VERSION "dbc-export 1 2026.26.6.5"

NS_ :

BS_:

BU_: ADSP APB APP APS APSB BB BMS CC CMP CMPD CP DAS DI DIF DIR DPB EPAS3P EPAS3S EPASTP EPASTS EPBL EPBR ESP EVSE FC GTW HCML HCMR HVP IBST ICR IDB LS OCS1P PARK PCS PCS2 PM PMF PMR PNCD PTC RADC RCM RCM2 RCM3 RCU SCCM SCM SCS SDCR TAS TCU TCU2 TPMS TRCM UI UIS UMC USM V2G VC VCBATT VCBATT0 VCBATT1 VCBATT2 VCCC VCFRONT VCFRONT1 VCFRONT2 VCLEFT VCRIGHT VCSEAT2L VCSEAT2R VCSEC VEH

BO_ 852 TAS_alertMatrix: 8 TAS
 SG_ TAS_matrixIndex M : 0|4@1+ (1,0) [0|15] "" Vector__XXX
 SG_ TAS_a001_WatchdogReset m0 : 4|1@1+ (1,0) [0|1] "" Vector__XXX
 SG_ TAS_a002_PowerLossReset m0 : 5|1@1+ (1,0) [0|1] "" Vector__XXX
 SG_ TAS_a003_SWAssertion m0 : 6|1@1+ (1,0) [0|1] "" Vector__XXX
 SG_ TAS_a012_CPUReset m0 : 15|1@1+ (1,0) [0|1] "" Vector__XXX
 SG_ TAS_a015_NVMMError m0 : 18|1@1+ (1,0) [0|1] "" Vector__XXX
 SG_ TAS_a016_NVMMRecordError m0 : 19|1@1+ (1,0) [0|1] "" Vector__XXX
 SG_ TAS_a021_TaskSchedulerError m0 : 24|1@1+ (1,0) [0|1] "" Vector__XXX
 SG_ TAS_a022_TaskInitError m0 : 25|1@1+ (1,0) [0|1] "" Vector__XXX
 SG_ TAS_a023_rtosResetRequested m0 : 26|1@1+ (1,0) [0|1] "" Vector__XXX
 SG_ TAS_a024_prefetchAbort m0 : 27|1@1+ (1,0) [0|1] "" Vector__XXX
 SG_ TAS_a025_CrashEvent m0 : 28|1@1+ (1,0) [0|1] "" Vector__XXX
 SG_ TAS_a030_PWMerrorFL m0 : 33|1@1+ (1,0) [0|1] "" Vector__XXX
 SG_ TAS_a031_PWMerrorFR m0 : 34|1@1+ (1,0) [0|1] "" Vector__XXX
 SG_ TAS_a032_PWMerrorRL m0 : 35|1@1+ (1,0) [0|1] "" Vector__XXX
 SG_ TAS_a033_PWMerrorRR m0 : 36|1@1+ (1,0) [0|1] "" Vector__XXX
 SG_ TAS_a034_PWMshortFL m0 : 37|1@1+ (1,0) [0|1] "" Vector__XXX
 SG_ TAS_a035_PWMshortFR m0 : 38|1@1+ (1,0) [0|1] "" Vector__XXX
 SG_ TAS_a036_PWMshortRL m0 : 39|1@1+ (1,0) [0|1] "" Vector__XXX
 SG_ TAS_a037_PWMshortRR m0 : 40|1@1+ (1,0) [0|1] "" Vector__XXX
 SG_ TAS_a038_PWMopenFL m0 : 41|1@1+ (1,0) [0|1] "" Vector__XXX
 SG_ TAS_a039_PWMopenFR m0 : 42|1@1+ (1,0) [0|1] "" Vector__XXX
 SG_ TAS_a040_PWMopenRL m0 : 43|1@1+ (1,0) [0|1] "" Vector__XXX
 SG_ TAS_a041_PWMopenRR m0 : 44|1@1+ (1,0) [0|1] "" Vector__XXX
 SG_ TAS_a043_Task1msError m0 : 46|1@1+ (1,0) [0|1] "" Vector__XXX
 SG_ TAS_a044_Task10msError m0 : 47|1@1+ (1,0) [0|1] "" Vector__XXX
 SG_ TAS_a045_Task100msError m0 : 48|1@1+ (1,0) [0|1] "" Vector__XXX
 SG_ TAS_a046_Task1000msError m0 : 49|1@1+ (1,0) [0|1] "" Vector__XXX
 SG_ TAS_a061_XCPConnected m1 : 4|1@1+ (1,0) [0|1] "" Vector__XXX
 SG_ TAS_a062_XCPWasConnected m1 : 5|1@1+ (1,0) [0|1] "" Vector__XXX
 SG_ TAS_a063_abortFault m1 : 6|1@1+ (1,0) [0|1] "" Vector__XXX
 SG_ TAS_a064_abortFaultExt m1 : 7|1@1+ (1,0) [0|1] "" Vector__XXX
 SG_ TAS_a065_ahbWriteFault m1 : 8|1@1+ (1,0) [0|1] "" Vector__XXX
 SG_ TAS_a066_undefinedInstructionAbo m1 : 9|1@1+ (1,0) [0|1] "" Vector__XXX
 SG_ TAS_a067_reservedHandlerAbort m1 : 10|1@1+ (1,0) [0|1] "" Vector__XXX
 SG_ TAS_a070_underVoltage12V m1 : 13|1@1+ (1,0) [0|1] "" Vector__XXX
 SG_ TAS_a071_overVoltage12V m1 : 14|1@1+ (1,0) [0|1] "" Vector__XXX
 SG_ TAS_a072_shortCircuit5VOnBoard m1 : 15|1@1+ (1,0) [0|1] "" Vector__XXX
 SG_ TAS_a073_underVoltage5VOnBoard m1 : 16|1@1+ (1,0) [0|1] "" Vector__XXX
 SG_ TAS_a074_shortCircuit5VOffBoard m1 : 17|1@1+ (1,0) [0|1] "" Vector__XXX
 SG_ TAS_a075_underVoltage5VOffBoard m1 : 18|1@1+ (1,0) [0|1] "" Vector__XXX
 SG_ TAS_a076_overVoltage5VOffBoard m1 : 19|1@1+ (1,0) [0|1] "" Vector__XXX
 SG_ TAS_a077_pressureSigVTooLow m1 : 20|1@1+ (1,0) [0|1] "" Vector__XXX
 SG_ TAS_a078_pressureSigVTooHigh m1 : 21|1@1+ (1,0) [0|1] "" Vector__XXX
 SG_ TAS_a080_shortCircuit5VHeight m1 : 23|1@1+ (1,0) [0|1] "" Vector__XXX
 SG_ TAS_a081_underVoltage5VHeight m1 : 24|1@1+ (1,0) [0|1] "" Vector__XXX
 SG_ TAS_a082_overVoltage5VHeight m1 : 25|1@1+ (1,0) [0|1] "" Vector__XXX
 SG_ TAS_a083_shortCircuit5VAnalog m1 : 26|1@1+ (1,0) [0|1] "" Vector__XXX
 SG_ TAS_a084_underVoltage5VAnalog m1 : 27|1@1+ (1,0) [0|1] "" Vector__XXX
 SG_ TAS_a085_overVoltage5VAnalog m1 : 28|1@1+ (1,0) [0|1] "" Vector__XXX
 SG_ TAS_a086_underVoltage12VSwtchd m1 : 29|1@1+ (1,0) [0|1] "" Vector__XXX
 SG_ TAS_a087_overVoltage12VSwtchd m1 : 30|1@1+ (1,0) [0|1] "" Vector__XXX
 SG_ TAS_a093_OTPError m1 : 36|1@1+ (1,0) [0|1] "" Vector__XXX
 SG_ TAS_a098_VCFRONT_MIA m1 : 41|1@1+ (1,0) [0|1] "" Vector__XXX
 SG_ TAS_a099_UI_MIA m1 : 42|1@1+ (1,0) [0|1] "" Vector__XXX
 SG_ TAS_a100_RCM_MIA m1 : 43|1@1+ (1,0) [0|1] "" Vector__XXX
 SG_ TAS_a101_ESP_MIA m1 : 44|1@1+ (1,0) [0|1] "" Vector__XXX
 SG_ TAS_a102_DI_MIA m1 : 45|1@1+ (1,0) [0|1] "" Vector__XXX
 SG_ TAS_a103_GTW_MIA m1 : 46|1@1+ (1,0) [0|1] "" Vector__XXX
 SG_ TAS_a105_ECUDebugMode m1 : 48|1@1+ (1,0) [0|1] "" Vector__XXX
 SG_ TAS_a106_HighCPULoad m1 : 49|1@1+ (1,0) [0|1] "" Vector__XXX
 SG_ TAS_a107_HighStackUsage m1 : 50|1@1+ (1,0) [0|1] "" Vector__XXX
 SG_ TAS_a150_accelAvgImplausible_FL_ m2 : 33|1@1+ (1,0) [0|1] "" Vector__XXX
 SG_ TAS_a151_accelAvgImplausible_FL_ m2 : 34|1@1+ (1,0) [0|1] "" Vector__XXX
 SG_ TAS_a152_accelAvgImplausible_FL_ m2 : 35|1@1+ (1,0) [0|1] "" Vector__XXX
 SG_ TAS_a153_accelAvgImplausible_FR_ m2 : 36|1@1+ (1,0) [0|1] "" Vector__XXX
 SG_ TAS_a154_accelAvgImplausible_FR_ m2 : 37|1@1+ (1,0) [0|1] "" Vector__XXX
 SG_ TAS_a155_accelAvgImplausible_FR_ m2 : 38|1@1+ (1,0) [0|1] "" Vector__XXX
 SG_ TAS_a156_accelAvgImplausible_RL_ m2 : 39|1@1+ (1,0) [0|1] "" Vector__XXX
 SG_ TAS_a157_accelAvgImplausible_RL_ m2 : 40|1@1+ (1,0) [0|1] "" Vector__XXX
 SG_ TAS_a158_accelAvgImplausible_RL_ m2 : 41|1@1+ (1,0) [0|1] "" Vector__XXX
 SG_ TAS_a159_accelAvgImplausible_RR_ m2 : 42|1@1+ (1,0) [0|1] "" Vector__XXX
 SG_ TAS_a160_accelAvgImplausible_RR_ m2 : 43|1@1+ (1,0) [0|1] "" Vector__XXX
 SG_ TAS_a161_accelAvgImplausible_RR_ m2 : 44|1@1+ (1,0) [0|1] "" Vector__XXX
 SG_ TAS_a164_damperSolenoidMismatch m2 : 47|1@1+ (1,0) [0|1] "" Vector__XXX
 SG_ TAS_a165_damperValveCompFL m2 : 48|1@1+ (1,0) [0|1] "" Vector__XXX
 SG_ TAS_a166_damperValveRbndFL m2 : 49|1@1+ (1,0) [0|1] "" Vector__XXX
 SG_ TAS_a167_damperValveCompFR m2 : 50|1@1+ (1,0) [0|1] "" Vector__XXX
 SG_ TAS_a168_damperValveRbndFR m2 : 51|1@1+ (1,0) [0|1] "" Vector__XXX
 SG_ TAS_a169_damperValveCompRL m2 : 52|1@1+ (1,0) [0|1] "" Vector__XXX
 SG_ TAS_a170_damperValveRbndRL m2 : 53|1@1+ (1,0) [0|1] "" Vector__XXX
 SG_ TAS_a171_damperValveCompRR m2 : 54|1@1+ (1,0) [0|1] "" Vector__XXX
 SG_ TAS_a172_damperValveRbndRR m2 : 55|1@1+ (1,0) [0|1] "" Vector__XXX
 SG_ TAS_a173_staticLeakDetectFL m2 : 56|1@1+ (1,0) [0|1] "" Vector__XXX
 SG_ TAS_a174_staticLeakDetectFR m2 : 57|1@1+ (1,0) [0|1] "" Vector__XXX
 SG_ TAS_a175_staticLeakDetectRL m2 : 58|1@1+ (1,0) [0|1] "" Vector__XXX
 SG_ TAS_a176_staticLeakDetectRR m2 : 59|1@1+ (1,0) [0|1] "" Vector__XXX
 SG_ TAS_a190_a2bFrontAxleFault m3 : 13|1@1+ (1,0) [0|1] "" Vector__XXX
 SG_ TAS_a191_a2bRearAxleFault m3 : 14|1@1+ (1,0) [0|1] "" Vector__XXX
 SG_ TAS_a192_rideHeightObserverDiver m3 : 15|1@1+ (1,0) [0|1] "" Vector__XXX
 SG_ TAS_a193_EPAS3P_MIA m3 : 16|1@1+ (1,0) [0|1] "" Vector__XXX
 SG_ TAS_a194_a2bFrontAxleDataError m3 : 17|1@1+ (1,0) [0|1] "" Vector__XXX
 SG_ TAS_a195_a2bRearAxleDataError m3 : 18|1@1+ (1,0) [0|1] "" Vector__XXX
 SG_ TAS_a196_adaptiveDampingUsingDSP m3 : 19|1@1+ (1,0) [0|1] "" Vector__XXX
 SG_ TAS_a197_invalidAdaptiveModeRequ m3 : 20|1@1+ (1,0) [0|1] "" Vector__XXX
 SG_ TAS_a198_a2bFrontAxleExtendedDis m3 : 21|1@1+ (1,0) [0|1] "" Vector__XXX
 SG_ TAS_a199_a2bRearAxleExtendedDisc m3 : 22|1@1+ (1,0) [0|1] "" Vector__XXX
 SG_ TAS_a200_jackModeActive m3 : 23|1@1+ (1,0) [0|1] "" Vector__XXX
 SG_ TAS_a201_low12VBattery m3 : 24|1@1+ (1,0) [0|1] "" Vector__XXX
 SG_ TAS_a210_outOfRangeCalibration m3 : 33|1@1+ (1,0) [0|1] "" Vector__XXX
 SG_ TAS_a211_noRideHeightCalib m3 : 34|1@1+ (1,0) [0|1] "" Vector__XXX
 SG_ TAS_a213_yellowWarningLamp m3 : 36|1@1+ (1,0) [0|1] "" Vector__XXX
 SG_ TAS_a214_redWarningLamp m3 : 37|1@1+ (1,0) [0|1] "" Vector__XXX
 SG_ TAS_a215_limpHomeMode10 m3 : 38|1@1+ (1,0) [0|1] "" Vector__XXX
 SG_ TAS_a216_limpHomeMode20 m3 : 39|1@1+ (1,0) [0|1] "" Vector__XXX
 SG_ TAS_a217_limpHomeMode30 m3 : 40|1@1+ (1,0) [0|1] "" Vector__XXX
 SG_ TAS_a218_limpHomeMode40 m3 : 41|1@1+ (1,0) [0|1] "" Vector__XXX
 SG_ TAS_a220_exhaustGalleryFault m3 : 43|1@1+ (1,0) [0|1] "" Vector__XXX
 SG_ TAS_a221_valveLeakDetected m3 : 44|1@1+ (1,0) [0|1] "" Vector__XXX
 SG_ TAS_a222_compressorPrefillFault m3 : 45|1@1+ (1,0) [0|1] "" Vector__XXX
 SG_ TAS_a223_blockedAirline m3 : 46|1@1+ (1,0) [0|1] "" Vector__XXX
 SG_ TAS_a224_openAirline m3 : 47|1@1+ (1,0) [0|1] "" Vector__XXX
 SG_ TAS_a225_galleryPressureTooHigh m3 : 48|1@1+ (1,0) [0|1] "" Vector__XXX
 SG_ TAS_a226_PWMfastDetectFL m3 : 49|1@1+ (1,0) [0|1] "" Vector__XXX
 SG_ TAS_a227_PWMfastDetectFR m3 : 50|1@1+ (1,0) [0|1] "" Vector__XXX
 SG_ TAS_a228_PWMfastDetectRL m3 : 51|1@1+ (1,0) [0|1] "" Vector__XXX
 SG_ TAS_a229_PWMfastDetectRR m3 : 52|1@1+ (1,0) [0|1] "" Vector__XXX
 SG_ TAS_a230_notifyGeofence m3 : 53|1@1+ (1,0) [0|1] "" Vector__XXX
 SG_ TAS_a231_notifyRoughRoadRaise m3 : 54|1@1+ (1,0) [0|1] "" Vector__XXX
 SG_ TAS_a232_suspensionTypeMismatch m3 : 55|1@1+ (1,0) [0|1] "" Vector__XXX
 SG_ TAS_a233_compressorStuckOn m3 : 56|1@1+ (1,0) [0|1] "" Vector__XXX
 SG_ TAS_a234_damperHydraulicMismatch m3 : 57|1@1+ (1,0) [0|1] "" Vector__XXX
 SG_ TAS_a240_airSpringLeak m3 : 63|1@1+ (1,0) [0|1] "" Vector__XXX
 SG_ TAS_a284_serviceRunModeActive m4 : 47|1@1+ (1,0) [0|1] "" Vector__XXX
 SG_ TAS_a285_twistSustainedUserVis m4 : 48|1@1+ (1,0) [0|1] "" Vector__XXX
 SG_ TAS_a286_driveCycleStats1 m4 : 49|1@1+ (1,0) [0|1] "" Vector__XXX
 SG_ TAS_a287_driveCycleStats2 m4 : 50|1@1+ (1,0) [0|1] "" Vector__XXX
 SG_ TAS_a288_driveCycleStats3 m4 : 51|1@1+ (1,0) [0|1] "" Vector__XXX
 SG_ TAS_a289_driveCycleStats4 m4 : 52|1@1+ (1,0) [0|1] "" Vector__XXX
 SG_ TAS_a290_twistSustainedAtSpeed m4 : 53|1@1+ (1,0) [0|1] "" Vector__XXX
 SG_ TAS_a291_frontAxleTooHigh m4 : 54|1@1+ (1,0) [0|1] "" Vector__XXX
 SG_ TAS_a292_rearAxleTooHigh m4 : 55|1@1+ (1,0) [0|1] "" Vector__XXX
 SG_ TAS_a293_frontAxleTooLow m4 : 56|1@1+ (1,0) [0|1] "" Vector__XXX
 SG_ TAS_a294_rearAxleTooLow m4 : 57|1@1+ (1,0) [0|1] "" Vector__XXX
 SG_ TAS_a295_targetHeightNotMet m4 : 58|1@1+ (1,0) [0|1] "" Vector__XXX
 SG_ TAS_a296_chassisTypeMismatch m4 : 59|1@1+ (1,0) [0|1] "" Vector__XXX
 SG_ TAS_a297_vinMismatch m4 : 60|1@1+ (1,0) [0|1] "" Vector__XXX
 SG_ TAS_a298_vinNotLearned m4 : 61|1@1+ (1,0) [0|1] "" Vector__XXX
 SG_ TAS_a299_offsetEstimateTooLarge m4 : 62|1@1+ (1,0) [0|1] "" Vector__XXX
 SG_ TAS_a300_offsetEstimateData1 m4 : 63|1@1+ (1,0) [0|1] "" Vector__XXX
 SG_ TAS_a301_offsetEstimateData2 m5 : 4|1@1+ (1,0) [0|1] "" Vector__XXX
 SG_ TAS_a303_massEstimateFrozen m5 : 6|1@1+ (1,0) [0|1] "" Vector__XXX
 SG_ TAS_a304_massEstimateFrozenData m5 : 7|1@1+ (1,0) [0|1] "" Vector__XXX
 SG_ TAS_a305_newEndstopPosition m5 : 8|1@1+ (1,0) [0|1] "" Vector__XXX
 SG_ TAS_a306_hardwareProtectFrozen m5 : 9|1@1+ (1,0) [0|1] "" Vector__XXX
 SG_ TAS_a307_endstopBoundaryComp m5 : 10|1@1+ (1,0) [0|1] "" Vector__XXX
 SG_ TAS_a308_endstopBoundaryRbnd m5 : 11|1@1+ (1,0) [0|1] "" Vector__XXX
 SG_ TAS_a309_controlFrozen m5 : 12|1@1+ (1,0) [0|1] "" Vector__XXX
 SG_ TAS_a310_controlFrozenData m5 : 13|1@1+ (1,0) [0|1] "" Vector__XXX
 SG_ TAS_a311_accelsMIA m5 : 14|1@1+ (1,0) [0|1] "" Vector__XXX
 SG_ TAS_a312_rotationalRatesMIA m5 : 15|1@1+ (1,0) [0|1] "" Vector__XXX
 SG_ TAS_a313_dampingCntrlDisabled m5 : 16|1@1+ (1,0) [0|1] "" Vector__XXX
 SG_ TAS_a314_dampingReduced m5 : 17|1@1+ (1,0) [0|1] "" Vector__XXX
 SG_ TAS_a315_pcbaHighTemp m5 : 18|1@1+ (1,0) [0|1] "" Vector__XXX
 SG_ TAS_a316_offsetsAccels m5 : 19|1@1+ (1,0) [0|1] "" Vector__XXX
 SG_ TAS_a317_offsetsRotationalRates m5 : 20|1@1+ (1,0) [0|1] "" Vector__XXX
 SG_ TAS_a318_dampingCntrlInputMIA m5 : 21|1@1+ (1,0) [0|1] "" Vector__XXX
 SG_ TAS_a319_drivetrainTypeMismatch m5 : 22|1@1+ (1,0) [0|1] "" Vector__XXX
 SG_ TAS_a320_offsetsRotationalRates m5 : 23|1@1+ (1,0) [0|1] "" Vector__XXX
 SG_ TAS_a321_speedBumpAttributes1 m5 : 24|1@1+ (1,0) [0|1] "" Vector__XXX
 SG_ TAS_a322_speedBumpAttributes2 m5 : 25|1@1+ (1,0) [0|1] "" Vector__XXX
 SG_ TAS_a332_levelingThresholds1 m5 : 35|1@1+ (1,0) [0|1] "" Vector__XXX
 SG_ TAS_a333_levelingThresholds2 m5 : 36|1@1+ (1,0) [0|1] "" Vector__XXX
 SG_ TAS_a343_damperValveControlCompF m5 : 46|1@1+ (1,0) [0|1] "" Vector__XXX
 SG_ TAS_a344_damperValveControlRbndF m5 : 47|1@1+ (1,0) [0|1] "" Vector__XXX
 SG_ TAS_a345_damperValveControlCompF m5 : 48|1@1+ (1,0) [0|1] "" Vector__XXX
 SG_ TAS_a346_damperValveControlRbndF m5 : 49|1@1+ (1,0) [0|1] "" Vector__XXX
 SG_ TAS_a347_damperValveControlCompR m5 : 50|1@1+ (1,0) [0|1] "" Vector__XXX
 SG_ TAS_a348_damperValveControlRbndR m5 : 51|1@1+ (1,0) [0|1] "" Vector__XXX
 SG_ TAS_a349_damperValveControlCompR m5 : 52|1@1+ (1,0) [0|1] "" Vector__XXX
 SG_ TAS_a350_damperValveControlRbndR m5 : 53|1@1+ (1,0) [0|1] "" Vector__XXX

BO_ 523 TAS_axleData: 8 TAS
 SG_ TAS_axleIndex M : 0|1@1+ (1,0) [0|1] "" Vector__XXX
 SG_ TAS_rawHeightFL m0 : 4|10@1+ (1,-512) [-512|511] "mm" Vector__XXX
 SG_ TAS_staticHeightEstimateFL m0 : 14|10@1+ (1,-512) [-512|511] "mm" Vector__XXX
 SG_ TAS_componentPressureFL m0 : 24|8@1+ (0.1,0) [0|25.5] "bara" Vector__XXX
 SG_ TAS_rawHeightFR m0 : 32|10@1+ (1,-512) [-512|511] "mm" Vector__XXX
 SG_ TAS_staticHeightEstimateFR m0 : 42|10@1+ (1,-512) [-512|511] "mm" Vector__XXX
 SG_ TAS_componentPressureFR m0 : 52|8@1+ (0.1,0) [0|25.5] "bara" Vector__XXX
 SG_ TAS_rawHeightRL m1 : 4|10@1+ (1,-512) [-512|511] "mm" Vector__XXX
 SG_ TAS_staticHeightEstimateRL m1 : 14|10@1+ (1,-512) [-512|511] "mm" Vector__XXX
 SG_ TAS_componentPressureRL m1 : 24|8@1+ (0.1,0) [0|25.5] "bara" Vector__XXX
 SG_ TAS_rawHeightRR m1 : 32|10@1+ (1,-512) [-512|511] "mm" Vector__XXX
 SG_ TAS_staticHeightEstimateRR m1 : 42|10@1+ (1,-512) [-512|511] "mm" Vector__XXX
 SG_ TAS_componentPressureRR m1 : 52|8@1+ (0.1,0) [0|25.5] "bara" Vector__XXX

BO_ 1398 TAS_dampingStates: 8 TAS
 SG_ TAS_endstopState : 0|1@1+ (1,0) [0|1] "" Vector__XXX
 SG_ TAS_continuousControlState : 1|1@1+ (1,0) [0|1] "" Vector__XXX
 SG_ TAS_activeTireTune : 2|1@1+ (1,0) [0|1] "" Vector__XXX
 SG_ TAS_roughnessRaiseReason : 3|2@1+ (1,0) [0|3] "" Vector__XXX
 SG_ TAS_frontMetricDrivesRear : 5|2@1+ (1,0) [0|3] "" Vector__XXX
 SG_ TAS_roadCondition : 8|8@1+ (0.005,0) [0|1.275] "-" Vector__XXX
 SG_ TAS_bellyProtect : 16|2@1+ (1,0) [0|3] "" Vector__XXX
 SG_ TAS_frontMetricDrivesFront : 18|2@1+ (1,0) [0|3] "" Vector__XXX
 SG_ TAS_speedBumpAxleFront : 20|3@1+ (1,0) [0|7] "" Vector__XXX
 SG_ TAS_speedBumpAxleRear : 23|3@1+ (1,0) [0|7] "" Vector__XXX
 SG_ TAS_holeProtectFL : 26|2@1+ (1,0) [0|3] "" Vector__XXX
 SG_ TAS_holeProtectFR : 28|2@1+ (1,0) [0|3] "" Vector__XXX
 SG_ TAS_holeProtectRL : 30|2@1+ (1,0) [0|3] "" Vector__XXX
 SG_ TAS_holeProtectRR : 32|2@1+ (1,0) [0|3] "" Vector__XXX
 SG_ TAS_stepProtectFL : 34|2@1+ (1,0) [0|3] "" Vector__XXX
 SG_ TAS_stepProtectFR : 36|2@1+ (1,0) [0|3] "" Vector__XXX
 SG_ TAS_stepProtectRL : 38|2@1+ (1,0) [0|3] "" Vector__XXX
 SG_ TAS_stepProtectRR : 40|2@1+ (1,0) [0|3] "" Vector__XXX
 SG_ TAS_FDUTorqueCorruptionScale : 42|4@1+ (0.075,0) [0|1.125] "-" Vector__XXX
 SG_ TAS_sprungMassEstimate : 46|5@1+ (64,1800) [1800|3784] "kg" Vector__XXX
 SG_ TAS_anyDamperActive : 51|1@1+ (1,0) [0|1] "" Vector__XXX
 SG_ TAS_dampingStatesCounter : 52|4@1+ (1,0) [0|15] "" Vector__XXX
 SG_ TAS_dampingStatesChecksum : 56|8@1+ (1,0) [0|255] "" Vector__XXX

BO_ 1357 TAS_info: 8 TAS
 SG_ TAS_infoIndex M : 0|8@1+ (1,0) [0|255] "" Vector__XXX
 SG_ TAS_infoBuildType m10 : 8|8@1+ (1,0) [0|255] "" Vector__XXX
 SG_ TAS_infoBuildConfigId m10 : 16|16@1+ (1,0) [0|65535] "" Vector__XXX
 SG_ TAS_infoHardwareId m10 : 32|1@1+ (1,0) [0|1] "" Vector__XXX
 SG_ TAS_infoComponentId m10 : 48|16@1+ (1,0) [0|65535] "" Vector__XXX
 SG_ TAS_infoPcbaId m11 : 16|8@1+ (1,0) [0|255] "" Vector__XXX
 SG_ TAS_infoAssemblyId m11 : 24|8@1+ (1,0) [0|255] "" Vector__XXX
 SG_ TAS_infoUsageId m11 : 32|16@1+ (1,0) [0|65535] "" Vector__XXX
 SG_ TAS_infoSubUsageId m11 : 48|16@1+ (1,0) [0|65535] "" Vector__XXX
 SG_ TAS_infoAppCrc m13 : 32|32@1+ (1,0) [0|4294967295] "" Vector__XXX
 SG_ TAS_infoAppGitHash m17 : 8|56@1+ (1,0) [0|7.20575940379e+16] "" Vector__XXX
 SG_ TAS_infoBootGitHash m18 : 8|56@1+ (1,0) [0|7.20575940379e+16] "" Vector__XXX
 SG_ TAS_infoPlatformType m19 : 8|8@1+ (1,0) [0|255] "" Vector__XXX
 SG_ TAS_infoMajorVersion m19 : 16|8@1+ (1,0) [0|255] "" Vector__XXX
 SG_ TAS_infoBranchOrigin m19 : 24|8@1+ (1,0) [0|255] "" Vector__XXX
 SG_ TAS_infoMaturity m19 : 32|8@1+ (1,0) [0|255] "" Vector__XXX
 SG_ TAS_infoHardwareRevision m19 : 40|8@1+ (1,0) [0|255] "" Vector__XXX

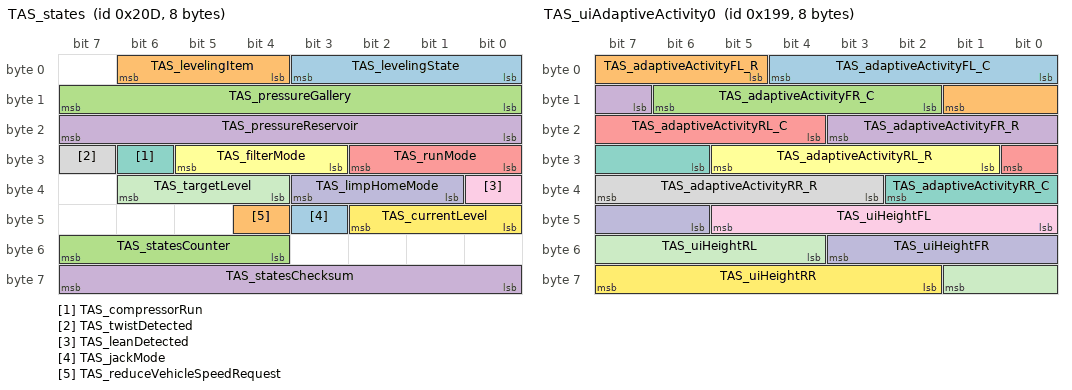
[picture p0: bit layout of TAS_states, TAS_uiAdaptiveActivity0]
BO_ 525 TAS_states: 8 TAS
 SG_ TAS_levelingState : 0|4@1+ (1,0) [0|15] "" Vector__XXX
 SG_ TAS_levelingItem : 4|3@1+ (1,0) [0|7] "" Vector__XXX
 SG_ TAS_pressureGallery : 8|8@1+ (0.1,0) [0|25.5] "bara" Vector__XXX
 SG_ TAS_pressureReservoir : 16|8@1+ (0.1,0) [0|25.5] "bara" Vector__XXX
 SG_ TAS_runMode : 24|3@1+ (1,0) [0|7] "" Vector__XXX
 SG_ TAS_filterMode : 27|3@1+ (1,0) [0|7] "" Vector__XXX
 SG_ TAS_compressorRun : 30|1@1+ (1,0) [0|1] "" Vector__XXX
 SG_ TAS_twistDetected : 31|1@1+ (1,0) [0|1] "" Vector__XXX
 SG_ TAS_leanDetected : 32|1@1+ (1,0) [0|1] "" Vector__XXX
 SG_ TAS_limpHomeMode : 33|3@1+ (1,0) [0|7] "" Vector__XXX
 SG_ TAS_targetLevel : 36|3@1+ (1,0) [0|7] "" Vector__XXX
 SG_ TAS_currentLevel : 40|3@1+ (1,0) [0|7] "" Vector__XXX
 SG_ TAS_jackMode : 43|1@1+ (1,0) [0|1] "" Vector__XXX
 SG_ TAS_reduceVehicleSpeedRequest : 44|1@1+ (1,0) [0|1] "" Vector__XXX
 SG_ TAS_statesCounter : 52|4@1+ (1,0) [0|15] "" Vector__XXX
 SG_ TAS_statesChecksum : 56|8@1+ (1,0) [0|255] "" Vector__XXX

BO_ 409 TAS_uiAdaptiveActivity0: 8 TAS
 SG_ TAS_adaptiveActivityFL_C : 0|5@1+ (0.04,0) [0|1] "-" Vector__XXX
 SG_ TAS_adaptiveActivityFL_R : 5|5@1+ (0.04,0) [0|1] "-" Vector__XXX
 SG_ TAS_adaptiveActivityFR_C : 10|5@1+ (0.04,0) [0|1] "-" Vector__XXX
 SG_ TAS_adaptiveActivityFR_R : 15|5@1+ (0.04,0) [0|1] "-" Vector__XXX
 SG_ TAS_adaptiveActivityRL_C : 20|5@1+ (0.04,0) [0|1] "-" Vector__XXX
 SG_ TAS_adaptiveActivityRL_R : 25|5@1+ (0.04,0) [0|1] "-" Vector__XXX
 SG_ TAS_adaptiveActivityRR_C : 30|5@1+ (0.04,0) [0|1] "-" Vector__XXX
 SG_ TAS_adaptiveActivityRR_R : 35|5@1+ (0.04,0) [0|1] "-" Vector__XXX
 SG_ TAS_uiHeightFL : 40|6@1+ (4,-128) [-128|124] "mm" Vector__XXX
 SG_ TAS_uiHeightFR : 46|6@1+ (4,-128) [-128|124] "mm" Vector__XXX
 SG_ TAS_uiHeightRL : 52|6@1+ (4,-128) [-128|124] "mm" Vector__XXX
 SG_ TAS_uiHeightRR : 58|6@1+ (4,-128) [-128|124] "mm" Vector__XXX

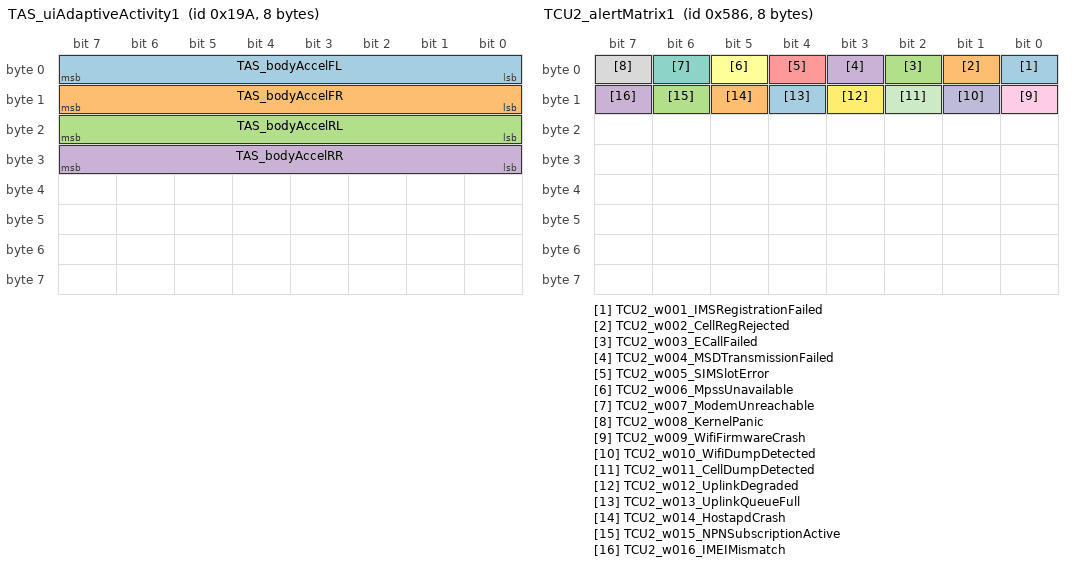
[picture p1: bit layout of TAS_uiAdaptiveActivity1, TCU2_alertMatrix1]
BO_ 410 TAS_uiAdaptiveActivity1: 8 TAS
 SG_ TAS_bodyAccelFL : 0|8@1+ (0.05,-5) [-5|5] "g" Vector__XXX
 SG_ TAS_bodyAccelFR : 8|8@1+ (0.05,-5) [-5|5] "g" Vector__XXX
 SG_ TAS_bodyAccelRL : 16|8@1+ (0.05,-5) [-5|5] "g" Vector__XXX
 SG_ TAS_bodyAccelRR : 24|8@1+ (0.05,-5) [-5|5] "g" Vector__XXX

BO_ 538 TAS_uiControl: 8 TAS
 SG_ TAS_yellowWarningLamp : 0|1@1+ (1,0) [0|1] "" Vector__XXX
 SG_ TAS_redWarningLamp : 1|1@1+ (1,0) [0|1] "" Vector__XXX
 SG_ TAS_veryLowAllowed : 2|1@1+ (1,0) [0|1] "" Vector__XXX
 SG_ TAS_lowAllowed : 3|1@1+ (1,0) [0|1] "" Vector__XXX
 SG_ TAS_standardAllowed : 4|1@1+ (1,0) [0|1] "" Vector__XXX
 SG_ TAS_highAllowed : 5|1@1+ (1,0) [0|1] "" Vector__XXX
 SG_ TAS_veryHighAllowed : 6|1@1+ (1,0) [0|1] "" Vector__XXX
 SG_ TAS_extractAllowed : 7|1@1+ (1,0) [0|1] "" Vector__XXX
 SG_ TAS_showSpinner : 9|1@1+ (1,0) [0|1] "" Vector__XXX
 SG_ TAS_adaptiveRideModeOverride : 10|2@1+ (1,0) [0|3] "" Vector__XXX
 SG_ TAS_levelSelectEnabled : 12|1@1+ (1,0) [0|1] "" Vector__XXX
 SG_ TAS_jackModeToggleEnabled : 13|1@1+ (1,0) [0|1] "" Vector__XXX
 SG_ TAS_adaptiveRideSelectEnabled : 14|1@1+ (1,0) [0|1] "" Vector__XXX
 SG_ TAS_launchModeState : 16|3@1+ (1,0) [0|7] "" Vector__XXX
 SG_ TAS_restrictUpLevelingFalcons : 19|1@1+ (1,0) [0|1] "" Vector__XXX
 SG_ TAS_restrictUpLevelingTrunk : 20|1@1+ (1,0) [0|1] "" Vector__XXX
 SG_ TAS_restrictDownLevelingDoors : 21|1@1+ (1,0) [0|1] "" Vector__XXX
 SG_ TAS_restrictLevelingChargeCable : 22|1@1+ (1,0) [0|1] "" Vector__XXX
 SG_ TAS_restrictLevelingSystemCheck : 23|1@1+ (1,0) [0|1] "" Vector__XXX
 SG_ TAS_restrictLevelingTransport : 24|1@1+ (1,0) [0|1] "" Vector__XXX
 SG_ TAS_restrictLevelingShowroom : 25|1@1+ (1,0) [0|1] "" Vector__XXX
 SG_ TAS_uiControlCounter : 28|4@1+ (1,0) [0|15] "" Vector__XXX
 SG_ TAS_uiControlChecksum : 32|8@1+ (1,0) [0|255] "" Vector__XXX

BO_ 1415 TCU2_SleepConfig: 8 TCU2
 SG_ TCU2_tc10Version : 0|2@1+ (1,0) [0|3] "" Vector__XXX

BO_ 1413 TCU2_alertLog: 8 TCU2
 SG_ TCU2_alertID M : 0|5@1+ (1,0) [0|31] "" Vector__XXX
 SG_ TCU2_alertState : 15|1@1+ (1,0) [0|1] "" Vector__XXX
 SG_ TCU2_w001_FailCode m1 : 16|32@1+ (1,0) [0|4294967295] "" Vector__XXX
 SG_ TCU2_w002_RejCause m2 : 16|32@1+ (1,0) [0|4294967295] "" Vector__XXX
 SG_ TCU2_w003_CallFailCode m3 : 16|32@1+ (1,0) [0|4294967295] "" Vector__XXX
 SG_ TCU2_w004_MSDFailCode m4 : 16|32@1+ (1,0) [0|4294967295] "" Vector__XXX
 SG_ TCU2_w006_Count m6 : 16|32@1+ (1,0) [0|4294967295] "" Vector__XXX
 SG_ TCU2_w007_Count m7 : 16|32@1+ (1,0) [0|4294967295] "" Vector__XXX
 SG_ TCU2_w009_CrashCode m9 : 16|32@1+ (1,0) [0|4294967295] "" Vector__XXX
 SG_ TCU2_w012_DataRAT m12 : 16|4@1+ (1,0) [0|15] "" Vector__XXX
 SG_ TCU2_w012_RSRP m12 : 20|8@1- (1,0) [-128|127] "" Vector__XXX
 SG_ TCU2_w012_RSRQ m12 : 28|7@1- (1,0) [-64|63] "" Vector__XXX
 SG_ TCU2_w012_MNC m12 : 45|10@1+ (1,0) [0|1023] "" Vector__XXX
 SG_ TCU2_w012_AvgQueueUsage m12 : 55|7@1+ (1,0) [0|127] "" Vector__XXX
 SG_ TCU2_w012_NSAAvailable m12 : 62|2@1+ (1,0) [0|3] "" Vector__XXX
 SG_ TCU2_w013_DataRAT m13 : 16|4@1+ (1,0) [0|15] "" Vector__XXX
 SG_ TCU2_w013_RSRP m13 : 20|8@1- (1,0) [-128|127] "" Vector__XXX
 SG_ TCU2_w013_RSRQ m13 : 28|7@1- (1,0) [-64|63] "" Vector__XXX
 SG_ TCU2_w013_MNC m13 : 45|10@1+ (1,0) [0|1023] "" Vector__XXX
 SG_ TCU2_w013_AvgQueueUsage m13 : 55|7@1+ (1,0) [0|127] "" Vector__XXX
 SG_ TCU2_w013_NSAAvailable m13 : 62|2@1+ (1,0) [0|3] "" Vector__XXX
 SG_ TCU2_w014_Reason m14 : 16|32@1- (1,0) [-2147483648|2147483647] "" Vector__XXX

BO_ 1414 TCU2_alertMatrix1: 8 TCU2
 SG_ TCU2_w001_IMSRegistrationFailed : 0|1@1+ (1,0) [0|1] "" Vector__XXX
 SG_ TCU2_w002_CellRegRejected : 1|1@1+ (1,0) [0|1] "" Vector__XXX
 SG_ TCU2_w003_ECallFailed : 2|1@1+ (1,0) [0|1] "" Vector__XXX
 SG_ TCU2_w004_MSDTransmissionFailed : 3|1@1+ (1,0) [0|1] "" Vector__XXX
 SG_ TCU2_w005_SIMSlotError : 4|1@1+ (1,0) [0|1] "" Vector__XXX
 SG_ TCU2_w006_MpssUnavailable : 5|1@1+ (1,0) [0|1] "" Vector__XXX
 SG_ TCU2_w007_ModemUnreachable : 6|1@1+ (1,0) [0|1] "" Vector__XXX
 SG_ TCU2_w008_KernelPanic : 7|1@1+ (1,0) [0|1] "" Vector__XXX
 SG_ TCU2_w009_WifiFirmwareCrash : 8|1@1+ (1,0) [0|1] "" Vector__XXX
 SG_ TCU2_w010_WifiDumpDetected : 9|1@1+ (1,0) [0|1] "" Vector__XXX
 SG_ TCU2_w011_CellDumpDetected : 10|1@1+ (1,0) [0|1] "" Vector__XXX
 SG_ TCU2_w012_UplinkDegraded : 11|1@1+ (1,0) [0|1] "" Vector__XXX
 SG_ TCU2_w013_UplinkQueueFull : 12|1@1+ (1,0) [0|1] "" Vector__XXX
 SG_ TCU2_w014_HostapdCrash : 13|1@1+ (1,0) [0|1] "" Vector__XXX
 SG_ TCU2_w015_NPNSubscriptionActive : 14|1@1+ (1,0) [0|1] "" Vector__XXX
 SG_ TCU2_w016_IMEIMismatch : 15|1@1+ (1,0) [0|1] "" Vector__XXX

BO_ 1412 TCU2_log: 8 TCU2
 SG_ TCU2_logMux M : 0|32@1+ (1,0) [0|4294967295] "" Vector__XXX
 SG_ TCU2_cpuTemp m0 : 32|32@1+ (1,0) [0|4294967295] "C" Vector__XXX
 SG_ TCU2_cpuUsage m1 : 32|32@1+ (1,0) [0|4294967295] "%" Vector__XXX
 SG_ TCU2_mdmCoreTemperature m2 : 32|32@1+ (1,0) [0|4294967295] "C" Vector__XXX
 SG_ TCU2_availableMemory m3 : 32|32@1+ (1,0) [0|4294967295] "KB" Vector__XXX
 SG_ TCU2_pwm m4 : 32|32@1+ (1,0) [0|4294967295] "" Vector__XXX
 SG_ TCU2_pwmcap m5 : 32|32@1+ (1,0) [0|4294967295] "" Vector__XXX
 SG_ TCU2_totalResumes m6 : 32|32@1+ (1,0) [0|4294967295] "" Vector__XXX
 SG_ TCU2_mdmUplinkQueueSize m7 : 32|32@1+ (1,0) [0|4294967295] "bytes" Vector__XXX
 SG_ TCU2_mdmRSRP m8 : 32|32@1- (1,0) [-2147483648|2147483647] "dBm" Vector__XXX
 SG_ TCU2_mdmSINR m9 : 32|32@1- (1,0) [-2147483648|2147483647] "dBm" Vector__XXX
 SG_ TCU2_mdmUplinkAllowedRate m10 : 32|32@1+ (1,0) [0|4294967295] "Kbps" Vector__XXX
 SG_ TCU2_mdmUplinkAvgRate m11 : 32|32@1+ (1,0) [0|4294967295] "Kbps" Vector__XXX
 SG_ TCU2_mdmServiceState m12 : 32|32@1+ (1,0) [0|4294967295] "" Vector__XXX
 SG_ TCU2_mdmIMSStatus m13 : 32|32@1+ (1,0) [0|4294967295] "" Vector__XXX
 SG_ TCU2_mdmSIMStatus m14 : 32|32@1+ (1,0) [0|4294967295] "" Vector__XXX
 SG_ TCU2_mdmBusyActive m15 : 32|32@1+ (1,0) [0|4294967295] "" Vector__XXX
 SG_ TCU2_modemUptime m16 : 32|32@1+ (1,0) [0|4294967295] "" Vector__XXX
 SG_ TCU2_mdmDataRat m17 : 32|3@1+ (1,0) [0|7] "" Vector__XXX
 SG_ TCU2_mdmDataCallStatus m18 : 32|3@1+ (1,0) [0|7] "" Vector__XXX
 SG_ TCU2_mdmNSAAvailable m19 : 32|2@1+ (1,0) [0|3] "" Vector__XXX
 SG_ TCU2_mdmPCIID m20 : 32|32@1+ (1,0) [0|4294967295] "" Vector__XXX
 SG_ TCU2_mdmMnc m21 : 32|32@1+ (1,0) [0|4294967295] "" Vector__XXX
 SG_ TCU2_mdmMcc m22 : 32|32@1+ (1,0) [0|4294967295] "" Vector__XXX
 SG_ TCU2_mdmTxKiloBytes m23 : 32|32@1+ (1,0) [0|4294967295] "KB" Vector__XXX
 SG_ TCU2_mdmDataCallTermReason m24 : 32|32@1+ (1,0) [0|4294967295] "" Vector__XXX
 SG_ TCU2_mdmDataCallTermCode m25 : 32|32@1+ (1,0) [0|4294967295] "" Vector__XXX
 SG_ TCU2_cellularSMState m26 : 32|32@1+ (1,0) [0|4294967295] "" Vector__XXX
 SG_ TCU2_tcuSMState m27 : 32|32@1+ (1,0) [0|4294967295] "" Vector__XXX
 SG_ TCU2_checkInternetFailCount m28 : 32|32@1+ (1,0) [0|4294967295] "" Vector__XXX
 SG_ TCU2_mdmBand m29 : 32|32@1+ (1,0) [0|4294967295] "" Vector__XXX
 SG_ TCU2_wakeSource m30 : 32|2@1+ (1,0) [0|3] "" Vector__XXX

BO_ 1159 TCU_SleepConfig: 8 TCU
 SG_ TCU_tc10Version : 0|2@1+ (1,0) [0|3] "" Vector__XXX

BO_ 1157 TCU_alertLog: 8 TCU
 SG_ TCU_alertID M : 0|5@1+ (1,0) [0|31] "" Vector__XXX
 SG_ TCU_alertState : 15|1@1+ (1,0) [0|1] "" Vector__XXX
 SG_ TCU_w001_FailCode m1 : 16|32@1+ (1,0) [0|4294967295] "" Vector__XXX
 SG_ TCU_w002_RejCause m2 : 16|32@1+ (1,0) [0|4294967295] "" Vector__XXX
 SG_ TCU_w003_CallFailCode m3 : 16|32@1+ (1,0) [0|4294967295] "" Vector__XXX
 SG_ TCU_w004_MSDFailCode m4 : 16|32@1+ (1,0) [0|4294967295] "" Vector__XXX
 SG_ TCU_w006_Count m6 : 16|32@1+ (1,0) [0|4294967295] "" Vector__XXX
 SG_ TCU_w007_Count m7 : 16|32@1+ (1,0) [0|4294967295] "" Vector__XXX
 SG_ TCU_w009_CrashCode m9 : 16|32@1+ (1,0) [0|4294967295] "" Vector__XXX
 SG_ TCU_w012_DataRAT m12 : 16|4@1+ (1,0) [0|15] "" Vector__XXX
 SG_ TCU_w012_RSRP m12 : 20|8@1- (1,0) [-128|127] "" Vector__XXX
 SG_ TCU_w012_RSRQ m12 : 28|7@1- (1,0) [-64|63] "" Vector__XXX
 SG_ TCU_w012_MNC m12 : 45|10@1+ (1,0) [0|1023] "" Vector__XXX
 SG_ TCU_w012_AvgQueueUsage m12 : 55|7@1+ (1,0) [0|127] "" Vector__XXX
 SG_ TCU_w012_NSAAvailable m12 : 62|2@1+ (1,0) [0|3] "" Vector__XXX
 SG_ TCU_w013_DataRAT m13 : 16|4@1+ (1,0) [0|15] "" Vector__XXX
 SG_ TCU_w013_RSRP m13 : 20|8@1- (1,0) [-128|127] "" Vector__XXX
 SG_ TCU_w013_RSRQ m13 : 28|7@1- (1,0) [-64|63] "" Vector__XXX
 SG_ TCU_w013_MNC m13 : 45|10@1+ (1,0) [0|1023] "" Vector__XXX
 SG_ TCU_w013_AvgQueueUsage m13 : 55|7@1+ (1,0) [0|127] "" Vector__XXX
 SG_ TCU_w013_NSAAvailable m13 : 62|2@1+ (1,0) [0|3] "" Vector__XXX
 SG_ TCU_w014_Reason m14 : 16|32@1- (1,0) [-2147483648|2147483647] "" Vector__XXX

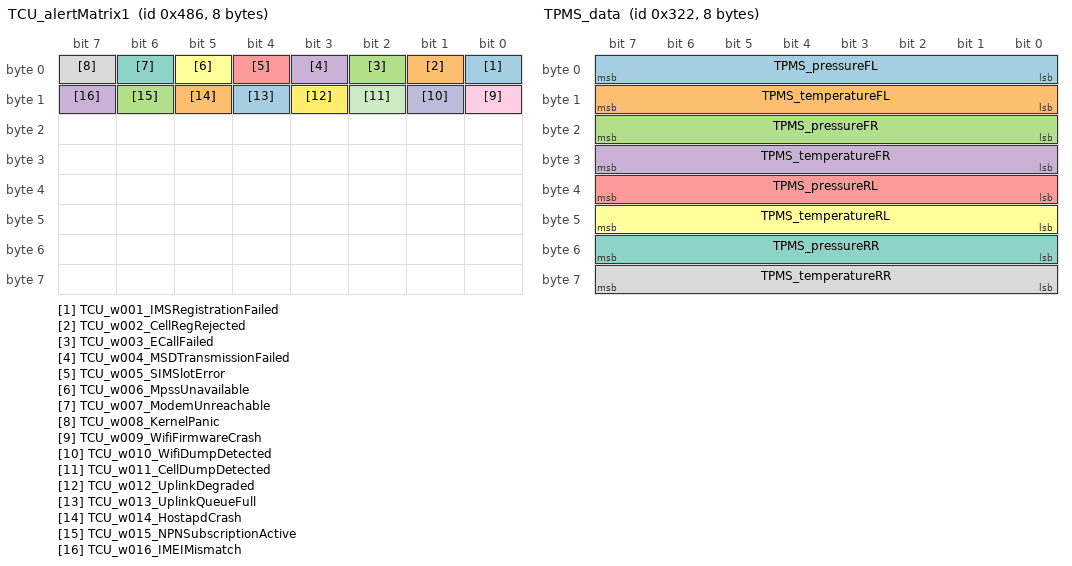
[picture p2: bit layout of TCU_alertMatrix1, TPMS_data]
BO_ 1158 TCU_alertMatrix1: 8 TCU
 SG_ TCU_w001_IMSRegistrationFailed : 0|1@1+ (1,0) [0|1] "" Vector__XXX
 SG_ TCU_w002_CellRegRejected : 1|1@1+ (1,0) [0|1] "" Vector__XXX
 SG_ TCU_w003_ECallFailed : 2|1@1+ (1,0) [0|1] "" Vector__XXX
 SG_ TCU_w004_MSDTransmissionFailed : 3|1@1+ (1,0) [0|1] "" Vector__XXX
 SG_ TCU_w005_SIMSlotError : 4|1@1+ (1,0) [0|1] "" Vector__XXX
 SG_ TCU_w006_MpssUnavailable : 5|1@1+ (1,0) [0|1] "" Vector__XXX
 SG_ TCU_w007_ModemUnreachable : 6|1@1+ (1,0) [0|1] "" Vector__XXX
 SG_ TCU_w008_KernelPanic : 7|1@1+ (1,0) [0|1] "" Vector__XXX
 SG_ TCU_w009_WifiFirmwareCrash : 8|1@1+ (1,0) [0|1] "" Vector__XXX
 SG_ TCU_w010_WifiDumpDetected : 9|1@1+ (1,0) [0|1] "" Vector__XXX
 SG_ TCU_w011_CellDumpDetected : 10|1@1+ (1,0) [0|1] "" Vector__XXX
 SG_ TCU_w012_UplinkDegraded : 11|1@1+ (1,0) [0|1] "" Vector__XXX
 SG_ TCU_w013_UplinkQueueFull : 12|1@1+ (1,0) [0|1] "" Vector__XXX
 SG_ TCU_w014_HostapdCrash : 13|1@1+ (1,0) [0|1] "" Vector__XXX
 SG_ TCU_w015_NPNSubscriptionActive : 14|1@1+ (1,0) [0|1] "" Vector__XXX
 SG_ TCU_w016_IMEIMismatch : 15|1@1+ (1,0) [0|1] "" Vector__XXX

BO_ 1155 TCU_log: 8 TCU
 SG_ TCU_logMux M : 0|32@1+ (1,0) [0|4294967295] "" Vector__XXX
 SG_ TCU_cpuTemp m0 : 32|32@1+ (1,0) [0|4294967295] "C" Vector__XXX
 SG_ TCU_cpuUsage m1 : 32|32@1+ (1,0) [0|4294967295] "%" Vector__XXX
 SG_ TCU_mdmCoreTemperature m2 : 32|32@1+ (1,0) [0|4294967295] "C" Vector__XXX
 SG_ TCU_availableMemory m3 : 32|32@1+ (1,0) [0|4294967295] "KB" Vector__XXX
 SG_ TCU_pwm m4 : 32|32@1+ (1,0) [0|4294967295] "" Vector__XXX
 SG_ TCU_pwmcap m5 : 32|32@1+ (1,0) [0|4294967295] "" Vector__XXX
 SG_ TCU_totalResumes m6 : 32|32@1+ (1,0) [0|4294967295] "" Vector__XXX
 SG_ TCU_mdmUplinkQueueSize m7 : 32|32@1+ (1,0) [0|4294967295] "bytes" Vector__XXX
 SG_ TCU_mdmRSRP m8 : 32|32@1- (1,0) [-2147483648|2147483647] "dBm" Vector__XXX
 SG_ TCU_mdmSINR m9 : 32|32@1- (1,0) [-2147483648|2147483647] "dBm" Vector__XXX
 SG_ TCU_mdmUplinkAllowedRate m10 : 32|32@1+ (1,0) [0|4294967295] "Kbps" Vector__XXX
 SG_ TCU_mdmUplinkAvgRate m11 : 32|32@1+ (1,0) [0|4294967295] "Kbps" Vector__XXX
 SG_ TCU_mdmServiceState m12 : 32|32@1+ (1,0) [0|4294967295] "" Vector__XXX
 SG_ TCU_mdmIMSStatus m13 : 32|32@1+ (1,0) [0|4294967295] "" Vector__XXX
 SG_ TCU_mdmSIMStatus m14 : 32|32@1+ (1,0) [0|4294967295] "" Vector__XXX
 SG_ TCU_mdmBusyActive m15 : 32|32@1+ (1,0) [0|4294967295] "" Vector__XXX
 SG_ TCU_modemUptime m16 : 32|32@1+ (1,0) [0|4294967295] "" Vector__XXX
 SG_ TCU_mdmDataRat m17 : 32|3@1+ (1,0) [0|7] "" Vector__XXX
 SG_ TCU_mdmDataCallStatus m18 : 32|3@1+ (1,0) [0|7] "" Vector__XXX
 SG_ TCU_mdmNSAAvailable m19 : 32|2@1+ (1,0) [0|3] "" Vector__XXX
 SG_ TCU_mdmPCIID m20 : 32|32@1+ (1,0) [0|4294967295] "" Vector__XXX
 SG_ TCU_mdmMnc m21 : 32|32@1+ (1,0) [0|4294967295] "" Vector__XXX
 SG_ TCU_mdmMcc m22 : 32|32@1+ (1,0) [0|4294967295] "" Vector__XXX
 SG_ TCU_mdmTxKiloBytes m23 : 32|32@1+ (1,0) [0|4294967295] "KB" Vector__XXX
 SG_ TCU_mdmDataCallTermReason m24 : 32|32@1+ (1,0) [0|4294967295] "" Vector__XXX
 SG_ TCU_mdmDataCallTermCode m25 : 32|32@1+ (1,0) [0|4294967295] "" Vector__XXX
 SG_ TCU_cellularSMState m26 : 32|32@1+ (1,0) [0|4294967295] "" Vector__XXX
 SG_ TCU_tcuSMState m27 : 32|32@1+ (1,0) [0|4294967295] "" Vector__XXX
 SG_ TCU_checkInternetFailCount m28 : 32|32@1+ (1,0) [0|4294967295] "" Vector__XXX
 SG_ TCU_mdmBand m29 : 32|32@1+ (1,0) [0|4294967295] "" Vector__XXX
 SG_ TCU_wakeSource m30 : 32|2@1+ (1,0) [0|3] "" Vector__XXX

BO_ 879 TPMS_StatusC: 8 TPMS
 SG_ TPMS_c_globalHardWarning : 0|1@1+ (1,0) [0|1] "" Vector__XXX
 SG_ TPMS_c_globalSoftWarning : 1|1@1+ (1,0) [0|1] "" Vector__XXX
 SG_ TPMS_systemMalfunction : 2|1@1+ (1,0) [0|1] "" Vector__XXX
 SG_ TPMS_WA_version : 3|1@1+ (1,0) [0|1] "" Vector__XXX
 SG_ TPMS_globalDeltaPressure : 4|1@1+ (1,0) [0|1] "" Vector__XXX
 SG_ TPMS_newSensorLearnt : 5|3@1+ (1,0) [0|7] "" Vector__XXX
 SG_ TPMS_softWarningRR : 8|1@1+ (1,0) [0|1] "" Vector__XXX
 SG_ TPMS_hardWarningRR : 9|1@1+ (1,0) [0|1] "" Vector__XXX
 SG_ TPMS_softWarningRL : 10|1@1+ (1,0) [0|1] "" Vector__XXX
 SG_ TPMS_hardWarningRL : 11|1@1+ (1,0) [0|1] "" Vector__XXX
 SG_ TPMS_softWarningFR : 12|1@1+ (1,0) [0|1] "" Vector__XXX
 SG_ TPMS_hardWarningFR : 13|1@1+ (1,0) [0|1] "" Vector__XXX
 SG_ TPMS_softWarningFL : 14|1@1+ (1,0) [0|1] "" Vector__XXX
 SG_ TPMS_hardWarningFL : 15|1@1+ (1,0) [0|1] "" Vector__XXX
 SG_ TPMS_learningStatus : 16|2@1+ (1,0) [0|3] "" Vector__XXX
 SG_ TPMS_localisationStatus : 18|2@1+ (1,0) [0|3] "" Vector__XXX
 SG_ TPMS_deltaPressWarningFL : 20|1@1+ (1,0) [0|1] "" Vector__XXX
 SG_ TPMS_deltaPressWarningFR : 21|1@1+ (1,0) [0|1] "" Vector__XXX
 SG_ TPMS_deltaPressWarningRL : 22|1@1+ (1,0) [0|1] "" Vector__XXX
 SG_ TPMS_deltaPressWarningRR : 23|1@1+ (1,0) [0|1] "" Vector__XXX
 SG_ TPMS_sensorNoResponseFL : 24|1@1+ (1,0) [0|1] "" Vector__XXX
 SG_ TPMS_sensorNoResponseFR : 25|1@1+ (1,0) [0|1] "" Vector__XXX
 SG_ TPMS_sensorNoResponseRL : 26|1@1+ (1,0) [0|1] "" Vector__XXX
 SG_ TPMS_sensorNoResponseRR : 27|1@1+ (1,0) [0|1] "" Vector__XXX
 SG_ TPMS_sensorThermShutdownFL : 28|1@1+ (1,0) [0|1] "" Vector__XXX
 SG_ TPMS_sensorThermShutdownFR : 29|1@1+ (1,0) [0|1] "" Vector__XXX
 SG_ TPMS_sensorThermShutdownRL : 30|1@1+ (1,0) [0|1] "" Vector__XXX
 SG_ TPMS_sensorThermShutdownRR : 31|1@1+ (1,0) [0|1] "" Vector__XXX
 SG_ TPMS_sensorBatteryLowFL : 32|1@1+ (1,0) [0|1] "" Vector__XXX
 SG_ TPMS_sensorBatteryLowFR : 33|1@1+ (1,0) [0|1] "" Vector__XXX
 SG_ TPMS_sensorBatteryLowRL : 34|1@1+ (1,0) [0|1] "" Vector__XXX
 SG_ TPMS_sensorBatteryLowRR : 35|1@1+ (1,0) [0|1] "" Vector__XXX
 SG_ TPMS_sensorDefectiveFL : 36|1@1+ (1,0) [0|1] "" Vector__XXX
 SG_ TPMS_sensorDefectiveFR : 37|1@1+ (1,0) [0|1] "" Vector__XXX
 SG_ TPMS_sensorDefectiveRL : 38|1@1+ (1,0) [0|1] "" Vector__XXX
 SG_ TPMS_sensorDefectiveRR : 39|1@1+ (1,0) [0|1] "" Vector__XXX
 SG_ TPMS_ecuUnderVoltage : 40|1@1+ (1,0) [0|1] "" Vector__XXX
 SG_ TPMS_ecuOverVoltage : 41|1@1+ (1,0) [0|1] "" Vector__XXX
 SG_ TPMS_ecuRamRomNvMFail : 42|1@1+ (1,0) [0|1] "" Vector__XXX
 SG_ TPMS_rfReceiverFail : 43|1@1+ (1,0) [0|1] "" Vector__XXX
 SG_ TPMS_wheelPulseMissing : 44|1@1+ (1,0) [0|1] "" Vector__XXX
 SG_ TPMS_vehicleSpeedFail : 45|1@1+ (1,0) [0|1] "" Vector__XXX
 SG_ TPMS_externalTemperatureFail : 46|1@1+ (1,0) [0|1] "" Vector__XXX
 SG_ TPMS_eolNotCompleted : 47|1@1+ (1,0) [0|1] "" Vector__XXX
 SG_ TPMS_rcpFront : 48|8@1+ (0.025,0) [0|6.375] "bar" Vector__XXX
 SG_ TPMS_rcpRear : 56|8@1+ (0.025,0) [0|6.375] "bar" Vector__XXX

BO_ 802 TPMS_data: 8 TPMS
 SG_ TPMS_pressureFL : 0|8@1+ (0.025,0) [0|6.375] "bar" Vector__XXX
 SG_ TPMS_temperatureFL : 8|8@1+ (1,-40) [-40|215] "degC" Vector__XXX
 SG_ TPMS_pressureFR : 16|8@1+ (0.025,0) [0|6.375] "bar" Vector__XXX
 SG_ TPMS_temperatureFR : 24|8@1+ (1,-40) [-40|215] "degC" Vector__XXX
 SG_ TPMS_pressureRL : 32|8@1+ (0.025,0) [0|6.375] "bar" Vector__XXX
 SG_ TPMS_temperatureRL : 40|8@1+ (1,-40) [-40|215] "degC" Vector__XXX
 SG_ TPMS_pressureRR : 48|8@1+ (0.025,0) [0|6.375] "bar" Vector__XXX
 SG_ TPMS_temperatureRR : 56|8@1+ (1,-40) [-40|215] "degC" Vector__XXX

BO_ 1519 TPMS_info: 8 TPMS
 SG_ TPMS_infoIndex M : 0|8@1+ (1,0) [0|255] "" Vector__XXX
 SG_ TPMS_infoComponentID m10 : 48|16@1+ (1,0) [0|65535] "" Vector__XXX
 SG_ TPMS_infoPcbaID m11 : 16|8@1+ (1,0) [0|255] "" Vector__XXX
 SG_ TPMS_infoAssemblyID m11 : 24|8@1+ (1,0) [0|255] "" Vector__XXX
 SG_ TPMS_infoUsageID m11 : 32|16@1+ (1,0) [0|65535] "" Vector__XXX
 SG_ TPMS_infoApplicationCRC m13 : 32|32@1+ (1,0) [0|4294967295] "" Vector__XXX
 SG_ TPMS_infoBootUdsProtoVersion m20 : 8|8@1+ (1,0) [0|255] "" Vector__XXX
 SG_ TPMS_infoBootloaderCRC m20 : 32|32@1+ (1,0) [0|4294967295] "" Vector__XXX

BO_ 1298 TRCM_alertLog: 8 TRCM
 SG_ TRCM_alertID M : 0|10@1+ (1,0) [0|1023] "" Vector__XXX
 SG_ TRCM_alertState : 15|1@1+ (1,0) [0|1] "" Vector__XXX
 SG_ TRCM_a015_NVMMMemOverflow m15 : 16|1@1+ (1,0) [0|1] "" Vector__XXX
 SG_ TRCM_a015_NVMMFilesystemError m15 : 17|1@1+ (1,0) [0|1] "" Vector__XXX
 SG_ TRCM_a015_NVMMRecordIDError m15 : 18|1@1+ (1,0) [0|1] "" Vector__XXX
 SG_ TRCM_a017_tempData m17 : 16|16@1- (0.06897,25) [-2235.00896|2284.93999] "" Vector__XXX
 SG_ TRCM_a018_tempData m18 : 16|16@1- (0.06897,25) [-2235.00896|2284.93999] "" Vector__XXX
 SG_ TRCM_a035_eventArmStatus m35 : 25|1@1+ (1,0) [0|1] "" Vector__XXX
 SG_ TRCM_a035_eventFrontLeftSeatbelt m35 : 30|1@1+ (1,0) [0|1] "" Vector__XXX
 SG_ TRCM_a035_eventFrontRightSeatbel m35 : 31|1@1+ (1,0) [0|1] "" Vector__XXX
 SG_ TRCM_a035_eventVehicleSpeed m35 : 32|12@1+ (0.08,-40) [-40|287.6] "" Vector__XXX
 SG_ TRCM_a035_eventDriverBrakeApply m35 : 48|2@1+ (1,0) [0|3] "" Vector__XXX
 SG_ TRCM_a035_eventAccelPedalPos m35 : 56|8@1+ (0.4,0) [0|102] "" Vector__XXX
 SG_ TRCM_a036_collisionType m36 : 16|4@1+ (1,0) [0|15] "" Vector__XXX
 SG_ TRCM_a036_collisionSeverity m36 : 20|2@1+ (1,0) [0|3] "" Vector__XXX
 SG_ TRCM_a036_eventArmStatus m36 : 25|1@1+ (1,0) [0|1] "" Vector__XXX
 SG_ TRCM_a036_eventFrontLeftSeatbelt m36 : 30|1@1+ (1,0) [0|1] "" Vector__XXX
 SG_ TRCM_a036_eventFrontRightSeatbel m36 : 31|1@1+ (1,0) [0|1] "" Vector__XXX
 SG_ TRCM_a036_eventVehicleSpeed m36 : 32|12@1+ (0.08,-40) [-40|287.6] "" Vector__XXX
 SG_ TRCM_a036_eventDriverBrakeApply m36 : 48|2@1+ (1,0) [0|3] "" Vector__XXX
 SG_ TRCM_a036_eventAccelPedalPos m36 : 56|8@1+ (0.4,0) [0|102] "" Vector__XXX
 SG_ TRCM_a037_nearDeployFront m37 : 16|1@1+ (1,0) [0|1] "" Vector__XXX
 SG_ TRCM_a037_nearDeployRear m37 : 17|1@1+ (1,0) [0|1] "" Vector__XXX
 SG_ TRCM_a037_nearDeployLeft m37 : 18|1@1+ (1,0) [0|1] "" Vector__XXX
 SG_ TRCM_a037_nearDeployRight m37 : 19|1@1+ (1,0) [0|1] "" Vector__XXX
 SG_ TRCM_a037_nearDeployRoll m37 : 20|1@1+ (1,0) [0|1] "" Vector__XXX
 SG_ TRCM_a037_eventArmStatus m37 : 25|1@1+ (1,0) [0|1] "" Vector__XXX
 SG_ TRCM_a037_eventFrontLeftSeatbelt m37 : 30|1@1+ (1,0) [0|1] "" Vector__XXX
 SG_ TRCM_a037_eventFrontRightSeatbel m37 : 31|1@1+ (1,0) [0|1] "" Vector__XXX
 SG_ TRCM_a037_eventVehicleSpeed m37 : 32|12@1+ (0.08,-40) [-40|287.6] "" Vector__XXX
 SG_ TRCM_a037_eventDriverBrakeApply m37 : 48|2@1+ (1,0) [0|3] "" Vector__XXX
 SG_ TRCM_a037_eventAccelPedalPos m37 : 56|8@1+ (0.4,0) [0|102] "" Vector__XXX
 SG_ TRCM_a038_stuckLowOrOpenCircuit m38 : 16|1@1+ (1,0) [0|1] "" Vector__XXX
 SG_ TRCM_a038_stuckHigh m38 : 17|1@1+ (1,0) [0|1] "" Vector__XXX
 SG_ TRCM_a038_overCurrent m38 : 18|1@1+ (1,0) [0|1] "" Vector__XXX
 SG_ TRCM_a038_driverOverTemperature m38 : 19|1@1+ (1,0) [0|1] "" Vector__XXX
 SG_ TRCM_a039_stuckLowOrOpenCircuit m39 : 16|1@1+ (1,0) [0|1] "" Vector__XXX
 SG_ TRCM_a039_stuckHigh m39 : 17|1@1+ (1,0) [0|1] "" Vector__XXX
 SG_ TRCM_a039_overCurrent m39 : 18|1@1+ (1,0) [0|1] "" Vector__XXX
 SG_ TRCM_a039_driverOverTemperature m39 : 19|1@1+ (1,0) [0|1] "" Vector__XXX
 SG_ TRCM_a057_VEH_cpControl m57 : 16|1@1+ (1,0) [0|1] "" Vector__XXX
 SG_ TRCM_a059_voltageDrop m59 : 16|12@1+ (0.005443676,0) [0|22.29185322] "" Vector__XXX
 SG_ TRCM_a059_resistanceEstimate m59 : 28|12@1+ (0.00244,0) [0|9.9918] "" Vector__XXX
 SG_ TRCM_a059_current m59 : 40|12@1+ (0.05,0) [0|204.75] "" Vector__XXX
 SG_ TRCM_a063_switchChannel m63 : 16|8@1+ (1,0) [0|255] "" Vector__XXX
 SG_ TRCM_a063_switchType m63 : 24|8@1+ (1,0) [0|255] "" Vector__XXX
 SG_ TRCM_a063_ADCVoltage m63 : 32|8@1+ (0.025,0) [0|6.375] "" Vector__XXX
 SG_ TRCM_a063_disconnected m63 : 40|1@1+ (1,0) [0|1] "" Vector__XXX
 SG_ TRCM_a063_indeterminate m63 : 41|1@1+ (1,0) [0|1] "" Vector__XXX
 SG_ TRCM_a063_stuckActive m63 : 42|1@1+ (1,0) [0|1] "" Vector__XXX
 SG_ TRCM_a063_faulted m63 : 43|1@1+ (1,0) [0|1] "" Vector__XXX
 SG_ TRCM_a065_vsafingFetVoltage m65 : 16|9@1+ (0.05,0) [0|25.55] "" Vector__XXX
 SG_ TRCM_a066_busVoltage m66 : 16|9@1+ (0.05,0) [0|25.55] "" Vector__XXX
 SG_ TRCM_a078_channelIndex m78 : 16|8@1+ (1,0) [0|255] "" Vector__XXX
 SG_ TRCM_a078_value m78 : 24|16@1- (1,0) [-32768|32767] "" Vector__XXX
 SG_ TRCM_a081_eventArmStatus m81 : 25|1@1+ (1,0) [0|1] "" Vector__XXX
 SG_ TRCM_a081_eventFrontLeftSeatbelt m81 : 30|1@1+ (1,0) [0|1] "" Vector__XXX
 SG_ TRCM_a081_eventFrontRightSeatbel m81 : 31|1@1+ (1,0) [0|1] "" Vector__XXX
 SG_ TRCM_a081_eventVehicleSpeed m81 : 32|12@1+ (0.08,-40) [-40|287.6] "" Vector__XXX
 SG_ TRCM_a081_eventDriverBrakeApply m81 : 48|2@1+ (1,0) [0|3] "" Vector__XXX
 SG_ TRCM_a081_eventAccelPedalPos m81 : 56|8@1+ (0.4,0) [0|102] "" Vector__XXX
 SG_ TRCM_a082_RIPC_epbPrivateState m82 : 16|1@1+ (1,0) [0|1] "" Vector__XXX
 SG_ TRCM_a082_RIPC_remoteHSD m82 : 17|1@1+ (1,0) [0|1] "" Vector__XXX
 SG_ TRCM_a082_RIPC_railStatus m82 : 18|1@1+ (1,0) [0|1] "" Vector__XXX
 SG_ TRCM_a082_RIPC_remoteMux m82 : 19|1@1+ (1,0) [0|1] "" Vector__XXX
 SG_ TRCM_a083_LIPC_epbPrivateState m83 : 16|1@1+ (1,0) [0|1] "" Vector__XXX
 SG_ TRCM_a083_LIPC_remoteHSD m83 : 17|1@1+ (1,0) [0|1] "" Vector__XXX
 SG_ TRCM_a083_LIPC_railStatus m83 : 18|1@1+ (1,0) [0|1] "" Vector__XXX
 SG_ TRCM_a083_LIPC_HSDFaults m83 : 19|1@1+ (1,0) [0|1] "" Vector__XXX
 SG_ TRCM_a084_CH_StatusC m84 : 16|1@1+ (1,0) [0|1] "" Vector__XXX
 SG_ TRCM_a085_PARTY_buttonStatus m85 : 16|1@1+ (1,0) [0|1] "" Vector__XXX
 SG_ TRCM_a086_VEH_LVBMS_statusHigh m86 : 16|1@1+ (1,0) [0|1] "" Vector__XXX
 SG_ TRCM_a086_VEH_LVBMS_statusLow m86 : 17|1@1+ (1,0) [0|1] "" Vector__XXX
 SG_ TRCM_a086_VEH_status m86 : 18|1@1+ (1,0) [0|1] "" Vector__XXX
 SG_ TRCM_a086_VEH_12VBatteryStatus m86 : 19|1@1+ (1,0) [0|1] "" Vector__XXX
 SG_ TRCM_a086_VEH_LVPowerState m86 : 20|1@1+ (1,0) [0|1] "" Vector__XXX
 SG_ TRCM_a086_VEH_lightStatus m86 : 21|1@1+ (1,0) [0|1] "" Vector__XXX
 SG_ TRCM_a086_VEH_systemStatus m86 : 22|1@1+ (1,0) [0|1] "" Vector__XXX
 SG_ TRCM_a086_VEH_thermalStatus m86 : 23|1@1+ (1,0) [0|1] "" Vector__XXX
 SG_ TRCM_a086_VEH_vehNm m86 : 24|1@1+ (1,0) [0|1] "" Vector__XXX
 SG_ TRCM_a087_VEH_temperature m87 : 16|1@1+ (1,0) [0|1] "" Vector__XXX
 SG_ TRCM_a087_VEH_thermalControl m87 : 17|1@1+ (1,0) [0|1] "" Vector__XXX
 SG_ TRCM_a087_VEH_torque m87 : 18|1@1+ (1,0) [0|1] "" Vector__XXX
 SG_ TRCM_a087_VEH_status m87 : 19|1@1+ (1,0) [0|1] "" Vector__XXX
 SG_ TRCM_a087_PARTY_torque m87 : 20|1@1+ (1,0) [0|1] "" Vector__XXX
 SG_ TRCM_a087_PARTY_status m87 : 21|1@1+ (1,0) [0|1] "" Vector__XXX
 SG_ TRCM_a087_PARTY_temperature m87 : 22|1@1+ (1,0) [0|1] "" Vector__XXX
 SG_ TRCM_a087_PARTY_thermalControl m87 : 23|1@1+ (1,0) [0|1] "" Vector__XXX
 SG_ TRCM_a087_VEH_motorStatus m87 : 24|1@1+ (1,0) [0|1] "" Vector__XXX
 SG_ TRCM_a088_VEH_temperature m88 : 16|1@1+ (1,0) [0|1] "" Vector__XXX
 SG_ TRCM_a088_VEH_thermalControl m88 : 17|1@1+ (1,0) [0|1] "" Vector__XXX
 SG_ TRCM_a088_VEH_torque m88 : 18|1@1+ (1,0) [0|1] "" Vector__XXX
 SG_ TRCM_a088_VEH_status m88 : 19|1@1+ (1,0) [0|1] "" Vector__XXX
 SG_ TRCM_a088_PARTY_torque m88 : 20|1@1+ (1,0) [0|1] "" Vector__XXX
 SG_ TRCM_a088_PARTY_status m88 : 21|1@1+ (1,0) [0|1] "" Vector__XXX
 SG_ TRCM_a088_PARTY_temperature m88 : 22|1@1+ (1,0) [0|1] "" Vector__XXX
 SG_ TRCM_a088_PARTY_thermalControl m88 : 23|1@1+ (1,0) [0|1] "" Vector__XXX
 SG_ TRCM_a088_VEH_motorStatus m88 : 24|1@1+ (1,0) [0|1] "" Vector__XXX
 SG_ TRCM_a089_PARTY_party1 m89 : 16|1@1+ (1,0) [0|1] "" Vector__XXX
 SG_ TRCM_a089_PARTY_status m89 : 17|1@1+ (1,0) [0|1] "" Vector__XXX
 SG_ TRCM_a089_VEH_status m89 : 18|1@1+ (1,0) [0|1] "" Vector__XXX
 SG_ TRCM_a089_BDY_party1 m89 : 19|1@1+ (1,0) [0|1] "" Vector__XXX
 SG_ TRCM_a089_BDY_status m89 : 20|1@1+ (1,0) [0|1] "" Vector__XXX
 SG_ TRCM_a089_CH_status m89 : 21|1@1+ (1,0) [0|1] "" Vector__XXX
 SG_ TRCM_a089_CH_party1 m89 : 22|1@1+ (1,0) [0|1] "" Vector__XXX
 SG_ TRCM_a089_CH_party3 m89 : 23|1@1+ (1,0) [0|1] "" Vector__XXX
 SG_ TRCM_a089_VEH_party1 m89 : 24|1@1+ (1,0) [0|1] "" Vector__XXX
 SG_ TRCM_a089_VEH_party3 m89 : 25|1@1+ (1,0) [0|1] "" Vector__XXX
 SG_ TRCM_a091_VEH_faultsAndExtras m91 : 16|1@1+ (1,0) [0|1] "" Vector__XXX
 SG_ TRCM_a091_VEH_info m91 : 17|1@1+ (1,0) [0|1] "" Vector__XXX
 SG_ TRCM_a091_VEH_state m91 : 18|1@1+ (1,0) [0|1] "" Vector__XXX
 SG_ TRCM_a092_VEH_restraintStatus m92 : 16|1@1+ (1,0) [0|1] "" Vector__XXX
 SG_ TRCM_a092_VEH_switchStatus m92 : 17|1@1+ (1,0) [0|1] "" Vector__XXX
 SG_ TRCM_a092_VEH_seatStatus2 m92 : 18|1@1+ (1,0) [0|1] "" Vector__XXX
 SG_ TRCM_a092_VEH_vehNm m92 : 19|1@1+ (1,0) [0|1] "" Vector__XXX
 SG_ TRCM_a093_VEH_restraintStatus m93 : 16|1@1+ (1,0) [0|1] "" Vector__XXX
 SG_ TRCM_a093_VEH_switchStatus m93 : 17|1@1+ (1,0) [0|1] "" Vector__XXX
 SG_ TRCM_a093_VEH_seatStatus2 m93 : 18|1@1+ (1,0) [0|1] "" Vector__XXX
 SG_ TRCM_a093_VEH_vehNm m93 : 19|1@1+ (1,0) [0|1] "" Vector__XXX
 SG_ TRCM_a094_VEH_sysStatus m94 : 16|1@1+ (1,0) [0|1] "" Vector__XXX
 SG_ TRCM_a094_PARTY_sysStatus m94 : 17|1@1+ (1,0) [0|1] "" Vector__XXX
 SG_ TRCM_a094_CH_sysStatus m94 : 18|1@1+ (1,0) [0|1] "" Vector__XXX
 SG_ TRCM_a095_PT_ptNm m95 : 16|1@1+ (1,0) [0|1] "" Vector__XXX
 SG_ TRCM_a095_PT_status m95 : 17|1@1+ (1,0) [0|1] "" Vector__XXX
 SG_ TRCM_a096_VEH_status m96 : 16|1@1+ (1,0) [0|1] "" Vector__XXX
 SG_ TRCM_a096_CH_status m96 : 17|1@1+ (1,0) [0|1] "" Vector__XXX
 SG_ TRCM_a097_VEH_HVStatus m97 : 16|1@1+ (1,0) [0|1] "" Vector__XXX
 SG_ TRCM_a097_VEH_state m97 : 17|1@1+ (1,0) [0|1] "" Vector__XXX
 SG_ TRCM_a098_CH_torque m98 : 16|1@1+ (1,0) [0|1] "" Vector__XXX
 SG_ TRCM_a098_VEH_hvStatus m98 : 17|1@1+ (1,0) [0|1] "" Vector__XXX
 SG_ TRCM_a098_VEH_status m98 : 18|1@1+ (1,0) [0|1] "" Vector__XXX
 SG_ TRCM_a098_VEH_thermalControl m98 : 19|1@1+ (1,0) [0|1] "" Vector__XXX
 SG_ TRCM_a098_VEH_temperature m98 : 20|1@1+ (1,0) [0|1] "" Vector__XXX
 SG_ TRCM_a098_VEH_torque m98 : 21|1@1+ (1,0) [0|1] "" Vector__XXX
 SG_ TRCM_a098_PARTY_status m98 : 22|1@1+ (1,0) [0|1] "" Vector__XXX
 SG_ TRCM_a098_PARTY_temperature m98 : 23|1@1+ (1,0) [0|1] "" Vector__XXX
 SG_ TRCM_a098_PARTY_thermalControl m98 : 24|1@1+ (1,0) [0|1] "" Vector__XXX
 SG_ TRCM_a098_PARTY_torque m98 : 25|1@1+ (1,0) [0|1] "" Vector__XXX
 SG_ TRCM_a098_PT_thermalControl m98 : 26|1@1+ (1,0) [0|1] "" Vector__XXX
 SG_ TRCM_a098_PT_temperature m98 : 27|1@1+ (1,0) [0|1] "" Vector__XXX
 SG_ TRCM_a098_PARTY_motorStatus m98 : 28|1@1+ (1,0) [0|1] "" Vector__XXX
 SG_ TRCM_a098_VEH_motorStatus m98 : 29|1@1+ (1,0) [0|1] "" Vector__XXX
 SG_ TRCM_a099_VEH_oocStatus m99 : 16|1@1+ (1,0) [0|1] "" Vector__XXX
 SG_ TRCM_a100_VEH m100 : 16|1@1+ (1,0) [0|1] "" Vector__XXX
 SG_ TRCM_a100_PARTY m100 : 17|1@1+ (1,0) [0|1] "" Vector__XXX
 SG_ TRCM_a100_PT m100 : 18|1@1+ (1,0) [0|1] "" Vector__XXX
 SG_ TRCM_a100_CH m100 : 19|1@1+ (1,0) [0|1] "" Vector__XXX
 SG_ TRCM_a100_OBD m100 : 20|1@1+ (1,0) [0|1] "" Vector__XXX
 SG_ TRCM_a101_VEH_state m101 : 16|1@1+ (1,0) [0|1] "" Vector__XXX
 SG_ TRCM_a101_PARTY_locState m101 : 17|1@1+ (1,0) [0|1] "" Vector__XXX
 SG_ TRCM_a101_LIPC_externalWatchdogH m101 : 18|1@1+ (1,0) [0|1] "" Vector__XXX
 SG_ TRCM_a101_VEH_locState m101 : 19|1@1+ (1,0) [0|1] "" Vector__XXX
 SG_ TRCM_a101_BDY_locState m101 : 20|1@1+ (1,0) [0|1] "" Vector__XXX
 SG_ TRCM_a102_VEH_faultsAndExtras m102 : 16|1@1+ (1,0) [0|1] "" Vector__XXX
 SG_ TRCM_a102_VEH_feedbackStatus m102 : 17|1@1+ (1,0) [0|1] "" Vector__XXX
 SG_ TRCM_a102_VEH_sensorStatus m102 : 18|1@1+ (1,0) [0|1] "" Vector__XXX
 SG_ TRCM_a102_VEH_rods m102 : 19|1@1+ (1,0) [0|1] "" Vector__XXX
 SG_ TRCM_a103_VEH_hvsNm m103 : 16|1@1+ (1,0) [0|1] "" Vector__XXX
 SG_ TRCM_a103_VEH_vehNm m103 : 17|1@1+ (1,0) [0|1] "" Vector__XXX
 SG_ TRCM_a103_VEH_status m103 : 18|1@1+ (1,0) [0|1] "" Vector__XXX
 SG_ TRCM_a103_PT_ptNm m103 : 19|1@1+ (1,0) [0|1] "" Vector__XXX
 SG_ TRCM_a103_PT_status m103 : 20|1@1+ (1,0) [0|1] "" Vector__XXX
 SG_ TRCM_a103_VEH_evseStatus m103 : 21|1@1+ (1,0) [0|1] "" Vector__XXX
 SG_ TRCM_a105_VEH_states m105 : 16|1@1+ (1,0) [0|1] "" Vector__XXX
 SG_ TRCM_a105_VEH_chNm m105 : 17|1@1+ (1,0) [0|1] "" Vector__XXX
 SG_ TRCM_a105_VEH_dampingStates m105 : 18|1@1+ (1,0) [0|1] "" Vector__XXX
 SG_ TRCM_a106_VEH_dcdcStatus m106 : 16|1@1+ (1,0) [0|1] "" Vector__XXX
 SG_ TRCM_a106_VEH_thermalControl m106 : 17|1@1+ (1,0) [0|1] "" Vector__XXX
 SG_ TRCM_a106_VEH_dcdcRailStatus m106 : 18|1@1+ (1,0) [0|1] "" Vector__XXX
 SG_ TRCM_a106_CH_dcdcRailStatus m106 : 19|1@1+ (1,0) [0|1] "" Vector__XXX
 SG_ TRCM_a106_CH_alertMatrix m106 : 20|1@1+ (1,0) [0|1] "" Vector__XXX
 SG_ TRCM_a107_VEH_hvsNm m107 : 16|1@1+ (1,0) [0|1] "" Vector__XXX
 SG_ TRCM_a107_VEH_vehNm m107 : 17|1@1+ (1,0) [0|1] "" Vector__XXX
 SG_ TRCM_a107_VEH_status m107 : 18|1@1+ (1,0) [0|1] "" Vector__XXX
 SG_ TRCM_a107_VEH_thermalStatus m107 : 19|1@1+ (1,0) [0|1] "" Vector__XXX
 SG_ TRCM_a107_VEH_bmbMinMax m107 : 20|1@1+ (1,0) [0|1] "" Vector__XXX
 SG_ TRCM_a107_VEH_powerAvailable m107 : 21|1@1+ (1,0) [0|1] "" Vector__XXX
 SG_ TRCM_a107_PT_ptNm m107 : 22|1@1+ (1,0) [0|1] "" Vector__XXX
 SG_ TRCM_a107_PT_status m107 : 23|1@1+ (1,0) [0|1] "" Vector__XXX
 SG_ TRCM_a107_PT_thermalStatus m107 : 24|1@1+ (1,0) [0|1] "" Vector__XXX
 SG_ TRCM_a107_PT_socStatus m107 : 25|1@1+ (1,0) [0|1] "" Vector__XXX
 SG_ TRCM_a107_VEH_socStatus m107 : 26|1@1+ (1,0) [0|1] "" Vector__XXX
 SG_ TRCM_a107_VEH_packConfig m107 : 27|1@1+ (1,0) [0|1] "" Vector__XXX
 SG_ TRCM_a107_VEH_energyStatus m107 : 28|1@1+ (1,0) [0|1] "" Vector__XXX
 SG_ TRCM_a107_VEH_chargeInfo m107 : 29|1@1+ (1,0) [0|1] "" Vector__XXX
 SG_ TRCM_a108_VEH_hvStatus m108 : 16|1@1+ (1,0) [0|1] "" Vector__XXX
 SG_ TRCM_a108_VEH_temperature m108 : 17|1@1+ (1,0) [0|1] "" Vector__XXX
 SG_ TRCM_a108_VEH_thermalControl m108 : 18|1@1+ (1,0) [0|1] "" Vector__XXX
 SG_ TRCM_a108_VEH_torque m108 : 19|1@1+ (1,0) [0|1] "" Vector__XXX
 SG_ TRCM_a108_VEH_status m108 : 20|1@1+ (1,0) [0|1] "" Vector__XXX
 SG_ TRCM_a108_PARTY_torque m108 : 21|1@1+ (1,0) [0|1] "" Vector__XXX
 SG_ TRCM_a108_PARTY_status m108 : 22|1@1+ (1,0) [0|1] "" Vector__XXX
 SG_ TRCM_a108_PARTY_temperature m108 : 23|1@1+ (1,0) [0|1] "" Vector__XXX
 SG_ TRCM_a108_PARTY_thermalControl m108 : 24|1@1+ (1,0) [0|1] "" Vector__XXX
 SG_ TRCM_a108_PT_temperature m108 : 25|1@1+ (1,0) [0|1] "" Vector__XXX
 SG_ TRCM_a108_PT_thermalControl m108 : 26|1@1+ (1,0) [0|1] "" Vector__XXX
 SG_ TRCM_a108_PARTY_motorStatus m108 : 27|1@1+ (1,0) [0|1] "" Vector__XXX
 SG_ TRCM_a108_VEH_motorStatus m108 : 28|1@1+ (1,0) [0|1] "" Vector__XXX
 SG_ TRCM_a108_CH_torque m108 : 29|1@1+ (1,0) [0|1] "" Vector__XXX
 SG_ TRCM_a110_VEH_carState m110 : 16|1@1+ (1,0) [0|1] "" Vector__XXX
 SG_ TRCM_a110_VEH_carConfig m110 : 17|1@1+ (1,0) [0|1] "" Vector__XXX
 SG_ TRCM_a110_VEH_time m110 : 18|1@1+ (1,0) [0|1] "" Vector__XXX
 SG_ TRCM_a110_VEH_updateStatus m110 : 19|1@1+ (1,0) [0|1] "" Vector__XXX
 SG_ TRCM_a110_VEH_vehNm m110 : 20|1@1+ (1,0) [0|1] "" Vector__XXX
 SG_ TRCM_a110_VEH_mismatchFault m110 : 21|1@1+ (1,0) [0|1] "" Vector__XXX
 SG_ TRCM_a110_VEH_vin m110 : 22|1@1+ (1,0) [0|1] "" Vector__XXX
 SG_ TRCM_a110_VEH_bmpDebug m110 : 23|1@1+ (1,0) [0|1] "" Vector__XXX
 SG_ TRCM_a110_VEH_gearControl m110 : 24|1@1+ (1,0) [0|1] "" Vector__XXX
 SG_ TRCM_a110_VEH_canLogAvailability m110 : 25|1@1+ (1,0) [0|1] "" Vector__XXX
 SG_ TRCM_a110_CH_airbagCutoffStatus m110 : 26|1@1+ (1,0) [0|1] "" Vector__XXX
 SG_ TRCM_a110_CH_carConfig m110 : 27|1@1+ (1,0) [0|1] "" Vector__XXX
 SG_ TRCM_a110_CH_carState m110 : 28|1@1+ (1,0) [0|1] "" Vector__XXX
 SG_ TRCM_a110_CH_vin m110 : 29|1@1+ (1,0) [0|1] "" Vector__XXX
 SG_ TRCM_a110_CH_chNm m110 : 30|1@1+ (1,0) [0|1] "" Vector__XXX
 SG_ TRCM_a110_CH_epochTimeGtw m110 : 31|1@1+ (1,0) [0|1] "" Vector__XXX
 SG_ TRCM_a110_PARTY_carConfig m110 : 32|1@1+ (1,0) [0|1] "" Vector__XXX
 SG_ TRCM_a111_VEH_internalStatus m111 : 16|1@1+ (1,0) [0|1] "" Vector__XXX
 SG_ TRCM_a111_VEH_status m111 : 17|1@1+ (1,0) [0|1] "" Vector__XXX
 SG_ TRCM_a111_VEH_vehNm m111 : 18|1@1+ (1,0) [0|1] "" Vector__XXX
 SG_ TRCM_a111_RIPC_LVPowerState m111 : 19|1@1+ (1,0) [0|1] "" Vector__XXX
 SG_ TRCM_a111_RIPC_epbPrivateState m111 : 20|1@1+ (1,0) [0|1] "" Vector__XXX
 SG_ TRCM_a111_RIPC_railStatus m111 : 21|1@1+ (1,0) [0|1] "" Vector__XXX
 SG_ TRCM_a111_RIPC_remoteADC m111 : 22|1@1+ (1,0) [0|1] "" Vector__XXX
 SG_ TRCM_a111_RIPC_switchStatus m111 : 23|1@1+ (1,0) [0|1] "" Vector__XXX
 SG_ TRCM_a111_VEH_LVPowerState m111 : 24|1@1+ (1,0) [0|1] "" Vector__XXX
 SG_ TRCM_a111_VEH_seatStatus m111 : 25|1@1+ (1,0) [0|1] "" Vector__XXX
 SG_ TRCM_a111_PARTY_status m111 : 26|1@1+ (1,0) [0|1] "" Vector__XXX
 SG_ TRCM_a111_CH_status m111 : 27|1@1+ (1,0) [0|1] "" Vector__XXX
 SG_ TRCM_a112_VEH_internalStatus m112 : 16|1@1+ (1,0) [0|1] "" Vector__XXX
 SG_ TRCM_a112_VEH_status m112 : 17|1@1+ (1,0) [0|1] "" Vector__XXX
 SG_ TRCM_a112_VEH_vehNm m112 : 18|1@1+ (1,0) [0|1] "" Vector__XXX
 SG_ TRCM_a112_LIPC_LVPowerState m112 : 19|1@1+ (1,0) [0|1] "" Vector__XXX
 SG_ TRCM_a112_LIPC_epbPrivateState m112 : 20|1@1+ (1,0) [0|1] "" Vector__XXX
 SG_ TRCM_a112_LIPC_railStatus m112 : 21|1@1+ (1,0) [0|1] "" Vector__XXX
 SG_ TRCM_a112_LIPC_remoteADC m112 : 22|1@1+ (1,0) [0|1] "" Vector__XXX
 SG_ TRCM_a112_LIPC_switchStatus m112 : 23|1@1+ (1,0) [0|1] "" Vector__XXX
 SG_ TRCM_a112_VEH_LVPowerState m112 : 24|1@1+ (1,0) [0|1] "" Vector__XXX
 SG_ TRCM_a112_PARTY_status m112 : 25|1@1+ (1,0) [0|1] "" Vector__XXX
 SG_ TRCM_a112_CH_status m112 : 26|1@1+ (1,0) [0|1] "" Vector__XXX
 SG_ TRCM_a114_PARTY_status m114 : 16|1@1+ (1,0) [0|1] "" Vector__XXX
 SG_ TRCM_a114_PARTY_wheelSpeeds m114 : 17|1@1+ (1,0) [0|1] "" Vector__XXX
 SG_ TRCM_a114_VEH_wheelSpeeds m114 : 18|1@1+ (1,0) [0|1] "" Vector__XXX
 SG_ TRCM_a114_CH_wheelSpeeds m114 : 19|1@1+ (1,0) [0|1] "" Vector__XXX
 SG_ TRCM_a114_PARTY_party3 m114 : 20|1@1+ (1,0) [0|1] "" Vector__XXX
 SG_ TRCM_a114_VEH_party3 m114 : 21|1@1+ (1,0) [0|1] "" Vector__XXX
 SG_ TRCM_a114_VEH_status m114 : 22|1@1+ (1,0) [0|1] "" Vector__XXX
 SG_ TRCM_a114_PARTY_wheelRotation m114 : 23|1@1+ (1,0) [0|1] "" Vector__XXX
 SG_ TRCM_a114_CH_wheelRotation m114 : 24|1@1+ (1,0) [0|1] "" Vector__XXX
 SG_ TRCM_a114_VEH_wheelRotation m114 : 25|1@1+ (1,0) [0|1] "" Vector__XXX
 SG_ TRCM_a114_PARTY_brakeTorque m114 : 26|1@1+ (1,0) [0|1] "" Vector__XXX
 SG_ TRCM_a114_PARTY_offsets m114 : 27|1@1+ (1,0) [0|1] "" Vector__XXX
 SG_ TRCM_a114_BDY_offsets m114 : 28|1@1+ (1,0) [0|1] "" Vector__XXX
 SG_ TRCM_a114_BDY_party3 m114 : 29|1@1+ (1,0) [0|1] "" Vector__XXX
 SG_ TRCM_a114_BDY_status m114 : 30|1@1+ (1,0) [0|1] "" Vector__XXX
 SG_ TRCM_a114_BDY_wheelRotation m114 : 31|1@1+ (1,0) [0|1] "" Vector__XXX
 SG_ TRCM_a114_BDY_wheelSpeeds m114 : 32|1@1+ (1,0) [0|1] "" Vector__XXX
 SG_ TRCM_a114_CH_party1 m114 : 33|1@1+ (1,0) [0|1] "" Vector__XXX
 SG_ TRCM_a114_CH_party3 m114 : 34|1@1+ (1,0) [0|1] "" Vector__XXX
 SG_ TRCM_a114_CH_status m114 : 35|1@1+ (1,0) [0|1] "" Vector__XXX
 SG_ TRCM_a115_VEH_vehNm m115 : 16|1@1+ (1,0) [0|1] "" Vector__XXX
 SG_ TRCM_a115_VEH_authentication m115 : 17|1@1+ (1,0) [0|1] "" Vector__XXX
 SG_ TRCM_a115_VEH_BLEResetRequest m115 : 18|1@1+ (1,0) [0|1] "" Vector__XXX
 SG_ TRCM_a115_VEH_requests m115 : 19|1@1+ (1,0) [0|1] "" Vector__XXX
 SG_ TRCM_a115_VEH_requests2 m115 : 20|1@1+ (1,0) [0|1] "" Vector__XXX
 SG_ TRCM_a115_REM_authentication m115 : 21|1@1+ (1,0) [0|1] "" Vector__XXX
 SG_ TRCM_a115_UI_corianderVehicleCon m115 : 22|1@1+ (1,0) [0|1] "" Vector__XXX
 SG_ TRCM_a115_CH_TPMSDisplay m115 : 23|1@1+ (1,0) [0|1] "" Vector__XXX
 SG_ TRCM_a116_PARTY_epbmStatus m116 : 16|1@1+ (1,0) [0|1] "" Vector__XXX
 SG_ TRCM_a116_VEH_vehNm m116 : 17|1@1+ (1,0) [0|1] "" Vector__XXX
 SG_ TRCM_a116_VEH_hvacRequest m116 : 18|1@1+ (1,0) [0|1] "" Vector__XXX
 SG_ TRCM_a116_VEH_hvacStatus m116 : 19|1@1+ (1,0) [0|1] "" Vector__XXX
 SG_ TRCM_a116_VEH_LVPowerState m116 : 20|1@1+ (1,0) [0|1] "" Vector__XXX
 SG_ TRCM_a116_VEH_lightStatus m116 : 21|1@1+ (1,0) [0|1] "" Vector__XXX
 SG_ TRCM_a116_VEH_seatStatus m116 : 22|1@1+ (1,0) [0|1] "" Vector__XXX
 SG_ TRCM_a116_VEH_thsStatus m116 : 23|1@1+ (1,0) [0|1] "" Vector__XXX
 SG_ TRCM_a116_VEH_doorStatus m116 : 24|1@1+ (1,0) [0|1] "" Vector__XXX
 SG_ TRCM_a116_VEH_seatHeatStatus m116 : 25|1@1+ (1,0) [0|1] "" Vector__XXX
 SG_ TRCM_a116_VEH_restraintStatus m116 : 26|1@1+ (1,0) [0|1] "" Vector__XXX
 SG_ TRCM_a116_VEH_switchStatus m116 : 27|1@1+ (1,0) [0|1] "" Vector__XXX
 SG_ TRCM_a116_VEH_logging1Hz m116 : 28|1@1+ (1,0) [0|1] "" Vector__XXX
 SG_ TRCM_a116_VEH_seatStatus2 m116 : 29|1@1+ (1,0) [0|1] "" Vector__XXX
 SG_ TRCM_a116_VEH_status m116 : 30|1@1+ (1,0) [0|1] "" Vector__XXX
 SG_ TRCM_a116_VEH_thermalCommand m116 : 31|1@1+ (1,0) [0|1] "" Vector__XXX
 SG_ TRCM_a116_VEH_windowStatus m116 : 32|1@1+ (1,0) [0|1] "" Vector__XXX
 SG_ TRCM_a116_PARTY_restraintStatus m116 : 33|1@1+ (1,0) [0|1] "" Vector__XXX
 SG_ TRCM_a116_PARTY_doorStatus m116 : 34|1@1+ (1,0) [0|1] "" Vector__XXX
 SG_ TRCM_a116_BDY_epbmStatus m116 : 35|1@1+ (1,0) [0|1] "" Vector__XXX
 SG_ TRCM_a116_BDY_restraintStatus m116 : 36|1@1+ (1,0) [0|1] "" Vector__XXX
 SG_ TRCM_a116_BDY_switchStatus m116 : 37|1@1+ (1,0) [0|1] "" Vector__XXX
 SG_ TRCM_a117_BDY_epbmStatus m117 : 16|1@1+ (1,0) [0|1] "" Vector__XXX
 SG_ TRCM_a117_BDY_restraintStatus m117 : 17|1@1+ (1,0) [0|1] "" Vector__XXX
 SG_ TRCM_a117_VEH_prndStatus m117 : 18|1@1+ (1,0) [0|1] "" Vector__XXX
 SG_ TRCM_a117_PARTY_epbmStatus m117 : 19|1@1+ (1,0) [0|1] "" Vector__XXX
 SG_ TRCM_a117_VEH_vehNm m117 : 20|1@1+ (1,0) [0|1] "" Vector__XXX
 SG_ TRCM_a117_VEH_hvacBlowerFdb m117 : 21|1@1+ (1,0) [0|1] "" Vector__XXX
 SG_ TRCM_a117_VEH_LVPowerState m117 : 22|1@1+ (1,0) [0|1] "" Vector__XXX
 SG_ TRCM_a117_VEH_restraintStatus m117 : 23|1@1+ (1,0) [0|1] "" Vector__XXX
 SG_ TRCM_a117_VEH_lightStatus m117 : 24|1@1+ (1,0) [0|1] "" Vector__XXX
 SG_ TRCM_a117_VEH_seatStatus m117 : 25|1@1+ (1,0) [0|1] "" Vector__XXX
 SG_ TRCM_a117_BDY_falconSwitchStatus m117 : 26|1@1+ (1,0) [0|1] "" Vector__XXX
 SG_ TRCM_a117_VEH_doorStatus m117 : 27|1@1+ (1,0) [0|1] "" Vector__XXX
 SG_ TRCM_a117_VEH_doorStatus2 m117 : 28|1@1+ (1,0) [0|1] "" Vector__XXX
 SG_ TRCM_a117_VEH_windowStatus m117 : 29|1@1+ (1,0) [0|1] "" Vector__XXX
 SG_ TRCM_a117_VEH_switchStatus m117 : 30|1@1+ (1,0) [0|1] "" Vector__XXX
 SG_ TRCM_a117_VEH_intrusionSensorSta m117 : 31|1@1+ (1,0) [0|1] "" Vector__XXX
 SG_ TRCM_a117_VEH_liftgateStatus m117 : 32|1@1+ (1,0) [0|1] "" Vector__XXX
 SG_ TRCM_a117_VEH_seatStatus2 m117 : 33|1@1+ (1,0) [0|1] "" Vector__XXX
 SG_ TRCM_a117_PARTY_restraintStatus m117 : 34|1@1+ (1,0) [0|1] "" Vector__XXX
 SG_ TRCM_a117_VEH_thermalStatus m117 : 35|1@1+ (1,0) [0|1] "" Vector__XXX
 SG_ TRCM_a117_PARTY_doorStatus m117 : 36|1@1+ (1,0) [0|1] "" Vector__XXX
 SG_ TRCM_a117_VEH_status m117 : 37|1@1+ (1,0) [0|1] "" Vector__XXX
 SG_ TRCM_a117_PARTY_prndStatus m117 : 38|1@1+ (1,0) [0|1] "" Vector__XXX
 SG_ TRCM_a117_PARTY_lightingSecondar m117 : 39|1@1+ (1,0) [0|1] "" Vector__XXX
 SG_ TRCM_a118_VEH_vehNm m118 : 16|1@1+ (1,0) [0|1] "" Vector__XXX
 SG_ TRCM_a118_VEH_lighting m118 : 17|1@1+ (1,0) [0|1] "" Vector__XXX
 SG_ TRCM_a118_VEH_sensors m118 : 18|1@1+ (1,0) [0|1] "" Vector__XXX
 SG_ TRCM_a118_VEH_status m118 : 19|1@1+ (1,0) [0|1] "" Vector__XXX
 SG_ TRCM_a118_VEH_okToUseHighPwr m118 : 20|1@1+ (1,0) [0|1] "" Vector__XXX
 SG_ TRCM_a118_VEH_LVPowerState m118 : 21|1@1+ (1,0) [0|1] "" Vector__XXX
 SG_ TRCM_a118_VEH_coolant m118 : 22|1@1+ (1,0) [0|1] "" Vector__XXX
 SG_ TRCM_a118_VEH_vehicleStatus m118 : 23|1@1+ (1,0) [0|1] "" Vector__XXX
 SG_ TRCM_a118_VEH_12VBatteryStatus m118 : 24|1@1+ (1,0) [0|1] "" Vector__XXX
 SG_ TRCM_a118_VEH_systemStatus m118 : 25|1@1+ (1,0) [0|1] "" Vector__XXX
 SG_ TRCM_a118_PARTY_LVPowerState m118 : 26|1@1+ (1,0) [0|1] "" Vector__XXX
 SG_ TRCM_a118_PARTY_outputPowerStatu m118 : 27|1@1+ (1,0) [0|1] "" Vector__XXX
 SG_ TRCM_a118_PARTY_vehicleTime m118 : 28|1@1+ (1,0) [0|1] "" Vector__XXX
 SG_ TRCM_a118_VEH_thermalCommand m118 : 29|1@1+ (1,0) [0|1] "" Vector__XXX
 SG_ TRCM_a118_CH_LVPowerState m118 : 30|1@1+ (1,0) [0|1] "" Vector__XXX
 SG_ TRCM_a118_PARTY_sensors m118 : 31|1@1+ (1,0) [0|1] "" Vector__XXX
 SG_ TRCM_a118_CH_sensors m118 : 32|1@1+ (1,0) [0|1] "" Vector__XXX
 SG_ TRCM_a118_VEH_interNodeResistanc m118 : 33|1@1+ (1,0) [0|1] "" Vector__XXX
 SG_ TRCM_a118_CH_lighting m118 : 34|1@1+ (1,0) [0|1] "" Vector__XXX
 SG_ TRCM_a118_VEH_lightStatus m118 : 35|1@1+ (1,0) [0|1] "" Vector__XXX
 SG_ TRCM_a118_PARTY_vehNm m118 : 36|1@1+ (1,0) [0|1] "" Vector__XXX
 SG_ TRCM_a118_CH_12VBatteryStatus m118 : 37|1@1+ (1,0) [0|1] "" Vector__XXX
 SG_ TRCM_a118_CH_LVBMS_statusHigh m118 : 38|1@1+ (1,0) [0|1] "" Vector__XXX
 SG_ TRCM_a118_CH_alertMatrix m118 : 39|1@1+ (1,0) [0|1] "" Vector__XXX
 SG_ TRCM_a118_BDY_outputPowerStatus m118 : 40|1@1+ (1,0) [0|1] "" Vector__XXX
 SG_ TRCM_a118_BDY_vehicleTime m118 : 41|1@1+ (1,0) [0|1] "" Vector__XXX
 SG_ TRCM_a118_PARTY_AP_vehicleState1 m118 : 42|1@1+ (1,0) [0|1] "" Vector__XXX
 SG_ TRCM_a118_BDY_AP_vehicleState1Hz m118 : 43|1@1+ (1,0) [0|1] "" Vector__XXX
 SG_ TRCM_a118_PARTY_VCFRONT_cameraCl m118 : 44|1@1+ (1,0) [0|1] "" Vector__XXX
 SG_ TRCM_a119_VEH_steerAngle m119 : 16|1@1+ (1,0) [0|1] "" Vector__XXX
 SG_ TRCM_a119_VEH_leftStalk m119 : 17|1@1+ (1,0) [0|1] "" Vector__XXX
 SG_ TRCM_a119_VEH_rightStalk m119 : 18|1@1+ (1,0) [0|1] "" Vector__XXX
 SG_ TRCM_a119_PARTY_rightStalk m119 : 19|1@1+ (1,0) [0|1] "" Vector__XXX
 SG_ TRCM_a119_CH_steerAngle m119 : 20|1@1+ (1,0) [0|1] "" Vector__XXX
 SG_ TRCM_a119_PARTY_steerAngle m119 : 21|1@1+ (1,0) [0|1] "" Vector__XXX
 SG_ TRCM_a120_PARTY_chassisCntl m120 : 16|1@1+ (1,0) [0|1] "" Vector__XXX
 SG_ TRCM_a120_VEH_systemStatus m120 : 17|1@1+ (1,0) [0|1] "" Vector__XXX
 SG_ TRCM_a120_CH_chassisCntl m120 : 18|1@1+ (1,0) [0|1] "" Vector__XXX
 SG_ TRCM_a120_PARTY_systemStatus m120 : 19|1@1+ (1,0) [0|1] "" Vector__XXX
 SG_ TRCM_a120_PARTY_torque m120 : 20|1@1+ (1,0) [0|1] "" Vector__XXX
 SG_ TRCM_a120_VEH_torque m120 : 21|1@1+ (1,0) [0|1] "" Vector__XXX
 SG_ TRCM_a120_PARTY_locStatus m120 : 22|1@1+ (1,0) [0|1] "" Vector__XXX
 SG_ TRCM_a120_PARTY_speed m120 : 23|1@1+ (1,0) [0|1] "" Vector__XXX
 SG_ TRCM_a120_VEH_speed m120 : 24|1@1+ (1,0) [0|1] "" Vector__XXX
 SG_ TRCM_a120_PARTY_status m120 : 25|1@1+ (1,0) [0|1] "" Vector__XXX
 SG_ TRCM_a120_PT_speed m120 : 26|1@1+ (1,0) [0|1] "" Vector__XXX
 SG_ TRCM_a120_PT_systemStatus m120 : 27|1@1+ (1,0) [0|1] "" Vector__XXX
 SG_ TRCM_a120_PARTY_vehicleEstimates m120 : 28|1@1+ (1,0) [0|1] "" Vector__XXX
 SG_ TRCM_a120_VEH_aggregatedAxleSpee m120 : 29|1@1+ (1,0) [0|1] "" Vector__XXX
 SG_ TRCM_a120_PARTY_aggregatedAxleSp m120 : 30|1@1+ (1,0) [0|1] "" Vector__XXX
 SG_ TRCM_a120_VEH_systemPower m120 : 31|1@1+ (1,0) [0|1] "" Vector__XXX
 SG_ TRCM_a120_PARTY_autonomyHealth m120 : 32|1@1+ (1,0) [0|1] "" Vector__XXX
 SG_ TRCM_a120_VEH_autonomyHealth m120 : 33|1@1+ (1,0) [0|1] "" Vector__XXX
 SG_ TRCM_a120_PT_systemPower m120 : 34|1@1+ (1,0) [0|1] "" Vector__XXX
 SG_ TRCM_a120_PARTY_stalklessInterfa m120 : 35|1@1+ (1,0) [0|1] "" Vector__XXX
 SG_ TRCM_a120_CH_speed m120 : 36|1@1+ (1,0) [0|1] "" Vector__XXX
 SG_ TRCM_a120_VEH_estimatedBrakeTemp m120 : 37|1@1+ (1,0) [0|1] "" Vector__XXX
 SG_ TRCM_a120_PARTY_prndControl m120 : 38|1@1+ (1,0) [0|1] "" Vector__XXX
 SG_ TRCM_a120_PARTY_locStatus2 m120 : 39|1@1+ (1,0) [0|1] "" Vector__XXX
 SG_ TRCM_a120_VEH_chassisCntl m120 : 40|1@1+ (1,0) [0|1] "" Vector__XXX
 SG_ TRCM_a120_CH_locStatus2 m120 : 41|1@1+ (1,0) [0|1] "" Vector__XXX
 SG_ TRCM_a120_VEH_locStatus m120 : 42|1@1+ (1,0) [0|1] "" Vector__XXX
 SG_ TRCM_a120_VEH_locStatus2 m120 : 43|1@1+ (1,0) [0|1] "" Vector__XXX
 SG_ TRCM_a120_VEH_prndControl m120 : 44|1@1+ (1,0) [0|1] "" Vector__XXX
 SG_ TRCM_a120_VEH_vehicleEstimates m120 : 45|1@1+ (1,0) [0|1] "" Vector__XXX
 SG_ TRCM_a120_PARTY_motorStatus m120 : 46|1@1+ (1,0) [0|1] "" Vector__XXX
 SG_ TRCM_a120_VEH_motorStatus m120 : 47|1@1+ (1,0) [0|1] "" Vector__XXX
 SG_ TRCM_a120_BDY_speed m120 : 48|1@1+ (1,0) [0|1] "" Vector__XXX
 SG_ TRCM_a332_groundLossError m332 : 16|1@1+ (1,0) [0|1] "" Vector__XXX
 SG_ TRCM_a332_overcurrentError m332 : 17|1@1+ (1,0) [0|1] "" Vector__XXX
 SG_ TRCM_a332_overvoltageError m332 : 18|1@1+ (1,0) [0|1] "" Vector__XXX
 SG_ TRCM_a332_currentMonitorTimer m332 : 24|8@1+ (16,0) [0|4080] "" Vector__XXX
 SG_ TRCM_a333_groundLossError m333 : 16|1@1+ (1,0) [0|1] "" Vector__XXX
 SG_ TRCM_a333_overcurrentError m333 : 17|1@1+ (1,0) [0|1] "" Vector__XXX
 SG_ TRCM_a333_overvoltageError m333 : 18|1@1+ (1,0) [0|1] "" Vector__XXX
 SG_ TRCM_a333_currentMonitorTimer m333 : 24|8@1+ (16,0) [0|4080] "" Vector__XXX
 SG_ TRCM_a334_groundLossError m334 : 16|1@1+ (1,0) [0|1] "" Vector__XXX
 SG_ TRCM_a334_overcurrentError m334 : 17|1@1+ (1,0) [0|1] "" Vector__XXX
 SG_ TRCM_a334_overvoltageError m334 : 18|1@1+ (1,0) [0|1] "" Vector__XXX
 SG_ TRCM_a334_currentMonitorTimer m334 : 24|8@1+ (16,0) [0|4080] "" Vector__XXX
 SG_ TRCM_a335_groundLossError m335 : 16|1@1+ (1,0) [0|1] "" Vector__XXX
 SG_ TRCM_a335_overcurrentError m335 : 17|1@1+ (1,0) [0|1] "" Vector__XXX
 SG_ TRCM_a335_overvoltageError m335 : 18|1@1+ (1,0) [0|1] "" Vector__XXX
 SG_ TRCM_a335_currentMonitorTimer m335 : 24|8@1+ (16,0) [0|4080] "" Vector__XXX
 SG_ TRCM_a336_groundLossError m336 : 16|1@1+ (1,0) [0|1] "" Vector__XXX
 SG_ TRCM_a336_overcurrentError m336 : 17|1@1+ (1,0) [0|1] "" Vector__XXX
 SG_ TRCM_a336_overvoltageError m336 : 18|1@1+ (1,0) [0|1] "" Vector__XXX
 SG_ TRCM_a336_currentMonitorTimer m336 : 24|8@1+ (16,0) [0|4080] "" Vector__XXX
 SG_ TRCM_a337_groundLossError m337 : 16|1@1+ (1,0) [0|1] "" Vector__XXX
 SG_ TRCM_a337_overcurrentError m337 : 17|1@1+ (1,0) [0|1] "" Vector__XXX
 SG_ TRCM_a337_overvoltageError m337 : 18|1@1+ (1,0) [0|1] "" Vector__XXX
 SG_ TRCM_a337_currentMonitorTimer m337 : 24|8@1+ (16,0) [0|4080] "" Vector__XXX
 SG_ TRCM_a338_groundLossError m338 : 16|1@1+ (1,0) [0|1] "" Vector__XXX
 SG_ TRCM_a338_overcurrentError m338 : 17|1@1+ (1,0) [0|1] "" Vector__XXX
 SG_ TRCM_a338_overvoltageError m338 : 18|1@1+ (1,0) [0|1] "" Vector__XXX
 SG_ TRCM_a338_currentMonitorTimer m338 : 24|8@1+ (16,0) [0|4080] "" Vector__XXX
 SG_ TRCM_a340_groundLossError m340 : 16|1@1+ (1,0) [0|1] "" Vector__XXX
 SG_ TRCM_a340_overcurrentError m340 : 17|1@1+ (1,0) [0|1] "" Vector__XXX
 SG_ TRCM_a340_overvoltageError m340 : 18|1@1+ (1,0) [0|1] "" Vector__XXX
 SG_ TRCM_a340_currentMonitorTimer m340 : 24|8@1+ (16,0) [0|4080] "" Vector__XXX
 SG_ TRCM_a341_groundLossError m341 : 16|1@1+ (1,0) [0|1] "" Vector__XXX
 SG_ TRCM_a341_overcurrentError m341 : 17|1@1+ (1,0) [0|1] "" Vector__XXX
 SG_ TRCM_a341_overvoltageError m341 : 18|1@1+ (1,0) [0|1] "" Vector__XXX
 SG_ TRCM_a341_currentMonitorTimer m341 : 24|8@1+ (16,0) [0|4080] "" Vector__XXX
 SG_ TRCM_a342_groundLossError m342 : 16|1@1+ (1,0) [0|1] "" Vector__XXX
 SG_ TRCM_a342_overcurrentError m342 : 17|1@1+ (1,0) [0|1] "" Vector__XXX
 SG_ TRCM_a342_overvoltageError m342 : 18|1@1+ (1,0) [0|1] "" Vector__XXX
 SG_ TRCM_a342_currentMonitorTimer m342 : 24|8@1+ (16,0) [0|4080] "" Vector__XXX
 SG_ TRCM_a343_groundLossError m343 : 16|1@1+ (1,0) [0|1] "" Vector__XXX
 SG_ TRCM_a343_overcurrentError m343 : 17|1@1+ (1,0) [0|1] "" Vector__XXX
 SG_ TRCM_a343_overvoltageError m343 : 18|1@1+ (1,0) [0|1] "" Vector__XXX
 SG_ TRCM_a343_currentMonitorTimer m343 : 24|8@1+ (16,0) [0|4080] "" Vector__XXX
 SG_ TRCM_a344_groundLossError m344 : 16|1@1+ (1,0) [0|1] "" Vector__XXX
 SG_ TRCM_a344_overcurrentError m344 : 17|1@1+ (1,0) [0|1] "" Vector__XXX
 SG_ TRCM_a344_overvoltageError m344 : 18|1@1+ (1,0) [0|1] "" Vector__XXX
 SG_ TRCM_a344_currentMonitorTimer m344 : 24|8@1+ (16,0) [0|4080] "" Vector__XXX
 SG_ TRCM_a345_groundLossError m345 : 16|1@1+ (1,0) [0|1] "" Vector__XXX
 SG_ TRCM_a345_overcurrentError m345 : 17|1@1+ (1,0) [0|1] "" Vector__XXX
 SG_ TRCM_a345_overvoltageError m345 : 18|1@1+ (1,0) [0|1] "" Vector__XXX
 SG_ TRCM_a345_currentMonitorTimer m345 : 24|8@1+ (16,0) [0|4080] "" Vector__XXX
 SG_ TRCM_a346_groundLossError m346 : 16|1@1+ (1,0) [0|1] "" Vector__XXX
 SG_ TRCM_a346_overcurrentError m346 : 17|1@1+ (1,0) [0|1] "" Vector__XXX
 SG_ TRCM_a346_overvoltageError m346 : 18|1@1+ (1,0) [0|1] "" Vector__XXX
 SG_ TRCM_a346_currentMonitorTimer m346 : 24|8@1+ (16,0) [0|4080] "" Vector__XXX
 SG_ TRCM_a347_groundLossError m347 : 16|1@1+ (1,0) [0|1] "" Vector__XXX
 SG_ TRCM_a347_overcurrentError m347 : 17|1@1+ (1,0) [0|1] "" Vector__XXX
 SG_ TRCM_a347_overvoltageError m347 : 18|1@1+ (1,0) [0|1] "" Vector__XXX
 SG_ TRCM_a347_currentMonitorTimer m347 : 24|8@1+ (16,0) [0|4080] "" Vector__XXX
 SG_ TRCM_a348_groundLossError m348 : 16|1@1+ (1,0) [0|1] "" Vector__XXX
 SG_ TRCM_a348_overcurrentError m348 : 17|1@1+ (1,0) [0|1] "" Vector__XXX
 SG_ TRCM_a348_overvoltageError m348 : 18|1@1+ (1,0) [0|1] "" Vector__XXX
 SG_ TRCM_a348_currentMonitorTimer m348 : 24|8@1+ (16,0) [0|4080] "" Vector__XXX
 SG_ TRCM_a349_groundLossError m349 : 16|1@1+ (1,0) [0|1] "" Vector__XXX
 SG_ TRCM_a349_overcurrentError m349 : 17|1@1+ (1,0) [0|1] "" Vector__XXX
 SG_ TRCM_a349_overvoltageError m349 : 18|1@1+ (1,0) [0|1] "" Vector__XXX
 SG_ TRCM_a349_currentMonitorTimer m349 : 24|8@1+ (16,0) [0|4080] "" Vector__XXX
 SG_ TRCM_a350_groundLossError m350 : 16|1@1+ (1,0) [0|1] "" Vector__XXX
 SG_ TRCM_a350_overcurrentError m350 : 17|1@1+ (1,0) [0|1] "" Vector__XXX
 SG_ TRCM_a350_overvoltageError m350 : 18|1@1+ (1,0) [0|1] "" Vector__XXX
 SG_ TRCM_a350_currentMonitorTimer m350 : 24|8@1+ (16,0) [0|4080] "" Vector__XXX
 SG_ TRCM_a351_groundLossError m351 : 16|1@1+ (1,0) [0|1] "" Vector__XXX
 SG_ TRCM_a351_overcurrentError m351 : 17|1@1+ (1,0) [0|1] "" Vector__XXX
 SG_ TRCM_a351_overvoltageError m351 : 18|1@1+ (1,0) [0|1] "" Vector__XXX
 SG_ TRCM_a351_currentMonitorTimer m351 : 24|8@1+ (16,0) [0|4080] "" Vector__XXX
 SG_ TRCM_a352_groundLossError m352 : 16|1@1+ (1,0) [0|1] "" Vector__XXX
 SG_ TRCM_a352_overcurrentError m352 : 17|1@1+ (1,0) [0|1] "" Vector__XXX
 SG_ TRCM_a352_overvoltageError m352 : 18|1@1+ (1,0) [0|1] "" Vector__XXX
 SG_ TRCM_a352_currentMonitorTimer m352 : 24|8@1+ (16,0) [0|4080] "" Vector__XXX
 SG_ TRCM_a353_groundLossError m353 : 16|1@1+ (1,0) [0|1] "" Vector__XXX
 SG_ TRCM_a353_overcurrentError m353 : 17|1@1+ (1,0) [0|1] "" Vector__XXX
 SG_ TRCM_a353_overvoltageError m353 : 18|1@1+ (1,0) [0|1] "" Vector__XXX
 SG_ TRCM_a353_currentMonitorTimer m353 : 24|8@1+ (16,0) [0|4080] "" Vector__XXX
 SG_ TRCM_a354_groundLossError m354 : 16|1@1+ (1,0) [0|1] "" Vector__XXX
 SG_ TRCM_a354_overcurrentError m354 : 17|1@1+ (1,0) [0|1] "" Vector__XXX
 SG_ TRCM_a354_overvoltageError m354 : 18|1@1+ (1,0) [0|1] "" Vector__XXX
 SG_ TRCM_a354_currentMonitorTimer m354 : 24|8@1+ (16,0) [0|4080] "" Vector__XXX
 SG_ TRCM_a355_groundLossError m355 : 16|1@1+ (1,0) [0|1] "" Vector__XXX
 SG_ TRCM_a355_overcurrentError m355 : 17|1@1+ (1,0) [0|1] "" Vector__XXX
 SG_ TRCM_a355_overvoltageError m355 : 18|1@1+ (1,0) [0|1] "" Vector__XXX
 SG_ TRCM_a355_currentMonitorTimer m355 : 24|8@1+ (16,0) [0|4080] "" Vector__XXX
 SG_ TRCM_a400_deploymentLoopNumber m400 : 16|5@1+ (1,0) [0|31] "" Vector__XXX
 SG_ TRCM_a400_resistance m400 : 24|8@1+ (0.05,0) [0|12.75] "" Vector__XXX
 SG_ TRCM_a400_shortToGround m400 : 32|1@1+ (1,0) [0|1] "" Vector__XXX
 SG_ TRCM_a400_shortToBattery m400 : 33|1@1+ (1,0) [0|1] "" Vector__XXX
 SG_ TRCM_a400_shortToSelf m400 : 34|1@1+ (1,0) [0|1] "" Vector__XXX
 SG_ TRCM_a400_openCircuit m400 : 35|1@1+ (1,0) [0|1] "" Vector__XXX
 SG_ TRCM_a400_crossCoupled m400 : 36|1@1+ (1,0) [0|1] "" Vector__XXX
 SG_ TRCM_a400_resistanceOutOfSpec m400 : 37|1@1+ (1,0) [0|1] "" Vector__XXX
 SG_ TRCM_a401_deploymentLoopNumber m401 : 16|5@1+ (1,0) [0|31] "" Vector__XXX
 SG_ TRCM_a401_resistance m401 : 24|8@1+ (0.05,0) [0|12.75] "" Vector__XXX
 SG_ TRCM_a401_shortToGround m401 : 32|1@1+ (1,0) [0|1] "" Vector__XXX
 SG_ TRCM_a401_shortToBattery m401 : 33|1@1+ (1,0) [0|1] "" Vector__XXX
 SG_ TRCM_a401_shortToSelf m401 : 34|1@1+ (1,0) [0|1] "" Vector__XXX
 SG_ TRCM_a401_openCircuit m401 : 35|1@1+ (1,0) [0|1] "" Vector__XXX
 SG_ TRCM_a401_crossCoupled m401 : 36|1@1+ (1,0) [0|1] "" Vector__XXX
 SG_ TRCM_a401_resistanceOutOfSpec m401 : 37|1@1+ (1,0) [0|1] "" Vector__XXX
 SG_ TRCM_a402_deploymentLoopNumber m402 : 16|5@1+ (1,0) [0|31] "" Vector__XXX
 SG_ TRCM_a402_resistance m402 : 24|8@1+ (0.05,0) [0|12.75] "" Vector__XXX
 SG_ TRCM_a402_shortToGround m402 : 32|1@1+ (1,0) [0|1] "" Vector__XXX
 SG_ TRCM_a402_shortToBattery m402 : 33|1@1+ (1,0) [0|1] "" Vector__XXX
 SG_ TRCM_a402_shortToSelf m402 : 34|1@1+ (1,0) [0|1] "" Vector__XXX
 SG_ TRCM_a402_openCircuit m402 : 35|1@1+ (1,0) [0|1] "" Vector__XXX
 SG_ TRCM_a402_crossCoupled m402 : 36|1@1+ (1,0) [0|1] "" Vector__XXX
 SG_ TRCM_a402_resistanceOutOfSpec m402 : 37|1@1+ (1,0) [0|1] "" Vector__XXX
 SG_ TRCM_a403_deploymentLoopNumber m403 : 16|5@1+ (1,0) [0|31] "" Vector__XXX
 SG_ TRCM_a403_resistance m403 : 24|8@1+ (0.05,0) [0|12.75] "" Vector__XXX
 SG_ TRCM_a403_shortToGround m403 : 32|1@1+ (1,0) [0|1] "" Vector__XXX
 SG_ TRCM_a403_shortToBattery m403 : 33|1@1+ (1,0) [0|1] "" Vector__XXX
 SG_ TRCM_a403_shortToSelf m403 : 34|1@1+ (1,0) [0|1] "" Vector__XXX
 SG_ TRCM_a403_openCircuit m403 : 35|1@1+ (1,0) [0|1] "" Vector__XXX
 SG_ TRCM_a403_crossCoupled m403 : 36|1@1+ (1,0) [0|1] "" Vector__XXX
 SG_ TRCM_a403_resistanceOutOfSpec m403 : 37|1@1+ (1,0) [0|1] "" Vector__XXX
 SG_ TRCM_a404_deploymentLoopNumber m404 : 16|5@1+ (1,0) [0|31] "" Vector__XXX
 SG_ TRCM_a404_resistance m404 : 24|8@1+ (0.05,0) [0|12.75] "" Vector__XXX
 SG_ TRCM_a404_shortToGround m404 : 32|1@1+ (1,0) [0|1] "" Vector__XXX
 SG_ TRCM_a404_shortToBattery m404 : 33|1@1+ (1,0) [0|1] "" Vector__XXX
 SG_ TRCM_a404_shortToSelf m404 : 34|1@1+ (1,0) [0|1] "" Vector__XXX
 SG_ TRCM_a404_openCircuit m404 : 35|1@1+ (1,0) [0|1] "" Vector__XXX
 SG_ TRCM_a404_crossCoupled m404 : 36|1@1+ (1,0) [0|1] "" Vector__XXX
 SG_ TRCM_a404_resistanceOutOfSpec m404 : 37|1@1+ (1,0) [0|1] "" Vector__XXX
 SG_ TRCM_a405_deploymentLoopNumber m405 : 16|5@1+ (1,0) [0|31] "" Vector__XXX
 SG_ TRCM_a405_resistance m405 : 24|8@1+ (0.05,0) [0|12.75] "" Vector__XXX
 SG_ TRCM_a405_shortToGround m405 : 32|1@1+ (1,0) [0|1] "" Vector__XXX
 SG_ TRCM_a405_shortToBattery m405 : 33|1@1+ (1,0) [0|1] "" Vector__XXX
 SG_ TRCM_a405_shortToSelf m405 : 34|1@1+ (1,0) [0|1] "" Vector__XXX
 SG_ TRCM_a405_openCircuit m405 : 35|1@1+ (1,0) [0|1] "" Vector__XXX
 SG_ TRCM_a405_crossCoupled m405 : 36|1@1+ (1,0) [0|1] "" Vector__XXX
 SG_ TRCM_a405_resistanceOutOfSpec m405 : 37|1@1+ (1,0) [0|1] "" Vector__XXX
 SG_ TRCM_a406_deploymentLoopNumber m406 : 16|5@1+ (1,0) [0|31] "" Vector__XXX
 SG_ TRCM_a406_resistance m406 : 24|8@1+ (0.05,0) [0|12.75] "" Vector__XXX
 SG_ TRCM_a406_shortToGround m406 : 32|1@1+ (1,0) [0|1] "" Vector__XXX
 SG_ TRCM_a406_shortToBattery m406 : 33|1@1+ (1,0) [0|1] "" Vector__XXX
 SG_ TRCM_a406_shortToSelf m406 : 34|1@1+ (1,0) [0|1] "" Vector__XXX
 SG_ TRCM_a406_openCircuit m406 : 35|1@1+ (1,0) [0|1] "" Vector__XXX
 SG_ TRCM_a406_crossCoupled m406 : 36|1@1+ (1,0) [0|1] "" Vector__XXX
 SG_ TRCM_a406_resistanceOutOfSpec m406 : 37|1@1+ (1,0) [0|1] "" Vector__XXX
 SG_ TRCM_a408_deploymentLoopNumber m408 : 16|5@1+ (1,0) [0|31] "" Vector__XXX
 SG_ TRCM_a408_resistance m408 : 24|8@1+ (0.05,0) [0|12.75] "" Vector__XXX
 SG_ TRCM_a408_shortToGround m408 : 32|1@1+ (1,0) [0|1] "" Vector__XXX
 SG_ TRCM_a408_shortToBattery m408 : 33|1@1+ (1,0) [0|1] "" Vector__XXX
 SG_ TRCM_a408_shortToSelf m408 : 34|1@1+ (1,0) [0|1] "" Vector__XXX
 SG_ TRCM_a408_openCircuit m408 : 35|1@1+ (1,0) [0|1] "" Vector__XXX
 SG_ TRCM_a408_crossCoupled m408 : 36|1@1+ (1,0) [0|1] "" Vector__XXX
 SG_ TRCM_a408_resistanceOutOfSpec m408 : 37|1@1+ (1,0) [0|1] "" Vector__XXX
 SG_ TRCM_a409_deploymentLoopNumber m409 : 16|5@1+ (1,0) [0|31] "" Vector__XXX
 SG_ TRCM_a409_resistance m409 : 24|8@1+ (0.05,0) [0|12.75] "" Vector__XXX
 SG_ TRCM_a409_shortToGround m409 : 32|1@1+ (1,0) [0|1] "" Vector__XXX
 SG_ TRCM_a409_shortToBattery m409 : 33|1@1+ (1,0) [0|1] "" Vector__XXX
 SG_ TRCM_a409_shortToSelf m409 : 34|1@1+ (1,0) [0|1] "" Vector__XXX
 SG_ TRCM_a409_openCircuit m409 : 35|1@1+ (1,0) [0|1] "" Vector__XXX
 SG_ TRCM_a409_crossCoupled m409 : 36|1@1+ (1,0) [0|1] "" Vector__XXX
 SG_ TRCM_a409_resistanceOutOfSpec m409 : 37|1@1+ (1,0) [0|1] "" Vector__XXX
 SG_ TRCM_a410_deploymentLoopNumber m410 : 16|5@1+ (1,0) [0|31] "" Vector__XXX
 SG_ TRCM_a410_resistance m410 : 24|8@1+ (0.05,0) [0|12.75] "" Vector__XXX
 SG_ TRCM_a410_shortToGround m410 : 32|1@1+ (1,0) [0|1] "" Vector__XXX
 SG_ TRCM_a410_shortToBattery m410 : 33|1@1+ (1,0) [0|1] "" Vector__XXX
 SG_ TRCM_a410_shortToSelf m410 : 34|1@1+ (1,0) [0|1] "" Vector__XXX
 SG_ TRCM_a410_openCircuit m410 : 35|1@1+ (1,0) [0|1] "" Vector__XXX
 SG_ TRCM_a410_crossCoupled m410 : 36|1@1+ (1,0) [0|1] "" Vector__XXX
 SG_ TRCM_a410_resistanceOutOfSpec m410 : 37|1@1+ (1,0) [0|1] "" Vector__XXX
 SG_ TRCM_a411_deploymentLoopNumber m411 : 16|5@1+ (1,0) [0|31] "" Vector__XXX
 SG_ TRCM_a411_resistance m411 : 24|8@1+ (0.05,0) [0|12.75] "" Vector__XXX
 SG_ TRCM_a411_shortToGround m411 : 32|1@1+ (1,0) [0|1] "" Vector__XXX
 SG_ TRCM_a411_shortToBattery m411 : 33|1@1+ (1,0) [0|1] "" Vector__XXX
 SG_ TRCM_a411_shortToSelf m411 : 34|1@1+ (1,0) [0|1] "" Vector__XXX
 SG_ TRCM_a411_openCircuit m411 : 35|1@1+ (1,0) [0|1] "" Vector__XXX
 SG_ TRCM_a411_crossCoupled m411 : 36|1@1+ (1,0) [0|1] "" Vector__XXX
 SG_ TRCM_a411_resistanceOutOfSpec m411 : 37|1@1+ (1,0) [0|1] "" Vector__XXX
 SG_ TRCM_a412_deploymentLoopNumber m412 : 16|5@1+ (1,0) [0|31] "" Vector__XXX
 SG_ TRCM_a412_resistance m412 : 24|8@1+ (0.05,0) [0|12.75] "" Vector__XXX
 SG_ TRCM_a412_shortToGround m412 : 32|1@1+ (1,0) [0|1] "" Vector__XXX
 SG_ TRCM_a412_shortToBattery m412 : 33|1@1+ (1,0) [0|1] "" Vector__XXX
 SG_ TRCM_a412_shortToSelf m412 : 34|1@1+ (1,0) [0|1] "" Vector__XXX
 SG_ TRCM_a412_openCircuit m412 : 35|1@1+ (1,0) [0|1] "" Vector__XXX
 SG_ TRCM_a412_crossCoupled m412 : 36|1@1+ (1,0) [0|1] "" Vector__XXX
 SG_ TRCM_a412_resistanceOutOfSpec m412 : 37|1@1+ (1,0) [0|1] "" Vector__XXX
 SG_ TRCM_a413_deploymentLoopNumber m413 : 16|5@1+ (1,0) [0|31] "" Vector__XXX
 SG_ TRCM_a413_resistance m413 : 24|8@1+ (0.05,0) [0|12.75] "" Vector__XXX
 SG_ TRCM_a413_shortToGround m413 : 32|1@1+ (1,0) [0|1] "" Vector__XXX
 SG_ TRCM_a413_shortToBattery m413 : 33|1@1+ (1,0) [0|1] "" Vector__XXX
 SG_ TRCM_a413_shortToSelf m413 : 34|1@1+ (1,0) [0|1] "" Vector__XXX
 SG_ TRCM_a413_openCircuit m413 : 35|1@1+ (1,0) [0|1] "" Vector__XXX
 SG_ TRCM_a413_crossCoupled m413 : 36|1@1+ (1,0) [0|1] "" Vector__XXX
 SG_ TRCM_a413_resistanceOutOfSpec m413 : 37|1@1+ (1,0) [0|1] "" Vector__XXX
 SG_ TRCM_a414_deploymentLoopNumber m414 : 16|5@1+ (1,0) [0|31] "" Vector__XXX
 SG_ TRCM_a414_resistance m414 : 24|8@1+ (0.05,0) [0|12.75] "" Vector__XXX
 SG_ TRCM_a414_shortToGround m414 : 32|1@1+ (1,0) [0|1] "" Vector__XXX
 SG_ TRCM_a414_shortToBattery m414 : 33|1@1+ (1,0) [0|1] "" Vector__XXX
 SG_ TRCM_a414_shortToSelf m414 : 34|1@1+ (1,0) [0|1] "" Vector__XXX
 SG_ TRCM_a414_openCircuit m414 : 35|1@1+ (1,0) [0|1] "" Vector__XXX
 SG_ TRCM_a414_crossCoupled m414 : 36|1@1+ (1,0) [0|1] "" Vector__XXX
 SG_ TRCM_a414_resistanceOutOfSpec m414 : 37|1@1+ (1,0) [0|1] "" Vector__XXX
 SG_ TRCM_a415_deploymentLoopNumber m415 : 16|5@1+ (1,0) [0|31] "" Vector__XXX
 SG_ TRCM_a415_resistance m415 : 24|8@1+ (0.05,0) [0|12.75] "" Vector__XXX
 SG_ TRCM_a415_shortToGround m415 : 32|1@1+ (1,0) [0|1] "" Vector__XXX
 SG_ TRCM_a415_shortToBattery m415 : 33|1@1+ (1,0) [0|1] "" Vector__XXX
 SG_ TRCM_a415_shortToSelf m415 : 34|1@1+ (1,0) [0|1] "" Vector__XXX
 SG_ TRCM_a415_openCircuit m415 : 35|1@1+ (1,0) [0|1] "" Vector__XXX
 SG_ TRCM_a415_crossCoupled m415 : 36|1@1+ (1,0) [0|1] "" Vector__XXX
 SG_ TRCM_a415_resistanceOutOfSpec m415 : 37|1@1+ (1,0) [0|1] "" Vector__XXX
 SG_ TRCM_a416_deploymentLoopNumber m416 : 16|5@1+ (1,0) [0|31] "" Vector__XXX
 SG_ TRCM_a416_resistance m416 : 24|8@1+ (0.05,0) [0|12.75] "" Vector__XXX
 SG_ TRCM_a416_shortToGround m416 : 32|1@1+ (1,0) [0|1] "" Vector__XXX
 SG_ TRCM_a416_shortToBattery m416 : 33|1@1+ (1,0) [0|1] "" Vector__XXX
 SG_ TRCM_a416_shortToSelf m416 : 34|1@1+ (1,0) [0|1] "" Vector__XXX
 SG_ TRCM_a416_openCircuit m416 : 35|1@1+ (1,0) [0|1] "" Vector__XXX
 SG_ TRCM_a416_crossCoupled m416 : 36|1@1+ (1,0) [0|1] "" Vector__XXX
 SG_ TRCM_a416_resistanceOutOfSpec m416 : 37|1@1+ (1,0) [0|1] "" Vector__XXX
 SG_ TRCM_a417_deploymentLoopNumber m417 : 16|5@1+ (1,0) [0|31] "" Vector__XXX
 SG_ TRCM_a417_resistance m417 : 24|8@1+ (0.05,0) [0|12.75] "" Vector__XXX
 SG_ TRCM_a417_shortToGround m417 : 32|1@1+ (1,0) [0|1] "" Vector__XXX
 SG_ TRCM_a417_shortToBattery m417 : 33|1@1+ (1,0) [0|1] "" Vector__XXX
 SG_ TRCM_a417_shortToSelf m417 : 34|1@1+ (1,0) [0|1] "" Vector__XXX
 SG_ TRCM_a417_openCircuit m417 : 35|1@1+ (1,0) [0|1] "" Vector__XXX
 SG_ TRCM_a417_crossCoupled m417 : 36|1@1+ (1,0) [0|1] "" Vector__XXX
 SG_ TRCM_a417_resistanceOutOfSpec m417 : 37|1@1+ (1,0) [0|1] "" Vector__XXX
 SG_ TRCM_a418_deploymentLoopNumber m418 : 16|5@1+ (1,0) [0|31] "" Vector__XXX
 SG_ TRCM_a418_resistance m418 : 24|8@1+ (0.05,0) [0|12.75] "" Vector__XXX
 SG_ TRCM_a418_shortToGround m418 : 32|1@1+ (1,0) [0|1] "" Vector__XXX
 SG_ TRCM_a418_shortToBattery m418 : 33|1@1+ (1,0) [0|1] "" Vector__XXX
 SG_ TRCM_a418_shortToSelf m418 : 34|1@1+ (1,0) [0|1] "" Vector__XXX
 SG_ TRCM_a418_openCircuit m418 : 35|1@1+ (1,0) [0|1] "" Vector__XXX
 SG_ TRCM_a418_crossCoupled m418 : 36|1@1+ (1,0) [0|1] "" Vector__XXX
 SG_ TRCM_a418_resistanceOutOfSpec m418 : 37|1@1+ (1,0) [0|1] "" Vector__XXX
 SG_ TRCM_a419_deploymentLoopNumber m419 : 16|5@1+ (1,0) [0|31] "" Vector__XXX
 SG_ TRCM_a419_resistance m419 : 24|8@1+ (0.05,0) [0|12.75] "" Vector__XXX
 SG_ TRCM_a419_shortToGround m419 : 32|1@1+ (1,0) [0|1] "" Vector__XXX
 SG_ TRCM_a419_shortToBattery m419 : 33|1@1+ (1,0) [0|1] "" Vector__XXX
 SG_ TRCM_a419_shortToSelf m419 : 34|1@1+ (1,0) [0|1] "" Vector__XXX
 SG_ TRCM_a419_openCircuit m419 : 35|1@1+ (1,0) [0|1] "" Vector__XXX
 SG_ TRCM_a419_crossCoupled m419 : 36|1@1+ (1,0) [0|1] "" Vector__XXX
 SG_ TRCM_a419_resistanceOutOfSpec m419 : 37|1@1+ (1,0) [0|1] "" Vector__XXX
 SG_ TRCM_a420_deploymentLoopNumber m420 : 16|5@1+ (1,0) [0|31] "" Vector__XXX
 SG_ TRCM_a420_resistance m420 : 24|8@1+ (0.05,0) [0|12.75] "" Vector__XXX
 SG_ TRCM_a420_shortToGround m420 : 32|1@1+ (1,0) [0|1] "" Vector__XXX
 SG_ TRCM_a420_shortToBattery m420 : 33|1@1+ (1,0) [0|1] "" Vector__XXX
 SG_ TRCM_a420_shortToSelf m420 : 34|1@1+ (1,0) [0|1] "" Vector__XXX
 SG_ TRCM_a420_openCircuit m420 : 35|1@1+ (1,0) [0|1] "" Vector__XXX
 SG_ TRCM_a420_crossCoupled m420 : 36|1@1+ (1,0) [0|1] "" Vector__XXX
 SG_ TRCM_a420_resistanceOutOfSpec m420 : 37|1@1+ (1,0) [0|1] "" Vector__XXX
 SG_ TRCM_a421_deploymentLoopNumber m421 : 16|5@1+ (1,0) [0|31] "" Vector__XXX
 SG_ TRCM_a421_resistance m421 : 24|8@1+ (0.05,0) [0|12.75] "" Vector__XXX
 SG_ TRCM_a421_shortToGround m421 : 32|1@1+ (1,0) [0|1] "" Vector__XXX
 SG_ TRCM_a421_shortToBattery m421 : 33|1@1+ (1,0) [0|1] "" Vector__XXX
 SG_ TRCM_a421_shortToSelf m421 : 34|1@1+ (1,0) [0|1] "" Vector__XXX
 SG_ TRCM_a421_openCircuit m421 : 35|1@1+ (1,0) [0|1] "" Vector__XXX
 SG_ TRCM_a421_crossCoupled m421 : 36|1@1+ (1,0) [0|1] "" Vector__XXX
 SG_ TRCM_a421_resistanceOutOfSpec m421 : 37|1@1+ (1,0) [0|1] "" Vector__XXX
 SG_ TRCM_a422_deploymentLoopNumber m422 : 16|5@1+ (1,0) [0|31] "" Vector__XXX
 SG_ TRCM_a422_resistance m422 : 24|8@1+ (0.05,0) [0|12.75] "" Vector__XXX
 SG_ TRCM_a422_shortToGround m422 : 32|1@1+ (1,0) [0|1] "" Vector__XXX
 SG_ TRCM_a422_shortToBattery m422 : 33|1@1+ (1,0) [0|1] "" Vector__XXX
 SG_ TRCM_a422_shortToSelf m422 : 34|1@1+ (1,0) [0|1] "" Vector__XXX
 SG_ TRCM_a422_openCircuit m422 : 35|1@1+ (1,0) [0|1] "" Vector__XXX
 SG_ TRCM_a422_crossCoupled m422 : 36|1@1+ (1,0) [0|1] "" Vector__XXX
 SG_ TRCM_a422_resistanceOutOfSpec m422 : 37|1@1+ (1,0) [0|1] "" Vector__XXX
 SG_ TRCM_a423_deploymentLoopNumber m423 : 16|5@1+ (1,0) [0|31] "" Vector__XXX
 SG_ TRCM_a423_resistance m423 : 24|8@1+ (0.05,0) [0|12.75] "" Vector__XXX
 SG_ TRCM_a423_shortToGround m423 : 32|1@1+ (1,0) [0|1] "" Vector__XXX
 SG_ TRCM_a423_shortToBattery m423 : 33|1@1+ (1,0) [0|1] "" Vector__XXX
 SG_ TRCM_a423_shortToSelf m423 : 34|1@1+ (1,0) [0|1] "" Vector__XXX
 SG_ TRCM_a423_openCircuit m423 : 35|1@1+ (1,0) [0|1] "" Vector__XXX
 SG_ TRCM_a423_crossCoupled m423 : 36|1@1+ (1,0) [0|1] "" Vector__XXX
 SG_ TRCM_a423_resistanceOutOfSpec m423 : 37|1@1+ (1,0) [0|1] "" Vector__XXX

CM_ BO_ 852 "Air suspension controller message: alert matrix";
CM_ SG_ 852 TAS_matrixIndex "Air suspension controller: matrix index";
CM_ SG_ 852 TAS_a001_WatchdogReset "Air suspension controller: a001 watchdog reset";
CM_ SG_ 852 TAS_a002_PowerLossReset "Air suspension controller: a002 power loss reset";
CM_ SG_ 852 TAS_a003_SWAssertion "Air suspension controller: a003 SW assertion";
CM_ SG_ 852 TAS_a012_CPUReset "Air suspension controller: a012 CPU reset";
CM_ SG_ 852 TAS_a015_NVMMError "Air suspension controller: a015 NVMM error";
CM_ SG_ 852 TAS_a016_NVMMRecordError "Air suspension controller: a016 NVMM record error";
CM_ SG_ 852 TAS_a021_TaskSchedulerError "Air suspension controller: a021 task scheduler error";
CM_ SG_ 852 TAS_a022_TaskInitError "Air suspension controller: a022 task init error";
CM_ SG_ 852 TAS_a023_rtosResetRequested "Air suspension controller: a023 rtos reset requested";
CM_ SG_ 852 TAS_a024_prefetchAbort "Air suspension controller: a024 prefetch abort";
CM_ SG_ 852 TAS_a025_CrashEvent "Air suspension controller: a025 crash event";
CM_ SG_ 852 TAS_a030_PWMerrorFL "Air suspension controller: a030 PW merror FL";
CM_ SG_ 852 TAS_a031_PWMerrorFR "Air suspension controller: a031 PW merror FR";
CM_ SG_ 852 TAS_a032_PWMerrorRL "Air suspension controller: a032 PW merror RL";
CM_ SG_ 852 TAS_a033_PWMerrorRR "Air suspension controller: a033 PW merror RR";
CM_ SG_ 852 TAS_a034_PWMshortFL "Air suspension controller: a034 PW mshort FL";
CM_ SG_ 852 TAS_a035_PWMshortFR "Air suspension controller: a035 PW mshort FR";
CM_ SG_ 852 TAS_a036_PWMshortRL "Air suspension controller: a036 PW mshort RL";
CM_ SG_ 852 TAS_a037_PWMshortRR "Air suspension controller: a037 PW mshort RR";
CM_ SG_ 852 TAS_a038_PWMopenFL "Air suspension controller: a038 PW mopen FL";
CM_ SG_ 852 TAS_a039_PWMopenFR "Air suspension controller: a039 PW mopen FR";
CM_ SG_ 852 TAS_a040_PWMopenRL "Air suspension controller: a040 PW mopen RL";
CM_ SG_ 852 TAS_a041_PWMopenRR "Air suspension controller: a041 PW mopen RR";
CM_ SG_ 852 TAS_a043_Task1msError "Air suspension controller: a043 task1ms error";
CM_ SG_ 852 TAS_a044_Task10msError "Air suspension controller: a044 task10ms error";
CM_ SG_ 852 TAS_a045_Task100msError "Air suspension controller: a045 task100ms error";
CM_ SG_ 852 TAS_a046_Task1000msError "Air suspension controller: a046 task1000ms error";
CM_ SG_ 852 TAS_a061_XCPConnected "Air suspension controller: a061 XCP connected";
CM_ SG_ 852 TAS_a062_XCPWasConnected "Air suspension controller: a062 XCP was connected";
CM_ SG_ 852 TAS_a063_abortFault "Air suspension controller: a063 abort fault";
CM_ SG_ 852 TAS_a064_abortFaultExt "Air suspension controller: a064 abort fault ext";
CM_ SG_ 852 TAS_a065_ahbWriteFault "Air suspension controller: a065 ahb write fault";
CM_ SG_ 852 TAS_a066_undefinedInstructionAbo "Air suspension controller: a066 undefined instruction abort";
CM_ SG_ 852 TAS_a067_reservedHandlerAbort "Air suspension controller: a067 reserved handler abort";
CM_ SG_ 852 TAS_a070_underVoltage12V "Air suspension controller: a070 under voltage12 v";
CM_ SG_ 852 TAS_a071_overVoltage12V "Air suspension controller: a071 over voltage12 v";
CM_ SG_ 852 TAS_a072_shortCircuit5VOnBoard "Air suspension controller: a072 short circuit5 v on board";
CM_ SG_ 852 TAS_a073_underVoltage5VOnBoard "Air suspension controller: a073 under voltage5 v on board";
CM_ SG_ 852 TAS_a074_shortCircuit5VOffBoard "Air suspension controller: a074 short circuit5 v off board";
CM_ SG_ 852 TAS_a075_underVoltage5VOffBoard "Air suspension controller: a075 under voltage5 v off board";
CM_ SG_ 852 TAS_a076_overVoltage5VOffBoard "Air suspension controller: a076 over voltage5 v off board";
CM_ SG_ 852 TAS_a077_pressureSigVTooLow "Air suspension controller: a077 pressure sig v too low";
CM_ SG_ 852 TAS_a078_pressureSigVTooHigh "Air suspension controller: a078 pressure sig v too high";
CM_ SG_ 852 TAS_a080_shortCircuit5VHeight "Air suspension controller: a080 short circuit5 v height";
CM_ SG_ 852 TAS_a081_underVoltage5VHeight "Air suspension controller: a081 under voltage5 v height";
CM_ SG_ 852 TAS_a082_overVoltage5VHeight "Air suspension controller: a082 over voltage5 v height";
CM_ SG_ 852 TAS_a083_shortCircuit5VAnalog "Air suspension controller: a083 short circuit5 v analog";
CM_ SG_ 852 TAS_a084_underVoltage5VAnalog "Air suspension controller: a084 under voltage5 v analog";
CM_ SG_ 852 TAS_a085_overVoltage5VAnalog "Air suspension controller: a085 over voltage5 v analog";
CM_ SG_ 852 TAS_a086_underVoltage12VSwtchd "Air suspension controller: a086 under voltage12 v swtchd";
CM_ SG_ 852 TAS_a087_overVoltage12VSwtchd "Air suspension controller: a087 over voltage12 v swtchd";
CM_ SG_ 852 TAS_a093_OTPError "Air suspension controller: a093 OTP error";
CM_ SG_ 852 TAS_a098_VCFRONT_MIA "Air suspension controller: a098 VCFRONT MIA";
CM_ SG_ 852 TAS_a099_UI_MIA "Air suspension controller: a099 UI MIA";
CM_ SG_ 852 TAS_a100_RCM_MIA "Air suspension controller: a100 RCM MIA";
CM_ SG_ 852 TAS_a101_ESP_MIA "Air suspension controller: a101 ESP MIA";
CM_ SG_ 852 TAS_a102_DI_MIA "Air suspension controller: a102 DI MIA";
CM_ SG_ 852 TAS_a103_GTW_MIA "Air suspension controller: a103 GTW MIA";
CM_ SG_ 852 TAS_a105_ECUDebugMode "Air suspension controller: a105 ECU debug mode";
CM_ SG_ 852 TAS_a106_HighCPULoad "Air suspension controller: a106 high CPU load";
CM_ SG_ 852 TAS_a107_HighStackUsage "Air suspension controller: a107 high stack usage";
CM_ SG_ 852 TAS_a150_accelAvgImplausible_FL_ "Air suspension controller: a150 accel avg implausible FL x";
CM_ SG_ 852 TAS_a151_accelAvgImplausible_FL_ "Air suspension controller: a151 accel avg implausible FL y";
CM_ SG_ 852 TAS_a152_accelAvgImplausible_FL_ "Air suspension controller: a152 accel avg implausible FL z";
CM_ SG_ 852 TAS_a153_accelAvgImplausible_FR_ "Air suspension controller: a153 accel avg implausible FR x";
CM_ SG_ 852 TAS_a154_accelAvgImplausible_FR_ "Air suspension controller: a154 accel avg implausible FR y";
CM_ SG_ 852 TAS_a155_accelAvgImplausible_FR_ "Air suspension controller: a155 accel avg implausible FR z";
CM_ SG_ 852 TAS_a156_accelAvgImplausible_RL_ "Air suspension controller: a156 accel avg implausible RL x";
CM_ SG_ 852 TAS_a157_accelAvgImplausible_RL_ "Air suspension controller: a157 accel avg implausible RL y";
CM_ SG_ 852 TAS_a158_accelAvgImplausible_RL_ "Air suspension controller: a158 accel avg implausible RL z";
CM_ SG_ 852 TAS_a159_accelAvgImplausible_RR_ "Air suspension controller: a159 accel avg implausible RR x";
CM_ SG_ 852 TAS_a160_accelAvgImplausible_RR_ "Air suspension controller: a160 accel avg implausible RR y";
CM_ SG_ 852 TAS_a161_accelAvgImplausible_RR_ "Air suspension controller: a161 accel avg implausible RR z";
CM_ SG_ 852 TAS_a164_damperSolenoidMismatch "Air suspension controller: a164 damper solenoid mismatch";
CM_ SG_ 852 TAS_a165_damperValveCompFL "Air suspension controller: a165 damper valve comp FL";
CM_ SG_ 852 TAS_a166_damperValveRbndFL "Air suspension controller: a166 damper valve rbnd FL";
CM_ SG_ 852 TAS_a167_damperValveCompFR "Air suspension controller: a167 damper valve comp FR";
CM_ SG_ 852 TAS_a168_damperValveRbndFR "Air suspension controller: a168 damper valve rbnd FR";
CM_ SG_ 852 TAS_a169_damperValveCompRL "Air suspension controller: a169 damper valve comp RL";
CM_ SG_ 852 TAS_a170_damperValveRbndRL "Air suspension controller: a170 damper valve rbnd RL";
CM_ SG_ 852 TAS_a171_damperValveCompRR "Air suspension controller: a171 damper valve comp RR";
CM_ SG_ 852 TAS_a172_damperValveRbndRR "Air suspension controller: a172 damper valve rbnd RR";
CM_ SG_ 852 TAS_a173_staticLeakDetectFL "Air suspension controller: a173 static leak detect FL";
CM_ SG_ 852 TAS_a174_staticLeakDetectFR "Air suspension controller: a174 static leak detect FR";
CM_ SG_ 852 TAS_a175_staticLeakDetectRL "Air suspension controller: a175 static leak detect RL";
CM_ SG_ 852 TAS_a176_staticLeakDetectRR "Air suspension controller: a176 static leak detect RR";
CM_ SG_ 852 TAS_a190_a2bFrontAxleFault "Air suspension controller: a190 a2b front axle fault";
CM_ SG_ 852 TAS_a191_a2bRearAxleFault "Air suspension controller: a191 a2b rear axle fault";
CM_ SG_ 852 TAS_a192_rideHeightObserverDiver "Air suspension controller: a192 ride height observer divergence";
CM_ SG_ 852 TAS_a193_EPAS3P_MIA "Air suspension controller: a193 EPAS3 p MIA";
CM_ SG_ 852 TAS_a194_a2bFrontAxleDataError "Air suspension controller: a194 a2b front axle data error";
CM_ SG_ 852 TAS_a195_a2bRearAxleDataError "Air suspension controller: a195 a2b rear axle data error";
CM_ SG_ 852 TAS_a196_adaptiveDampingUsingDSP "Air suspension controller: a196 adaptive damping using DSP";
CM_ SG_ 852 TAS_a197_invalidAdaptiveModeRequ "Air suspension controller: a197 invalid adaptive mode requested";
CM_ SG_ 852 TAS_a198_a2bFrontAxleExtendedDis "Air suspension controller: a198 a2b front axle extended discovery time";
CM_ SG_ 852 TAS_a199_a2bRearAxleExtendedDisc "Air suspension controller: a199 a2b rear axle extended discovery time";
CM_ SG_ 852 TAS_a200_jackModeActive "Air suspension controller: a200 jack mode active";
CM_ SG_ 852 TAS_a201_low12VBattery "Air suspension controller: a201 low12 v battery";
CM_ SG_ 852 TAS_a210_outOfRangeCalibration "Air suspension controller: a210 out of range calibration";
CM_ SG_ 852 TAS_a211_noRideHeightCalib "Air suspension controller: a211 no ride height calib";
CM_ SG_ 852 TAS_a213_yellowWarningLamp "Air suspension controller: a213 yellow warning lamp";
CM_ SG_ 852 TAS_a214_redWarningLamp "Air suspension controller: a214 red warning lamp";
CM_ SG_ 852 TAS_a215_limpHomeMode10 "Air suspension controller: a215 limp home mode10";
CM_ SG_ 852 TAS_a216_limpHomeMode20 "Air suspension controller: a216 limp home mode20";
CM_ SG_ 852 TAS_a217_limpHomeMode30 "Air suspension controller: a217 limp home mode30";
CM_ SG_ 852 TAS_a218_limpHomeMode40 "Air suspension controller: a218 limp home mode40";
CM_ SG_ 852 TAS_a220_exhaustGalleryFault "Air suspension controller: a220 exhaust gallery fault";
CM_ SG_ 852 TAS_a221_valveLeakDetected "Air suspension controller: a221 valve leak detected";
CM_ SG_ 852 TAS_a222_compressorPrefillFault "Air suspension controller: a222 compressor prefill fault";
CM_ SG_ 852 TAS_a223_blockedAirline "Air suspension controller: a223 blocked airline";
CM_ SG_ 852 TAS_a224_openAirline "Air suspension controller: a224 open airline";
CM_ SG_ 852 TAS_a225_galleryPressureTooHigh "Air suspension controller: a225 gallery pressure too high";
CM_ SG_ 852 TAS_a226_PWMfastDetectFL "Air suspension controller: a226 PW mfast detect FL";
CM_ SG_ 852 TAS_a227_PWMfastDetectFR "Air suspension controller: a227 PW mfast detect FR";
CM_ SG_ 852 TAS_a228_PWMfastDetectRL "Air suspension controller: a228 PW mfast detect RL";
CM_ SG_ 852 TAS_a229_PWMfastDetectRR "Air suspension controller: a229 PW mfast detect RR";
CM_ SG_ 852 TAS_a230_notifyGeofence "Air suspension controller: a230 notify geofence";
CM_ SG_ 852 TAS_a231_notifyRoughRoadRaise "Air suspension controller: a231 notify rough road raise";
CM_ SG_ 852 TAS_a232_suspensionTypeMismatch "Air suspension controller: a232 suspension type mismatch";
CM_ SG_ 852 TAS_a233_compressorStuckOn "Air suspension controller: a233 compressor stuck on";
CM_ SG_ 852 TAS_a234_damperHydraulicMismatch "Air suspension controller: a234 damper hydraulic mismatch";
CM_ SG_ 852 TAS_a240_airSpringLeak "Air suspension controller: a240 air spring leak";
CM_ SG_ 852 TAS_a284_serviceRunModeActive "Air suspension controller: a284 service run mode active";
CM_ SG_ 852 TAS_a285_twistSustainedUserVis "Air suspension controller: a285 twist sustained user vis";
CM_ SG_ 852 TAS_a286_driveCycleStats1 "Air suspension controller: a286 drive cycle stats1";
CM_ SG_ 852 TAS_a287_driveCycleStats2 "Air suspension controller: a287 drive cycle stats2";
CM_ SG_ 852 TAS_a288_driveCycleStats3 "Air suspension controller: a288 drive cycle stats3";
CM_ SG_ 852 TAS_a289_driveCycleStats4 "Air suspension controller: a289 drive cycle stats4";
CM_ SG_ 852 TAS_a290_twistSustainedAtSpeed "Air suspension controller: a290 twist sustained at speed";
CM_ SG_ 852 TAS_a291_frontAxleTooHigh "Air suspension controller: a291 front axle too high";
CM_ SG_ 852 TAS_a292_rearAxleTooHigh "Air suspension controller: a292 rear axle too high";
CM_ SG_ 852 TAS_a293_frontAxleTooLow "Air suspension controller: a293 front axle too low";
CM_ SG_ 852 TAS_a294_rearAxleTooLow "Air suspension controller: a294 rear axle too low";
CM_ SG_ 852 TAS_a295_targetHeightNotMet "Air suspension controller: a295 target height not met";
CM_ SG_ 852 TAS_a296_chassisTypeMismatch "Air suspension controller: a296 chassis type mismatch";
CM_ SG_ 852 TAS_a297_vinMismatch "Air suspension controller: a297 vin mismatch";
CM_ SG_ 852 TAS_a298_vinNotLearned "Air suspension controller: a298 vin not learned";
CM_ SG_ 852 TAS_a299_offsetEstimateTooLarge "Air suspension controller: a299 offset estimate too large";
CM_ SG_ 852 TAS_a300_offsetEstimateData1 "Air suspension controller: a300 offset estimate data1";
CM_ SG_ 852 TAS_a301_offsetEstimateData2 "Air suspension controller: a301 offset estimate data2";
CM_ SG_ 852 TAS_a303_massEstimateFrozen "Air suspension controller: a303 mass estimate frozen";
CM_ SG_ 852 TAS_a304_massEstimateFrozenData "Air suspension controller: a304 mass estimate frozen data";
CM_ SG_ 852 TAS_a305_newEndstopPosition "Air suspension controller: a305 new endstop position";
CM_ SG_ 852 TAS_a306_hardwareProtectFrozen "Air suspension controller: a306 hardware protect frozen";
CM_ SG_ 852 TAS_a307_endstopBoundaryComp "Air suspension controller: a307 endstop boundary comp";
CM_ SG_ 852 TAS_a308_endstopBoundaryRbnd "Air suspension controller: a308 endstop boundary rbnd";
CM_ SG_ 852 TAS_a309_controlFrozen "Air suspension controller: a309 control frozen";
CM_ SG_ 852 TAS_a310_controlFrozenData "Air suspension controller: a310 control frozen data";
CM_ SG_ 852 TAS_a311_accelsMIA "Air suspension controller: a311 accels MIA";
CM_ SG_ 852 TAS_a312_rotationalRatesMIA "Air suspension controller: a312 rotational rates MIA";
CM_ SG_ 852 TAS_a313_dampingCntrlDisabled "Air suspension controller: a313 damping cntrl disabled";
CM_ SG_ 852 TAS_a314_dampingReduced "Air suspension controller: a314 damping reduced";
CM_ SG_ 852 TAS_a315_pcbaHighTemp "Air suspension controller: a315 pcba high temp";
CM_ SG_ 852 TAS_a316_offsetsAccels "Air suspension controller: a316 offsets accels";
CM_ SG_ 852 TAS_a317_offsetsRotationalRates "Air suspension controller: a317 offsets rotational rates";
CM_ SG_ 852 TAS_a318_dampingCntrlInputMIA "Air suspension controller: a318 damping cntrl input MIA";
CM_ SG_ 852 TAS_a319_drivetrainTypeMismatch "Air suspension controller: a319 drivetrain type mismatch";
CM_ SG_ 852 TAS_a320_offsetsRotationalRates "Air suspension controller: a320 offsets rotational rates";
CM_ SG_ 852 TAS_a321_speedBumpAttributes1 "Air suspension controller: a321 speed bump attributes1";
CM_ SG_ 852 TAS_a322_speedBumpAttributes2 "Air suspension controller: a322 speed bump attributes2";
CM_ SG_ 852 TAS_a332_levelingThresholds1 "Air suspension controller: a332 leveling thresholds1";
CM_ SG_ 852 TAS_a333_levelingThresholds2 "Air suspension controller: a333 leveling thresholds2";
CM_ SG_ 852 TAS_a343_damperValveControlCompF "Air suspension controller: a343 damper valve control comp FL";
CM_ SG_ 852 TAS_a344_damperValveControlRbndF "Air suspension controller: a344 damper valve control rbnd FL";
CM_ SG_ 852 TAS_a345_damperValveControlCompF "Air suspension controller: a345 damper valve control comp FR";
CM_ SG_ 852 TAS_a346_damperValveControlRbndF "Air suspension controller: a346 damper valve control rbnd FR";
CM_ SG_ 852 TAS_a347_damperValveControlCompR "Air suspension controller: a347 damper valve control comp RL";
CM_ SG_ 852 TAS_a348_damperValveControlRbndR "Air suspension controller: a348 damper valve control rbnd RL";
CM_ SG_ 852 TAS_a349_damperValveControlCompR "Air suspension controller: a349 damper valve control comp RR";
CM_ SG_ 852 TAS_a350_damperValveControlRbndR "Air suspension controller: a350 damper valve control rbnd RR";
CM_ BO_ 523 "Air suspension controller message: axle data";
CM_ SG_ 523 TAS_axleIndex "Air suspension controller: axle index";
CM_ SG_ 523 TAS_rawHeightFL "Current height of the FL air spring.";
CM_ SG_ 523 TAS_staticHeightEstimateFL "Current static height estimate of the FL air spring.";
CM_ SG_ 523 TAS_componentPressureFL "Current static pressure of the FL air spring.";
CM_ SG_ 523 TAS_rawHeightFR "Current height of the FR air spring.";
CM_ SG_ 523 TAS_staticHeightEstimateFR "Current static height estimate of the FR air spring.";
CM_ SG_ 523 TAS_componentPressureFR "Current static pressure of the FR air spring.";
CM_ SG_ 523 TAS_rawHeightRL "Current height of the RL air spring.";
CM_ SG_ 523 TAS_staticHeightEstimateRL "Current static height estimate of the RL air spring.";
CM_ SG_ 523 TAS_componentPressureRL "Current static pressure of the RL air spring.";
CM_ SG_ 523 TAS_rawHeightRR "Current height of the RR air spring.";
CM_ SG_ 523 TAS_staticHeightEstimateRR "Current static height estimate of the RR air spring.";
CM_ SG_ 523 TAS_componentPressureRR "Current static pressure of the RR air spring.";
CM_ BO_ 1398 "Air suspension controller message: damping states";
CM_ SG_ 1398 TAS_endstopState "Air suspension controller: endstop state";
CM_ SG_ 1398 TAS_continuousControlState "SW-237496";
CM_ SG_ 1398 TAS_activeTireTune "Air suspension controller: active tire tune";
CM_ SG_ 1398 TAS_roughnessRaiseReason "Air suspension controller: roughness raise reason";
CM_ SG_ 1398 TAS_frontMetricDrivesRear "Air suspension controller: front metric drives rear";
CM_ SG_ 1398 TAS_roadCondition "Air suspension controller: road condition";
CM_ SG_ 1398 TAS_bellyProtect "Air suspension controller: belly protect";
CM_ SG_ 1398 TAS_frontMetricDrivesFront "Air suspension controller: front metric drives front";
CM_ SG_ 1398 TAS_speedBumpAxleFront "Air suspension controller: speed bump axle front";
CM_ SG_ 1398 TAS_speedBumpAxleRear "Air suspension controller: speed bump axle rear";
CM_ SG_ 1398 TAS_holeProtectFL "Air suspension controller: hole protect FL";
CM_ SG_ 1398 TAS_holeProtectFR "Air suspension controller: hole protect FR";
CM_ SG_ 1398 TAS_holeProtectRL "Air suspension controller: hole protect RL";
CM_ SG_ 1398 TAS_holeProtectRR "Air suspension controller: hole protect RR";
CM_ SG_ 1398 TAS_stepProtectFL "Air suspension controller: step protect FL";
CM_ SG_ 1398 TAS_stepProtectFR "Air suspension controller: step protect FR";
CM_ SG_ 1398 TAS_stepProtectRL "Air suspension controller: step protect RL";
CM_ SG_ 1398 TAS_stepProtectRR "Air suspension controller: step protect RR";
CM_ SG_ 1398 TAS_FDUTorqueCorruptionScale "Air suspension controller: FDU torque corruption scale";
CM_ SG_ 1398 TAS_sprungMassEstimate "Air suspension controller: sprung mass estimate";
CM_ SG_ 1398 TAS_anyDamperActive "Air suspension controller: any damper active";
CM_ SG_ 1398 TAS_dampingStatesCounter "Air suspension controller: damping states counter";
CM_ SG_ 1398 TAS_dampingStatesChecksum "Air suspension controller: damping states checksum";
CM_ BO_ 1357 "Air suspension controller message: info";
CM_ SG_ 1357 TAS_infoIndex "Air suspension controller: info index";
CM_ SG_ 1357 TAS_infoBuildType "Air suspension controller: info build type";
CM_ SG_ 1357 TAS_infoBuildConfigId "Air suspension controller: info build config id";
CM_ SG_ 1357 TAS_infoHardwareId "Air suspension controller: info hardware id";
CM_ SG_ 1357 TAS_infoComponentId "Air suspension controller: info component id";
CM_ SG_ 1357 TAS_infoPcbaId "Air suspension controller: info pcba id";
CM_ SG_ 1357 TAS_infoAssemblyId "Air suspension controller: info assembly id";
CM_ SG_ 1357 TAS_infoUsageId "Air suspension controller: info usage id";
CM_ SG_ 1357 TAS_infoSubUsageId "Air suspension controller: info sub usage id";
CM_ SG_ 1357 TAS_infoAppCrc "Air suspension controller: info app crc";
CM_ SG_ 1357 TAS_infoAppGitHash "Air suspension controller: info app git hash";
CM_ SG_ 1357 TAS_infoBootGitHash "Air suspension controller: info boot git hash";
CM_ SG_ 1357 TAS_infoPlatformType "Air suspension controller: info platform type";
CM_ SG_ 1357 TAS_infoMajorVersion "Air suspension controller: info major version";
CM_ SG_ 1357 TAS_infoBranchOrigin "Air suspension controller: info branch origin";
CM_ SG_ 1357 TAS_infoMaturity "Air suspension controller: info maturity";
CM_ SG_ 1357 TAS_infoHardwareRevision "Air suspension controller: info hardware revision";
CM_ BO_ 525 "Air suspension controller message: states";
CM_ SG_ 525 TAS_levelingState "Indicates air suspension leveling state.";
CM_ SG_ 525 TAS_levelingItem "Indicates the currently active air suspension components.";
CM_ SG_ 525 TAS_pressureGallery "Current air suspension valve block gallery pressure.";
CM_ SG_ 525 TAS_pressureReservoir "Indicates the latest valid reservoir pressure.";
CM_ SG_ 525 TAS_runMode "Indicates the status of run mode.";
CM_ SG_ 525 TAS_filterMode "Indicates the status of filter mode.";
CM_ SG_ 525 TAS_compressorRun "Either an indication that the compressor is running or a request to run the air compressor";
CM_ SG_ 525 TAS_twistDetected "TAS has detected large amount of twist.";
CM_ SG_ 525 TAS_leanDetected "TAS has detected vehicle to be leaning left or right.";
CM_ SG_ 525 TAS_limpHomeMode "Indicates which limp home mode is active.";
CM_ SG_ 525 TAS_targetLevel "Indicates target ride height.";
CM_ SG_ 525 TAS_currentLevel "Indicates current ride height.";
CM_ SG_ 525 TAS_jackMode "Indicates the status of Jack mode.";
CM_ SG_ 525 TAS_reduceVehicleSpeedRequest "Air suspension controller: reduce vehicle speed request";
CM_ SG_ 525 TAS_statesCounter "Air suspension controller: states counter";
CM_ SG_ 525 TAS_statesChecksum "Air suspension controller: states checksum";
CM_ BO_ 409 "Air suspension controller message: ui adaptive activity0";
CM_ SG_ 409 TAS_adaptiveActivityFL_C "Air suspension controller: adaptive activity FL c";
CM_ SG_ 409 TAS_adaptiveActivityFL_R "Air suspension controller: adaptive activity FL r";
CM_ SG_ 409 TAS_adaptiveActivityFR_C "Air suspension controller: adaptive activity FR c";
CM_ SG_ 409 TAS_adaptiveActivityFR_R "Air suspension controller: adaptive activity FR r";
CM_ SG_ 409 TAS_adaptiveActivityRL_C "Air suspension controller: adaptive activity RL c";
CM_ SG_ 409 TAS_adaptiveActivityRL_R "Air suspension controller: adaptive activity RL r";
CM_ SG_ 409 TAS_adaptiveActivityRR_C "Air suspension controller: adaptive activity RR c";
CM_ SG_ 409 TAS_adaptiveActivityRR_R "Air suspension controller: adaptive activity RR r";
CM_ SG_ 409 TAS_uiHeightFL "Air suspension controller: ui height FL";
CM_ SG_ 409 TAS_uiHeightFR "Air suspension controller: ui height FR";
CM_ SG_ 409 TAS_uiHeightRL "Air suspension controller: ui height RL";
CM_ SG_ 409 TAS_uiHeightRR "Air suspension controller: ui height RR";
CM_ BO_ 410 "Air suspension controller message: ui adaptive activity1";
CM_ SG_ 410 TAS_bodyAccelFL "Air suspension controller: body accel FL";
CM_ SG_ 410 TAS_bodyAccelFR "Air suspension controller: body accel FR";
CM_ SG_ 410 TAS_bodyAccelRL "Air suspension controller: body accel RL";
CM_ SG_ 410 TAS_bodyAccelRR "Air suspension controller: body accel RR";
CM_ BO_ 538 "Air suspension controller message: ui control";
CM_ SG_ 538 TAS_yellowWarningLamp "Air suspension controller: yellow warning lamp";
CM_ SG_ 538 TAS_redWarningLamp "Air suspension controller: red warning lamp";
CM_ SG_ 538 TAS_veryLowAllowed "Air suspension controller: very low allowed";
CM_ SG_ 538 TAS_lowAllowed "Air suspension controller: low allowed";
CM_ SG_ 538 TAS_standardAllowed "Air suspension controller: standard allowed";
CM_ SG_ 538 TAS_highAllowed "Air suspension controller: high allowed";
CM_ SG_ 538 TAS_veryHighAllowed "Air suspension controller: very high allowed";
CM_ SG_ 538 TAS_extractAllowed "Air suspension controller: extract allowed";
CM_ SG_ 538 TAS_showSpinner "Air suspension controller: show spinner";
CM_ SG_ 538 TAS_adaptiveRideModeOverride "Air suspension controller: adaptive ride mode override";
CM_ SG_ 538 TAS_levelSelectEnabled "Air suspension controller: level select enabled";
CM_ SG_ 538 TAS_jackModeToggleEnabled "Air suspension controller: jack mode toggle enabled";
CM_ SG_ 538 TAS_adaptiveRideSelectEnabled "Air suspension controller: adaptive ride select enabled";
CM_ SG_ 538 TAS_launchModeState "Air suspension controller: launch mode state";
CM_ SG_ 538 TAS_restrictUpLevelingFalcons "Air suspension controller: restrict up leveling falcons";
CM_ SG_ 538 TAS_restrictUpLevelingTrunk "Air suspension controller: restrict up leveling trunk";
CM_ SG_ 538 TAS_restrictDownLevelingDoors "Air suspension controller: restrict down leveling doors";
CM_ SG_ 538 TAS_restrictLevelingChargeCable "Air suspension controller: restrict leveling charge cable";
CM_ SG_ 538 TAS_restrictLevelingSystemCheck "Air suspension controller: restrict leveling system check";
CM_ SG_ 538 TAS_restrictLevelingTransport "Air suspension controller: restrict leveling transport";
CM_ SG_ 538 TAS_restrictLevelingShowroom "Indication that up and down leveling are restricted while showroom mode is active.";
CM_ SG_ 538 TAS_uiControlCounter "Air suspension controller: ui control counter";
CM_ SG_ 538 TAS_uiControlChecksum "Air suspension controller: ui control checksum";
CM_ BO_ 1415 "TCU2 ECU message: sleep config";
CM_ SG_ 1415 TCU2_tc10Version "Indicates which version of Open Alliance's TC10 protocol is supported by the modem.";
CM_ BO_ 1413 "TCU2 ECU message: alert log";
CM_ SG_ 1413 TCU2_alertID "TCU2 ECU: alert ID";
CM_ SG_ 1413 TCU2_alertState "TCU2 ECU: alert state";
CM_ SG_ 1413 TCU2_w001_FailCode "TCU2 ECU: w001 fail code";
CM_ SG_ 1413 TCU2_w002_RejCause "TCU2 ECU: w002 rej cause";
CM_ SG_ 1413 TCU2_w003_CallFailCode "TCU2 ECU: w003 call fail code";
CM_ SG_ 1413 TCU2_w004_MSDFailCode "TCU2 ECU: w004 MSD fail code";
CM_ SG_ 1413 TCU2_w006_Count "TCU2 ECU: w006 count";
CM_ SG_ 1413 TCU2_w007_Count "TCU2 ECU: w007 count";
CM_ SG_ 1413 TCU2_w009_CrashCode "TCU2 ECU: w009 crash code";
CM_ SG_ 1413 TCU2_w012_DataRAT "TCU2 ECU: w012 data RAT";
CM_ SG_ 1413 TCU2_w012_RSRP "TCU2 ECU: w012 RSRP";
CM_ SG_ 1413 TCU2_w012_RSRQ "TCU2 ECU: w012 RSRQ";
CM_ SG_ 1413 TCU2_w012_MNC "TCU2 ECU: w012 MNC";
CM_ SG_ 1413 TCU2_w012_AvgQueueUsage "TCU2 ECU: w012 avg queue usage";
CM_ SG_ 1413 TCU2_w012_NSAAvailable "TCU2 ECU: w012 NSA available";
CM_ SG_ 1413 TCU2_w013_DataRAT "TCU2 ECU: w013 data RAT";
CM_ SG_ 1413 TCU2_w013_RSRP "TCU2 ECU: w013 RSRP";
CM_ SG_ 1413 TCU2_w013_RSRQ "TCU2 ECU: w013 RSRQ";
CM_ SG_ 1413 TCU2_w013_MNC "TCU2 ECU: w013 MNC";
CM_ SG_ 1413 TCU2_w013_AvgQueueUsage "TCU2 ECU: w013 avg queue usage";
CM_ SG_ 1413 TCU2_w013_NSAAvailable "TCU2 ECU: w013 NSA available";
CM_ SG_ 1413 TCU2_w014_Reason "TCU2 ECU: w014 reason";
CM_ BO_ 1414 "TCU2 ECU message: alert matrix1";
CM_ SG_ 1414 TCU2_w001_IMSRegistrationFailed "TCU2 ECU: w001 IMS registration failed";
CM_ SG_ 1414 TCU2_w002_CellRegRejected "TCU2 ECU: w002 cell reg rejected";
CM_ SG_ 1414 TCU2_w003_ECallFailed "TCU2 ECU: w003 e call failed";
CM_ SG_ 1414 TCU2_w004_MSDTransmissionFailed "TCU2 ECU: w004 MSD transmission failed";
CM_ SG_ 1414 TCU2_w005_SIMSlotError "TCU2 ECU: w005 SIM slot error";
CM_ SG_ 1414 TCU2_w006_MpssUnavailable "TCU2 ECU: w006 mpss unavailable";
CM_ SG_ 1414 TCU2_w007_ModemUnreachable "TCU2 ECU: w007 modem unreachable";
CM_ SG_ 1414 TCU2_w008_KernelPanic "TCU2 ECU: w008 kernel panic";
CM_ SG_ 1414 TCU2_w009_WifiFirmwareCrash "TCU2 ECU: w009 wifi firmware crash";
CM_ SG_ 1414 TCU2_w010_WifiDumpDetected "TCU2 ECU: w010 wifi dump detected";
CM_ SG_ 1414 TCU2_w011_CellDumpDetected "TCU2 ECU: w011 cell dump detected";
CM_ SG_ 1414 TCU2_w012_UplinkDegraded "TCU2 ECU: w012 uplink degraded";
CM_ SG_ 1414 TCU2_w013_UplinkQueueFull "TCU2 ECU: w013 uplink queue full";
CM_ SG_ 1414 TCU2_w014_HostapdCrash "TCU2 ECU: w014 hostapd crash";
CM_ SG_ 1414 TCU2_w015_NPNSubscriptionActive "TCU2 ECU: w015 NPN subscription active";
CM_ SG_ 1414 TCU2_w016_IMEIMismatch "TCU2 ECU: w016 IMEI mismatch";
CM_ BO_ 1412 "TCU2 ECU message: log";
CM_ SG_ 1412 TCU2_logMux "TCU2 ECU: log mux";
CM_ SG_ 1412 TCU2_cpuTemp "Indicates the current temperature reported by the Central Processing Unit (CPU) in the modem application processor";
CM_ SG_ 1412 TCU2_cpuUsage "Indicates the current CPU usage in percentage reported by the modem application processor";
CM_ SG_ 1412 TCU2_mdmCoreTemperature "Indicates the current Communication Processor (CP) temperature reported by the modem CP.";
CM_ SG_ 1412 TCU2_availableMemory "Indicates the currently available Random Access Memory in the modem application processor";
CM_ SG_ 1412 TCU2_pwm "Indicates the active Pulse Width Modulation (PWM) duty cycle applied to the modem fan.";
CM_ SG_ 1412 TCU2_pwmcap "Indicates the active Pulse Width Modulation (PWM) duty cycle restriciton applied to the modem fan.";
CM_ SG_ 1412 TCU2_totalResumes "Indicates the total amount of times the modem has been resumed";
CM_ SG_ 1412 TCU2_mdmUplinkQueueSize "TCU2 ECU: mdm uplink queue size";
CM_ SG_ 1412 TCU2_mdmRSRP "TCU2 ECU: mdm RSRP";
CM_ SG_ 1412 TCU2_mdmSINR "TCU2 ECU: mdm SINR";
CM_ SG_ 1412 TCU2_mdmUplinkAllowedRate "TCU2 ECU: mdm uplink allowed rate";
CM_ SG_ 1412 TCU2_mdmUplinkAvgRate "TCU2 ECU: mdm uplink avg rate";
CM_ SG_ 1412 TCU2_mdmServiceState "TCU2 ECU: mdm service state";
CM_ SG_ 1412 TCU2_mdmIMSStatus "Indicates the current IP Multimedia System (IMS) registration state.";
CM_ SG_ 1412 TCU2_mdmSIMStatus "TCU2 ECU: mdm SIM status";
CM_ SG_ 1412 TCU2_mdmBusyActive "Reports whether the modem busy service is active on the modem application processor.";
CM_ SG_ 1412 TCU2_modemUptime "Indicates the current modem Application Processor uptime.";
CM_ SG_ 1412 TCU2_mdmDataRat "Reports which Radio Access Technology (RAT) is active for the current data bearer.";
CM_ SG_ 1412 TCU2_mdmDataCallStatus "Indicates the current state of the Packet Data Protocol (PDP) context.";
CM_ SG_ 1412 TCU2_mdmNSAAvailable "TCU2 ECU: mdm NSA available";
CM_ SG_ 1412 TCU2_mdmPCIID "TCU2 ECU: mdm PCIID";
CM_ SG_ 1412 TCU2_mdmMnc "TCU2 ECU: mdm mnc";
CM_ SG_ 1412 TCU2_mdmMcc "TCU2 ECU: mdm mcc";
CM_ SG_ 1412 TCU2_mdmTxKiloBytes "TCU2 ECU: mdm tx kilo bytes";
CM_ SG_ 1412 TCU2_mdmDataCallTermReason "Indicates the internal reason which the Data Call was terminated.";
CM_ SG_ 1412 TCU2_mdmDataCallTermCode "Indicates the termination code informed by the network that caused the Data Call termination.";
CM_ SG_ 1412 TCU2_cellularSMState "Indicates the current state of cellular state machine.";
CM_ SG_ 1412 TCU2_tcuSMState "Reports the state of the Telematics Control Unit (TCU) state machine.";
CM_ SG_ 1412 TCU2_checkInternetFailCount "Reports the count of unsuccessful cellular connectivity checks.";
CM_ SG_ 1412 TCU2_mdmBand "Indicates the band which the baseband processor is currently attached to the cellular network.";
CM_ SG_ 1412 TCU2_wakeSource "Indicates the source of wake event in the modem.";
CM_ BO_ 1159 "TCU ECU message: sleep config";
CM_ SG_ 1159 TCU_tc10Version "Indicates which version of Open Alliance's TC10 protocol is supported by the modem.";
CM_ BO_ 1157 "TCU ECU message: alert log";
CM_ SG_ 1157 TCU_alertID "TCU ECU: alert ID";
CM_ SG_ 1157 TCU_alertState "TCU ECU: alert state";
CM_ SG_ 1157 TCU_w001_FailCode "TCU ECU: w001 fail code";
CM_ SG_ 1157 TCU_w002_RejCause "TCU ECU: w002 rej cause";
CM_ SG_ 1157 TCU_w003_CallFailCode "TCU ECU: w003 call fail code";
CM_ SG_ 1157 TCU_w004_MSDFailCode "TCU ECU: w004 MSD fail code";
CM_ SG_ 1157 TCU_w006_Count "TCU ECU: w006 count";
CM_ SG_ 1157 TCU_w007_Count "TCU ECU: w007 count";
CM_ SG_ 1157 TCU_w009_CrashCode "TCU ECU: w009 crash code";
CM_ SG_ 1157 TCU_w012_DataRAT "TCU ECU: w012 data RAT";
CM_ SG_ 1157 TCU_w012_RSRP "TCU ECU: w012 RSRP";
CM_ SG_ 1157 TCU_w012_RSRQ "TCU ECU: w012 RSRQ";
CM_ SG_ 1157 TCU_w012_MNC "TCU ECU: w012 MNC";
CM_ SG_ 1157 TCU_w012_AvgQueueUsage "TCU ECU: w012 avg queue usage";
CM_ SG_ 1157 TCU_w012_NSAAvailable "TCU ECU: w012 NSA available";
CM_ SG_ 1157 TCU_w013_DataRAT "TCU ECU: w013 data RAT";
CM_ SG_ 1157 TCU_w013_RSRP "TCU ECU: w013 RSRP";
CM_ SG_ 1157 TCU_w013_RSRQ "TCU ECU: w013 RSRQ";
CM_ SG_ 1157 TCU_w013_MNC "TCU ECU: w013 MNC";
CM_ SG_ 1157 TCU_w013_AvgQueueUsage "TCU ECU: w013 avg queue usage";
CM_ SG_ 1157 TCU_w013_NSAAvailable "TCU ECU: w013 NSA available";
CM_ SG_ 1157 TCU_w014_Reason "TCU ECU: w014 reason";
CM_ BO_ 1158 "TCU ECU message: alert matrix1";
CM_ SG_ 1158 TCU_w001_IMSRegistrationFailed "TCU ECU: w001 IMS registration failed";
CM_ SG_ 1158 TCU_w002_CellRegRejected "TCU ECU: w002 cell reg rejected";
CM_ SG_ 1158 TCU_w003_ECallFailed "TCU ECU: w003 e call failed";
CM_ SG_ 1158 TCU_w004_MSDTransmissionFailed "TCU ECU: w004 MSD transmission failed";
CM_ SG_ 1158 TCU_w005_SIMSlotError "TCU ECU: w005 SIM slot error";
CM_ SG_ 1158 TCU_w006_MpssUnavailable "TCU ECU: w006 mpss unavailable";
CM_ SG_ 1158 TCU_w007_ModemUnreachable "TCU ECU: w007 modem unreachable";
CM_ SG_ 1158 TCU_w008_KernelPanic "TCU ECU: w008 kernel panic";
CM_ SG_ 1158 TCU_w009_WifiFirmwareCrash "TCU ECU: w009 wifi firmware crash";
CM_ SG_ 1158 TCU_w010_WifiDumpDetected "TCU ECU: w010 wifi dump detected";
CM_ SG_ 1158 TCU_w011_CellDumpDetected "TCU ECU: w011 cell dump detected";
CM_ SG_ 1158 TCU_w012_UplinkDegraded "TCU ECU: w012 uplink degraded";
CM_ SG_ 1158 TCU_w013_UplinkQueueFull "TCU ECU: w013 uplink queue full";
CM_ SG_ 1158 TCU_w014_HostapdCrash "TCU ECU: w014 hostapd crash";
CM_ SG_ 1158 TCU_w015_NPNSubscriptionActive "TCU ECU: w015 NPN subscription active";
CM_ SG_ 1158 TCU_w016_IMEIMismatch "TCU ECU: w016 IMEI mismatch";
CM_ BO_ 1155 "TCU ECU message: log";
CM_ SG_ 1155 TCU_logMux "TCU ECU: log mux";
CM_ SG_ 1155 TCU_cpuTemp "Indicates the current temperature reported by the Central Processing Unit (CPU) in the modem application processor";
CM_ SG_ 1155 TCU_cpuUsage "Indicates the current CPU usage in percentage reported by the modem application processor";
CM_ SG_ 1155 TCU_mdmCoreTemperature "Indicates the current Communication Processor (CP) temperature reported by the modem CP.";
CM_ SG_ 1155 TCU_availableMemory "Indicates the currently available Random Access Memory in the modem application processor";
CM_ SG_ 1155 TCU_pwm "Indicates the active Pulse Width Modulation (PWM) duty cycle applied to the modem fan.";
CM_ SG_ 1155 TCU_pwmcap "Indicates the active Pulse Width Modulation (PWM) duty cycle restriciton applied to the modem fan.";
CM_ SG_ 1155 TCU_totalResumes "Indicates the total amount of times the modem has been resumed";
CM_ SG_ 1155 TCU_mdmUplinkQueueSize "TCU ECU: mdm uplink queue size";
CM_ SG_ 1155 TCU_mdmRSRP "TCU ECU: mdm RSRP";
CM_ SG_ 1155 TCU_mdmSINR "TCU ECU: mdm SINR";
CM_ SG_ 1155 TCU_mdmUplinkAllowedRate "TCU ECU: mdm uplink allowed rate";
CM_ SG_ 1155 TCU_mdmUplinkAvgRate "TCU ECU: mdm uplink avg rate";
CM_ SG_ 1155 TCU_mdmServiceState "TCU ECU: mdm service state";
CM_ SG_ 1155 TCU_mdmIMSStatus "Indicates the current IP Multimedia System (IMS) registration state.";
CM_ SG_ 1155 TCU_mdmSIMStatus "TCU ECU: mdm SIM status";
CM_ SG_ 1155 TCU_mdmBusyActive "Reports whether the modem busy service is active on the modem application processor.";
CM_ SG_ 1155 TCU_modemUptime "Indicates the current modem Application Processor uptime.";
CM_ SG_ 1155 TCU_mdmDataRat "Reports which Radio Access Technology (RAT) is active for the current data bearer.";
CM_ SG_ 1155 TCU_mdmDataCallStatus "Indicates the current state of the Packet Data Protocol (PDP) context.";
CM_ SG_ 1155 TCU_mdmNSAAvailable "TCU ECU: mdm NSA available";
CM_ SG_ 1155 TCU_mdmPCIID "TCU ECU: mdm PCIID";
CM_ SG_ 1155 TCU_mdmMnc "TCU ECU: mdm mnc";
CM_ SG_ 1155 TCU_mdmMcc "TCU ECU: mdm mcc";
CM_ SG_ 1155 TCU_mdmTxKiloBytes "TCU ECU: mdm tx kilo bytes";
CM_ SG_ 1155 TCU_mdmDataCallTermReason "Indicates the internal reason which the Data Call was terminated.";
CM_ SG_ 1155 TCU_mdmDataCallTermCode "Indicates the termination code informed by the network that caused the Data Call termination.";
CM_ SG_ 1155 TCU_cellularSMState "Indicates the current state of cellular state machine.";
CM_ SG_ 1155 TCU_tcuSMState "Reports the state of the Telematics Control Unit (TCU) state machine.";
CM_ SG_ 1155 TCU_checkInternetFailCount "Reports the count of unsuccessful cellular connectivity checks.";
CM_ SG_ 1155 TCU_mdmBand "Indicates the band which the baseband processor is currently attached to the cellular network.";
CM_ SG_ 1155 TCU_wakeSource "Indicates the source of wake event in the modem.";
CM_ BO_ 879 "Tire pressure monitoring message: status c";
CM_ SG_ 879 TPMS_c_globalHardWarning "Tire pressure monitoring: c global hard warning";
CM_ SG_ 879 TPMS_c_globalSoftWarning "Tire pressure monitoring: c global soft warning";
CM_ SG_ 879 TPMS_systemMalfunction "Tire pressure monitoring: system malfunction";
CM_ SG_ 879 TPMS_WA_version "Tire pressure monitoring: WA version";
CM_ SG_ 879 TPMS_globalDeltaPressure "Tire pressure monitoring: global delta pressure";
CM_ SG_ 879 TPMS_newSensorLearnt "Tire pressure monitoring: new sensor learnt";
CM_ SG_ 879 TPMS_softWarningRR "Tire pressure monitoring: soft warning RR";
CM_ SG_ 879 TPMS_hardWarningRR "Tire pressure monitoring: hard warning RR";
CM_ SG_ 879 TPMS_softWarningRL "Tire pressure monitoring: soft warning RL";
CM_ SG_ 879 TPMS_hardWarningRL "Tire pressure monitoring: hard warning RL";
CM_ SG_ 879 TPMS_softWarningFR "Tire pressure monitoring: soft warning FR";
CM_ SG_ 879 TPMS_hardWarningFR "Tire pressure monitoring: hard warning FR";
CM_ SG_ 879 TPMS_softWarningFL "Tire pressure monitoring: soft warning FL";
CM_ SG_ 879 TPMS_hardWarningFL "Tire pressure monitoring: hard warning FL";
CM_ SG_ 879 TPMS_learningStatus "Monitors Tire Pressure Monitoring System (TPMS) Learn Status and evaluates issues.";
CM_ SG_ 879 TPMS_localisationStatus "Monitors Tire Pressure Monitoring System (TPMS) Localization Status and evaluates issues.";
CM_ SG_ 879 TPMS_deltaPressWarningFL "Tire pressure monitoring: delta press warning FL";
CM_ SG_ 879 TPMS_deltaPressWarningFR "Tire pressure monitoring: delta press warning FR";
CM_ SG_ 879 TPMS_deltaPressWarningRL "Tire pressure monitoring: delta press warning RL";
CM_ SG_ 879 TPMS_deltaPressWarningRR "Tire pressure monitoring: delta press warning RR";
CM_ SG_ 879 TPMS_sensorNoResponseFL "Count of times Front Left sensor did not respond to message";
CM_ SG_ 879 TPMS_sensorNoResponseFR "Count of times Front Right sensor did not respond to message";
CM_ SG_ 879 TPMS_sensorNoResponseRL "Count of times Rear Left sensor did not respond to message";
CM_ SG_ 879 TPMS_sensorNoResponseRR "Count of times Rear Right sensor did not respond to message";
CM_ SG_ 879 TPMS_sensorThermShutdownFL "Tire pressure monitoring: sensor therm shutdown FL";
CM_ SG_ 879 TPMS_sensorThermShutdownFR "Tire pressure monitoring: sensor therm shutdown FR";
CM_ SG_ 879 TPMS_sensorThermShutdownRL "Tire pressure monitoring: sensor therm shutdown RL";
CM_ SG_ 879 TPMS_sensorThermShutdownRR "Tire pressure monitoring: sensor therm shutdown RR";
CM_ SG_ 879 TPMS_sensorBatteryLowFL "Tracks near end of life sensor batteries in the fleet.";
CM_ SG_ 879 TPMS_sensorBatteryLowFR "Tracks near end of life sensor batteries in the fleet.";
CM_ SG_ 879 TPMS_sensorBatteryLowRL "Tracks near end of life sensor batteries in the fleet.";
CM_ SG_ 879 TPMS_sensorBatteryLowRR "Tracks near end of life sensor batteries in the fleet.";
CM_ SG_ 879 TPMS_sensorDefectiveFL "Tracks malfunctioning sensors in the fleet.";
CM_ SG_ 879 TPMS_sensorDefectiveFR "Tracks malfunctioning sensors in the fleet.";
CM_ SG_ 879 TPMS_sensorDefectiveRL "Tracks malfunctioning sensors in the fleet.";
CM_ SG_ 879 TPMS_sensorDefectiveRR "Tracks malfunctioning sensors in the fleet.";
CM_ SG_ 879 TPMS_ecuUnderVoltage "Tire pressure monitoring: ecu under voltage";
CM_ SG_ 879 TPMS_ecuOverVoltage "Tire pressure monitoring: ecu over voltage";
CM_ SG_ 879 TPMS_ecuRamRomNvMFail "Tire pressure monitoring: ecu ram rom nv m fail";
CM_ SG_ 879 TPMS_rfReceiverFail "Tire pressure monitoring: rf receiver fail";
CM_ SG_ 879 TPMS_wheelPulseMissing "Tire pressure monitoring: wheel pulse missing";
CM_ SG_ 879 TPMS_vehicleSpeedFail "Tire pressure monitoring: vehicle speed fail";
CM_ SG_ 879 TPMS_externalTemperatureFail "Tire pressure monitoring: external temperature fail";
CM_ SG_ 879 TPMS_eolNotCompleted "Monitors sensor completion of End of Line (EOL) routine.";
CM_ SG_ 879 TPMS_rcpFront "Front tire recommended cold pressure";
CM_ SG_ 879 TPMS_rcpRear "Rear tire recommended cold pressure";
CM_ BO_ 802 "Tire pressure monitoring message: data";
CM_ SG_ 802 TPMS_pressureFL "front left tire pressure";
CM_ SG_ 802 TPMS_temperatureFL "front left tire temperature";
CM_ SG_ 802 TPMS_pressureFR "front right tire pressure";
CM_ SG_ 802 TPMS_temperatureFR "front right tire temperature";
CM_ SG_ 802 TPMS_pressureRL "rear left tire pressure";
CM_ SG_ 802 TPMS_temperatureRL "rear left tire temperature";
CM_ SG_ 802 TPMS_pressureRR "rear right tire pressure";
CM_ SG_ 802 TPMS_temperatureRR "rear right tire temperature";
CM_ BO_ 1519 "Tire pressure monitoring message: info";
CM_ SG_ 1519 TPMS_infoIndex "Tire pressure monitoring: info index";
CM_ SG_ 1519 TPMS_infoComponentID "Tire pressure monitoring: info component ID";
CM_ SG_ 1519 TPMS_infoPcbaID "Tire pressure monitoring: info pcba ID";
CM_ SG_ 1519 TPMS_infoAssemblyID "Tire pressure monitoring: info assembly ID";
CM_ SG_ 1519 TPMS_infoUsageID "Tire pressure monitoring: info usage ID";
CM_ SG_ 1519 TPMS_infoApplicationCRC "Tire pressure monitoring: info application CRC";
CM_ SG_ 1519 TPMS_infoBootUdsProtoVersion "Tire pressure monitoring: info boot uds proto version";
CM_ SG_ 1519 TPMS_infoBootloaderCRC "Tire pressure monitoring: info bootloader CRC";
CM_ BO_ 1298 "TRCM ECU message: alert log";
CM_ SG_ 1298 TRCM_alertID "TRCM ECU: alert ID";
CM_ SG_ 1298 TRCM_alertState "TRCM ECU: alert state";
CM_ SG_ 1298 TRCM_a015_NVMMMemOverflow "TRCM ECU: a015 NVMM mem overflow";
CM_ SG_ 1298 TRCM_a015_NVMMFilesystemError "TRCM ECU: a015 NVMM filesystem error";
CM_ SG_ 1298 TRCM_a015_NVMMRecordIDError "TRCM ECU: a015 NVMM record ID error";
CM_ SG_ 1298 TRCM_a017_tempData "TRCM ECU: a017 temp data";
CM_ SG_ 1298 TRCM_a018_tempData "TRCM ECU: a018 temp data";
CM_ SG_ 1298 TRCM_a035_eventArmStatus "TRCM ECU: a035 event arm status";
CM_ SG_ 1298 TRCM_a035_eventFrontLeftSeatbelt "TRCM ECU: a035 event front left seatbelt";
CM_ SG_ 1298 TRCM_a035_eventFrontRightSeatbel "TRCM ECU: a035 event front right seatbelt";
CM_ SG_ 1298 TRCM_a035_eventVehicleSpeed "TRCM ECU: a035 event vehicle speed";
CM_ SG_ 1298 TRCM_a035_eventDriverBrakeApply "TRCM ECU: a035 event driver brake apply";
CM_ SG_ 1298 TRCM_a035_eventAccelPedalPos "TRCM ECU: a035 event accel pedal pos";
CM_ SG_ 1298 TRCM_a036_collisionType "TRCM ECU: a036 collision type";
CM_ SG_ 1298 TRCM_a036_collisionSeverity "TRCM ECU: a036 collision severity";
CM_ SG_ 1298 TRCM_a036_eventArmStatus "TRCM ECU: a036 event arm status";
CM_ SG_ 1298 TRCM_a036_eventFrontLeftSeatbelt "TRCM ECU: a036 event front left seatbelt";
CM_ SG_ 1298 TRCM_a036_eventFrontRightSeatbel "TRCM ECU: a036 event front right seatbelt";
CM_ SG_ 1298 TRCM_a036_eventVehicleSpeed "TRCM ECU: a036 event vehicle speed";
CM_ SG_ 1298 TRCM_a036_eventDriverBrakeApply "TRCM ECU: a036 event driver brake apply";
CM_ SG_ 1298 TRCM_a036_eventAccelPedalPos "TRCM ECU: a036 event accel pedal pos";
CM_ SG_ 1298 TRCM_a037_nearDeployFront "TRCM ECU: a037 near deploy front";
CM_ SG_ 1298 TRCM_a037_nearDeployRear "TRCM ECU: a037 near deploy rear";
CM_ SG_ 1298 TRCM_a037_nearDeployLeft "TRCM ECU: a037 near deploy left";
CM_ SG_ 1298 TRCM_a037_nearDeployRight "TRCM ECU: a037 near deploy right";
CM_ SG_ 1298 TRCM_a037_nearDeployRoll "TRCM ECU: a037 near deploy roll";
CM_ SG_ 1298 TRCM_a037_eventArmStatus "TRCM ECU: a037 event arm status";
CM_ SG_ 1298 TRCM_a037_eventFrontLeftSeatbelt "TRCM ECU: a037 event front left seatbelt";
CM_ SG_ 1298 TRCM_a037_eventFrontRightSeatbel "TRCM ECU: a037 event front right seatbelt";
CM_ SG_ 1298 TRCM_a037_eventVehicleSpeed "TRCM ECU: a037 event vehicle speed";
CM_ SG_ 1298 TRCM_a037_eventDriverBrakeApply "TRCM ECU: a037 event driver brake apply";
CM_ SG_ 1298 TRCM_a037_eventAccelPedalPos "TRCM ECU: a037 event accel pedal pos";
CM_ SG_ 1298 TRCM_a038_stuckLowOrOpenCircuit "TRCM ECU: a038 stuck low or open circuit";
CM_ SG_ 1298 TRCM_a038_stuckHigh "TRCM ECU: a038 stuck high";
CM_ SG_ 1298 TRCM_a038_overCurrent "TRCM ECU: a038 over current";
CM_ SG_ 1298 TRCM_a038_driverOverTemperature "TRCM ECU: a038 driver over temperature";
CM_ SG_ 1298 TRCM_a039_stuckLowOrOpenCircuit "TRCM ECU: a039 stuck low or open circuit";
CM_ SG_ 1298 TRCM_a039_stuckHigh "TRCM ECU: a039 stuck high";
CM_ SG_ 1298 TRCM_a039_overCurrent "TRCM ECU: a039 over current";
CM_ SG_ 1298 TRCM_a039_driverOverTemperature "TRCM ECU: a039 driver over temperature";
CM_ SG_ 1298 TRCM_a057_VEH_cpControl "TRCM ECU: a057 VEH cp control";
CM_ SG_ 1298 TRCM_a059_voltageDrop "TRCM ECU: a059 voltage drop";
CM_ SG_ 1298 TRCM_a059_resistanceEstimate "TRCM ECU: a059 resistance estimate";
CM_ SG_ 1298 TRCM_a059_current "TRCM ECU: a059 current";
CM_ SG_ 1298 TRCM_a063_switchChannel "TRCM ECU: a063 switch channel";
CM_ SG_ 1298 TRCM_a063_switchType "TRCM ECU: a063 switch type";
CM_ SG_ 1298 TRCM_a063_ADCVoltage "TRCM ECU: a063 ADC voltage";
CM_ SG_ 1298 TRCM_a063_disconnected "TRCM ECU: a063 disconnected";
CM_ SG_ 1298 TRCM_a063_indeterminate "TRCM ECU: a063 indeterminate";
CM_ SG_ 1298 TRCM_a063_stuckActive "TRCM ECU: a063 stuck active";
CM_ SG_ 1298 TRCM_a063_faulted "TRCM ECU: a063 faulted";
CM_ SG_ 1298 TRCM_a065_vsafingFetVoltage "TRCM ECU: a065 vsafing fet voltage";
CM_ SG_ 1298 TRCM_a066_busVoltage "TRCM ECU: a066 bus voltage";
CM_ SG_ 1298 TRCM_a078_channelIndex "TRCM ECU: a078 channel index";
CM_ SG_ 1298 TRCM_a078_value "TRCM ECU: a078 value";
CM_ SG_ 1298 TRCM_a081_eventArmStatus "TRCM ECU: a081 event arm status";
CM_ SG_ 1298 TRCM_a081_eventFrontLeftSeatbelt "TRCM ECU: a081 event front left seatbelt";
CM_ SG_ 1298 TRCM_a081_eventFrontRightSeatbel "TRCM ECU: a081 event front right seatbelt";
CM_ SG_ 1298 TRCM_a081_eventVehicleSpeed "TRCM ECU: a081 event vehicle speed";
CM_ SG_ 1298 TRCM_a081_eventDriverBrakeApply "TRCM ECU: a081 event driver brake apply";
CM_ SG_ 1298 TRCM_a081_eventAccelPedalPos "TRCM ECU: a081 event accel pedal pos";
CM_ SG_ 1298 TRCM_a082_RIPC_epbPrivateState "TRCM ECU: a082 RIPC epb private state";
CM_ SG_ 1298 TRCM_a082_RIPC_remoteHSD "TRCM ECU: a082 RIPC remote HSD";
CM_ SG_ 1298 TRCM_a082_RIPC_railStatus "TRCM ECU: a082 RIPC rail status";
CM_ SG_ 1298 TRCM_a082_RIPC_remoteMux "TRCM ECU: a082 RIPC remote mux";
CM_ SG_ 1298 TRCM_a083_LIPC_epbPrivateState "TRCM ECU: a083 LIPC epb private state";
CM_ SG_ 1298 TRCM_a083_LIPC_remoteHSD "TRCM ECU: a083 LIPC remote HSD";
CM_ SG_ 1298 TRCM_a083_LIPC_railStatus "TRCM ECU: a083 LIPC rail status";
CM_ SG_ 1298 TRCM_a083_LIPC_HSDFaults "TRCM ECU: a083 LIPC HSD faults";
CM_ SG_ 1298 TRCM_a084_CH_StatusC "TRCM ECU: a084 CH status c";
CM_ SG_ 1298 TRCM_a085_PARTY_buttonStatus "TRCM ECU: a085 PARTY button status";
CM_ SG_ 1298 TRCM_a086_VEH_LVBMS_statusHigh "TRCM ECU: a086 VEH LVBMS status high";
CM_ SG_ 1298 TRCM_a086_VEH_LVBMS_statusLow "TRCM ECU: a086 VEH LVBMS status low";
CM_ SG_ 1298 TRCM_a086_VEH_status "TRCM ECU: a086 VEH status";
CM_ SG_ 1298 TRCM_a086_VEH_12VBatteryStatus "TRCM ECU: a086 VEH 12 v battery status";
CM_ SG_ 1298 TRCM_a086_VEH_LVPowerState "TRCM ECU: a086 VEH LV power state";
CM_ SG_ 1298 TRCM_a086_VEH_lightStatus "TRCM ECU: a086 VEH light status";
CM_ SG_ 1298 TRCM_a086_VEH_systemStatus "TRCM ECU: a086 VEH system status";
CM_ SG_ 1298 TRCM_a086_VEH_thermalStatus "TRCM ECU: a086 VEH thermal status";
CM_ SG_ 1298 TRCM_a086_VEH_vehNm "TRCM ECU: a086 VEH veh nm";
CM_ SG_ 1298 TRCM_a087_VEH_temperature "TRCM ECU: a087 VEH temperature";
CM_ SG_ 1298 TRCM_a087_VEH_thermalControl "TRCM ECU: a087 VEH thermal control";
CM_ SG_ 1298 TRCM_a087_VEH_torque "TRCM ECU: a087 VEH torque";
CM_ SG_ 1298 TRCM_a087_VEH_status "TRCM ECU: a087 VEH status";
CM_ SG_ 1298 TRCM_a087_PARTY_torque "TRCM ECU: a087 PARTY torque";
CM_ SG_ 1298 TRCM_a087_PARTY_status "TRCM ECU: a087 PARTY status";
CM_ SG_ 1298 TRCM_a087_PARTY_temperature "TRCM ECU: a087 PARTY temperature";
CM_ SG_ 1298 TRCM_a087_PARTY_thermalControl "TRCM ECU: a087 PARTY thermal control";
CM_ SG_ 1298 TRCM_a087_VEH_motorStatus "TRCM ECU: a087 VEH motor status";
CM_ SG_ 1298 TRCM_a088_VEH_temperature "TRCM ECU: a088 VEH temperature";
CM_ SG_ 1298 TRCM_a088_VEH_thermalControl "TRCM ECU: a088 VEH thermal control";
CM_ SG_ 1298 TRCM_a088_VEH_torque "TRCM ECU: a088 VEH torque";
CM_ SG_ 1298 TRCM_a088_VEH_status "TRCM ECU: a088 VEH status";
CM_ SG_ 1298 TRCM_a088_PARTY_torque "TRCM ECU: a088 PARTY torque";
CM_ SG_ 1298 TRCM_a088_PARTY_status "TRCM ECU: a088 PARTY status";
CM_ SG_ 1298 TRCM_a088_PARTY_temperature "TRCM ECU: a088 PARTY temperature";
CM_ SG_ 1298 TRCM_a088_PARTY_thermalControl "TRCM ECU: a088 PARTY thermal control";
CM_ SG_ 1298 TRCM_a088_VEH_motorStatus "TRCM ECU: a088 VEH motor status";
CM_ SG_ 1298 TRCM_a089_PARTY_party1 "TRCM ECU: a089 PARTY party1";
CM_ SG_ 1298 TRCM_a089_PARTY_status "TRCM ECU: a089 PARTY status";
CM_ SG_ 1298 TRCM_a089_VEH_status "TRCM ECU: a089 VEH status";
CM_ SG_ 1298 TRCM_a089_BDY_party1 "TRCM ECU: a089 BDY party1";
CM_ SG_ 1298 TRCM_a089_BDY_status "TRCM ECU: a089 BDY status";
CM_ SG_ 1298 TRCM_a089_CH_status "TRCM ECU: a089 CH status";
CM_ SG_ 1298 TRCM_a089_CH_party1 "TRCM ECU: a089 CH party1";
CM_ SG_ 1298 TRCM_a089_CH_party3 "TRCM ECU: a089 CH party3";
CM_ SG_ 1298 TRCM_a089_VEH_party1 "TRCM ECU: a089 VEH party1";
CM_ SG_ 1298 TRCM_a089_VEH_party3 "TRCM ECU: a089 VEH party3";
CM_ SG_ 1298 TRCM_a091_VEH_faultsAndExtras "TRCM ECU: a091 VEH faults and extras";
CM_ SG_ 1298 TRCM_a091_VEH_info "TRCM ECU: a091 VEH info";
CM_ SG_ 1298 TRCM_a091_VEH_state "TRCM ECU: a091 VEH state";
CM_ SG_ 1298 TRCM_a092_VEH_restraintStatus "TRCM ECU: a092 VEH restraint status";
CM_ SG_ 1298 TRCM_a092_VEH_switchStatus "TRCM ECU: a092 VEH switch status";
CM_ SG_ 1298 TRCM_a092_VEH_seatStatus2 "TRCM ECU: a092 VEH seat status2";
CM_ SG_ 1298 TRCM_a092_VEH_vehNm "TRCM ECU: a092 VEH veh nm";
CM_ SG_ 1298 TRCM_a093_VEH_restraintStatus "TRCM ECU: a093 VEH restraint status";
CM_ SG_ 1298 TRCM_a093_VEH_switchStatus "TRCM ECU: a093 VEH switch status";
CM_ SG_ 1298 TRCM_a093_VEH_seatStatus2 "TRCM ECU: a093 VEH seat status2";
CM_ SG_ 1298 TRCM_a093_VEH_vehNm "TRCM ECU: a093 VEH veh nm";
CM_ SG_ 1298 TRCM_a094_VEH_sysStatus "TRCM ECU: a094 VEH sys status";
CM_ SG_ 1298 TRCM_a094_PARTY_sysStatus "TRCM ECU: a094 PARTY sys status";
CM_ SG_ 1298 TRCM_a094_CH_sysStatus "TRCM ECU: a094 CH sys status";
CM_ SG_ 1298 TRCM_a095_PT_ptNm "TRCM ECU: a095 PT pt nm";
CM_ SG_ 1298 TRCM_a095_PT_status "TRCM ECU: a095 PT status";
CM_ SG_ 1298 TRCM_a096_VEH_status "TRCM ECU: a096 VEH status";
CM_ SG_ 1298 TRCM_a096_CH_status "TRCM ECU: a096 CH status";
CM_ SG_ 1298 TRCM_a097_VEH_HVStatus "TRCM ECU: a097 VEH HV status";
CM_ SG_ 1298 TRCM_a097_VEH_state "TRCM ECU: a097 VEH state";
CM_ SG_ 1298 TRCM_a098_CH_torque "TRCM ECU: a098 CH torque";
CM_ SG_ 1298 TRCM_a098_VEH_hvStatus "TRCM ECU: a098 VEH hv status";
CM_ SG_ 1298 TRCM_a098_VEH_status "TRCM ECU: a098 VEH status";
CM_ SG_ 1298 TRCM_a098_VEH_thermalControl "TRCM ECU: a098 VEH thermal control";
CM_ SG_ 1298 TRCM_a098_VEH_temperature "TRCM ECU: a098 VEH temperature";
CM_ SG_ 1298 TRCM_a098_VEH_torque "TRCM ECU: a098 VEH torque";
CM_ SG_ 1298 TRCM_a098_PARTY_status "TRCM ECU: a098 PARTY status";
CM_ SG_ 1298 TRCM_a098_PARTY_temperature "TRCM ECU: a098 PARTY temperature";
CM_ SG_ 1298 TRCM_a098_PARTY_thermalControl "TRCM ECU: a098 PARTY thermal control";
CM_ SG_ 1298 TRCM_a098_PARTY_torque "TRCM ECU: a098 PARTY torque";
CM_ SG_ 1298 TRCM_a098_PT_thermalControl "TRCM ECU: a098 PT thermal control";
CM_ SG_ 1298 TRCM_a098_PT_temperature "TRCM ECU: a098 PT temperature";
CM_ SG_ 1298 TRCM_a098_PARTY_motorStatus "TRCM ECU: a098 PARTY motor status";
CM_ SG_ 1298 TRCM_a098_VEH_motorStatus "TRCM ECU: a098 VEH motor status";
CM_ SG_ 1298 TRCM_a099_VEH_oocStatus "TRCM ECU: a099 VEH ooc status";
CM_ SG_ 1298 TRCM_a100_VEH "TRCM ECU: a100 VEH";
CM_ SG_ 1298 TRCM_a100_PARTY "TRCM ECU: a100 PARTY";
CM_ SG_ 1298 TRCM_a100_PT "TRCM ECU: a100 PT";
CM_ SG_ 1298 TRCM_a100_CH "TRCM ECU: a100 CH";
CM_ SG_ 1298 TRCM_a100_OBD "TRCM ECU: a100 OBD";
CM_ SG_ 1298 TRCM_a101_VEH_state "TRCM ECU: a101 VEH state";
CM_ SG_ 1298 TRCM_a101_PARTY_locState "TRCM ECU: a101 PARTY loc state";
CM_ SG_ 1298 TRCM_a101_LIPC_externalWatchdogH "TRCM ECU: a101 LIPC external watchdog heart beat";
CM_ SG_ 1298 TRCM_a101_VEH_locState "TRCM ECU: a101 VEH loc state";
CM_ SG_ 1298 TRCM_a101_BDY_locState "TRCM ECU: a101 BDY loc state";
CM_ SG_ 1298 TRCM_a102_VEH_faultsAndExtras "TRCM ECU: a102 VEH faults and extras";
CM_ SG_ 1298 TRCM_a102_VEH_feedbackStatus "TRCM ECU: a102 VEH feedback status";
CM_ SG_ 1298 TRCM_a102_VEH_sensorStatus "TRCM ECU: a102 VEH sensor status";
CM_ SG_ 1298 TRCM_a102_VEH_rods "TRCM ECU: a102 VEH rods";
CM_ SG_ 1298 TRCM_a103_VEH_hvsNm "TRCM ECU: a103 VEH hvs nm";
CM_ SG_ 1298 TRCM_a103_VEH_vehNm "TRCM ECU: a103 VEH veh nm";
CM_ SG_ 1298 TRCM_a103_VEH_status "TRCM ECU: a103 VEH status";
CM_ SG_ 1298 TRCM_a103_PT_ptNm "TRCM ECU: a103 PT pt nm";
CM_ SG_ 1298 TRCM_a103_PT_status "TRCM ECU: a103 PT status";
CM_ SG_ 1298 TRCM_a103_VEH_evseStatus "TRCM ECU: a103 VEH evse status";
CM_ SG_ 1298 TRCM_a105_VEH_states "TRCM ECU: a105 VEH states";
CM_ SG_ 1298 TRCM_a105_VEH_chNm "TRCM ECU: a105 VEH ch nm";
CM_ SG_ 1298 TRCM_a105_VEH_dampingStates "TRCM ECU: a105 VEH damping states";
CM_ SG_ 1298 TRCM_a106_VEH_dcdcStatus "TRCM ECU: a106 VEH dcdc status";
CM_ SG_ 1298 TRCM_a106_VEH_thermalControl "TRCM ECU: a106 VEH thermal control";
CM_ SG_ 1298 TRCM_a106_VEH_dcdcRailStatus "TRCM ECU: a106 VEH dcdc rail status";
CM_ SG_ 1298 TRCM_a106_CH_dcdcRailStatus "TRCM ECU: a106 CH dcdc rail status";
CM_ SG_ 1298 TRCM_a106_CH_alertMatrix "TRCM ECU: a106 CH alert matrix";
CM_ SG_ 1298 TRCM_a107_VEH_hvsNm "TRCM ECU: a107 VEH hvs nm";
CM_ SG_ 1298 TRCM_a107_VEH_vehNm "TRCM ECU: a107 VEH veh nm";
CM_ SG_ 1298 TRCM_a107_VEH_status "TRCM ECU: a107 VEH status";
CM_ SG_ 1298 TRCM_a107_VEH_thermalStatus "TRCM ECU: a107 VEH thermal status";
CM_ SG_ 1298 TRCM_a107_VEH_bmbMinMax "TRCM ECU: a107 VEH bmb min max";
CM_ SG_ 1298 TRCM_a107_VEH_powerAvailable "TRCM ECU: a107 VEH power available";
CM_ SG_ 1298 TRCM_a107_PT_ptNm "TRCM ECU: a107 PT pt nm";
CM_ SG_ 1298 TRCM_a107_PT_status "TRCM ECU: a107 PT status";
CM_ SG_ 1298 TRCM_a107_PT_thermalStatus "TRCM ECU: a107 PT thermal status";
CM_ SG_ 1298 TRCM_a107_PT_socStatus "TRCM ECU: a107 PT soc status";
CM_ SG_ 1298 TRCM_a107_VEH_socStatus "TRCM ECU: a107 VEH soc status";
CM_ SG_ 1298 TRCM_a107_VEH_packConfig "TRCM ECU: a107 VEH pack config";
CM_ SG_ 1298 TRCM_a107_VEH_energyStatus "TRCM ECU: a107 VEH energy status";
CM_ SG_ 1298 TRCM_a107_VEH_chargeInfo "TRCM ECU: a107 VEH charge info";
CM_ SG_ 1298 TRCM_a108_VEH_hvStatus "TRCM ECU: a108 VEH hv status";
CM_ SG_ 1298 TRCM_a108_VEH_temperature "TRCM ECU: a108 VEH temperature";
CM_ SG_ 1298 TRCM_a108_VEH_thermalControl "TRCM ECU: a108 VEH thermal control";
CM_ SG_ 1298 TRCM_a108_VEH_torque "TRCM ECU: a108 VEH torque";
CM_ SG_ 1298 TRCM_a108_VEH_status "TRCM ECU: a108 VEH status";
CM_ SG_ 1298 TRCM_a108_PARTY_torque "TRCM ECU: a108 PARTY torque";
CM_ SG_ 1298 TRCM_a108_PARTY_status "TRCM ECU: a108 PARTY status";
CM_ SG_ 1298 TRCM_a108_PARTY_temperature "TRCM ECU: a108 PARTY temperature";
CM_ SG_ 1298 TRCM_a108_PARTY_thermalControl "TRCM ECU: a108 PARTY thermal control";
CM_ SG_ 1298 TRCM_a108_PT_temperature "TRCM ECU: a108 PT temperature";
CM_ SG_ 1298 TRCM_a108_PT_thermalControl "TRCM ECU: a108 PT thermal control";
CM_ SG_ 1298 TRCM_a108_PARTY_motorStatus "TRCM ECU: a108 PARTY motor status";
CM_ SG_ 1298 TRCM_a108_VEH_motorStatus "TRCM ECU: a108 VEH motor status";
CM_ SG_ 1298 TRCM_a108_CH_torque "TRCM ECU: a108 CH torque";
CM_ SG_ 1298 TRCM_a110_VEH_carState "TRCM ECU: a110 VEH car state";
CM_ SG_ 1298 TRCM_a110_VEH_carConfig "TRCM ECU: a110 VEH car config";
CM_ SG_ 1298 TRCM_a110_VEH_time "TRCM ECU: a110 VEH time";
CM_ SG_ 1298 TRCM_a110_VEH_updateStatus "TRCM ECU: a110 VEH update status";
CM_ SG_ 1298 TRCM_a110_VEH_vehNm "TRCM ECU: a110 VEH veh nm";
CM_ SG_ 1298 TRCM_a110_VEH_mismatchFault "TRCM ECU: a110 VEH mismatch fault";
CM_ SG_ 1298 TRCM_a110_VEH_vin "TRCM ECU: a110 VEH vin";
CM_ SG_ 1298 TRCM_a110_VEH_bmpDebug "TRCM ECU: a110 VEH bmp debug";
CM_ SG_ 1298 TRCM_a110_VEH_gearControl "TRCM ECU: a110 VEH gear control";
CM_ SG_ 1298 TRCM_a110_VEH_canLogAvailability "TRCM ECU: a110 VEH can log availability";
CM_ SG_ 1298 TRCM_a110_CH_airbagCutoffStatus "TRCM ECU: a110 CH airbag cutoff status";
CM_ SG_ 1298 TRCM_a110_CH_carConfig "TRCM ECU: a110 CH car config";
CM_ SG_ 1298 TRCM_a110_CH_carState "TRCM ECU: a110 CH car state";
CM_ SG_ 1298 TRCM_a110_CH_vin "TRCM ECU: a110 CH vin";
CM_ SG_ 1298 TRCM_a110_CH_chNm "TRCM ECU: a110 CH ch nm";
CM_ SG_ 1298 TRCM_a110_CH_epochTimeGtw "TRCM ECU: a110 CH epoch time gtw";
CM_ SG_ 1298 TRCM_a110_PARTY_carConfig "TRCM ECU: a110 PARTY car config";
CM_ SG_ 1298 TRCM_a111_VEH_internalStatus "TRCM ECU: a111 VEH internal status";
CM_ SG_ 1298 TRCM_a111_VEH_status "TRCM ECU: a111 VEH status";
CM_ SG_ 1298 TRCM_a111_VEH_vehNm "TRCM ECU: a111 VEH veh nm";
CM_ SG_ 1298 TRCM_a111_RIPC_LVPowerState "TRCM ECU: a111 RIPC LV power state";
CM_ SG_ 1298 TRCM_a111_RIPC_epbPrivateState "TRCM ECU: a111 RIPC epb private state";
CM_ SG_ 1298 TRCM_a111_RIPC_railStatus "TRCM ECU: a111 RIPC rail status";
CM_ SG_ 1298 TRCM_a111_RIPC_remoteADC "TRCM ECU: a111 RIPC remote ADC";
CM_ SG_ 1298 TRCM_a111_RIPC_switchStatus "TRCM ECU: a111 RIPC switch status";
CM_ SG_ 1298 TRCM_a111_VEH_LVPowerState "TRCM ECU: a111 VEH LV power state";
CM_ SG_ 1298 TRCM_a111_VEH_seatStatus "TRCM ECU: a111 VEH seat status";
CM_ SG_ 1298 TRCM_a111_PARTY_status "TRCM ECU: a111 PARTY status";
CM_ SG_ 1298 TRCM_a111_CH_status "TRCM ECU: a111 CH status";
CM_ SG_ 1298 TRCM_a112_VEH_internalStatus "TRCM ECU: a112 VEH internal status";
CM_ SG_ 1298 TRCM_a112_VEH_status "TRCM ECU: a112 VEH status";
CM_ SG_ 1298 TRCM_a112_VEH_vehNm "TRCM ECU: a112 VEH veh nm";
CM_ SG_ 1298 TRCM_a112_LIPC_LVPowerState "TRCM ECU: a112 LIPC LV power state";
CM_ SG_ 1298 TRCM_a112_LIPC_epbPrivateState "TRCM ECU: a112 LIPC epb private state";
CM_ SG_ 1298 TRCM_a112_LIPC_railStatus "TRCM ECU: a112 LIPC rail status";
CM_ SG_ 1298 TRCM_a112_LIPC_remoteADC "TRCM ECU: a112 LIPC remote ADC";
CM_ SG_ 1298 TRCM_a112_LIPC_switchStatus "TRCM ECU: a112 LIPC switch status";
CM_ SG_ 1298 TRCM_a112_VEH_LVPowerState "TRCM ECU: a112 VEH LV power state";
CM_ SG_ 1298 TRCM_a112_PARTY_status "TRCM ECU: a112 PARTY status";
CM_ SG_ 1298 TRCM_a112_CH_status "TRCM ECU: a112 CH status";
CM_ SG_ 1298 TRCM_a114_PARTY_status "TRCM ECU: a114 PARTY status";
CM_ SG_ 1298 TRCM_a114_PARTY_wheelSpeeds "TRCM ECU: a114 PARTY wheel speeds";
CM_ SG_ 1298 TRCM_a114_VEH_wheelSpeeds "TRCM ECU: a114 VEH wheel speeds";
CM_ SG_ 1298 TRCM_a114_CH_wheelSpeeds "TRCM ECU: a114 CH wheel speeds";
CM_ SG_ 1298 TRCM_a114_PARTY_party3 "TRCM ECU: a114 PARTY party3";
CM_ SG_ 1298 TRCM_a114_VEH_party3 "TRCM ECU: a114 VEH party3";
CM_ SG_ 1298 TRCM_a114_VEH_status "TRCM ECU: a114 VEH status";
CM_ SG_ 1298 TRCM_a114_PARTY_wheelRotation "TRCM ECU: a114 PARTY wheel rotation";
CM_ SG_ 1298 TRCM_a114_CH_wheelRotation "TRCM ECU: a114 CH wheel rotation";
CM_ SG_ 1298 TRCM_a114_VEH_wheelRotation "TRCM ECU: a114 VEH wheel rotation";
CM_ SG_ 1298 TRCM_a114_PARTY_brakeTorque "TRCM ECU: a114 PARTY brake torque";
CM_ SG_ 1298 TRCM_a114_PARTY_offsets "TRCM ECU: a114 PARTY offsets";
CM_ SG_ 1298 TRCM_a114_BDY_offsets "TRCM ECU: a114 BDY offsets";
CM_ SG_ 1298 TRCM_a114_BDY_party3 "TRCM ECU: a114 BDY party3";
CM_ SG_ 1298 TRCM_a114_BDY_status "TRCM ECU: a114 BDY status";
CM_ SG_ 1298 TRCM_a114_BDY_wheelRotation "TRCM ECU: a114 BDY wheel rotation";
CM_ SG_ 1298 TRCM_a114_BDY_wheelSpeeds "TRCM ECU: a114 BDY wheel speeds";
CM_ SG_ 1298 TRCM_a114_CH_party1 "TRCM ECU: a114 CH party1";
CM_ SG_ 1298 TRCM_a114_CH_party3 "TRCM ECU: a114 CH party3";
CM_ SG_ 1298 TRCM_a114_CH_status "TRCM ECU: a114 CH status";
CM_ SG_ 1298 TRCM_a115_VEH_vehNm "TRCM ECU: a115 VEH veh nm";
CM_ SG_ 1298 TRCM_a115_VEH_authentication "TRCM ECU: a115 VEH authentication";
CM_ SG_ 1298 TRCM_a115_VEH_BLEResetRequest "TRCM ECU: a115 VEH BLE reset request";
CM_ SG_ 1298 TRCM_a115_VEH_requests "TRCM ECU: a115 VEH requests";
CM_ SG_ 1298 TRCM_a115_VEH_requests2 "TRCM ECU: a115 VEH requests2";
CM_ SG_ 1298 TRCM_a115_REM_authentication "TRCM ECU: a115 REM authentication";
CM_ SG_ 1298 TRCM_a115_UI_corianderVehicleCon "TRCM ECU: a115 UI coriander vehicle control";
CM_ SG_ 1298 TRCM_a115_CH_TPMSDisplay "TRCM ECU: a115 CH TPMS display";
CM_ SG_ 1298 TRCM_a116_PARTY_epbmStatus "TRCM ECU: a116 PARTY epbm status";
CM_ SG_ 1298 TRCM_a116_VEH_vehNm "TRCM ECU: a116 VEH veh nm";
CM_ SG_ 1298 TRCM_a116_VEH_hvacRequest "TRCM ECU: a116 VEH hvac request";
CM_ SG_ 1298 TRCM_a116_VEH_hvacStatus "TRCM ECU: a116 VEH hvac status";
CM_ SG_ 1298 TRCM_a116_VEH_LVPowerState "TRCM ECU: a116 VEH LV power state";
CM_ SG_ 1298 TRCM_a116_VEH_lightStatus "TRCM ECU: a116 VEH light status";
CM_ SG_ 1298 TRCM_a116_VEH_seatStatus "TRCM ECU: a116 VEH seat status";
CM_ SG_ 1298 TRCM_a116_VEH_thsStatus "TRCM ECU: a116 VEH ths status";
CM_ SG_ 1298 TRCM_a116_VEH_doorStatus "TRCM ECU: a116 VEH door status";
CM_ SG_ 1298 TRCM_a116_VEH_seatHeatStatus "TRCM ECU: a116 VEH seat heat status";
CM_ SG_ 1298 TRCM_a116_VEH_restraintStatus "TRCM ECU: a116 VEH restraint status";
CM_ SG_ 1298 TRCM_a116_VEH_switchStatus "TRCM ECU: a116 VEH switch status";
CM_ SG_ 1298 TRCM_a116_VEH_logging1Hz "TRCM ECU: a116 VEH logging1 hz";
CM_ SG_ 1298 TRCM_a116_VEH_seatStatus2 "TRCM ECU: a116 VEH seat status2";
CM_ SG_ 1298 TRCM_a116_VEH_status "TRCM ECU: a116 VEH status";
CM_ SG_ 1298 TRCM_a116_VEH_thermalCommand "TRCM ECU: a116 VEH thermal command";
CM_ SG_ 1298 TRCM_a116_VEH_windowStatus "TRCM ECU: a116 VEH window status";
CM_ SG_ 1298 TRCM_a116_PARTY_restraintStatus "TRCM ECU: a116 PARTY restraint status";
CM_ SG_ 1298 TRCM_a116_PARTY_doorStatus "TRCM ECU: a116 PARTY door status";
CM_ SG_ 1298 TRCM_a116_BDY_epbmStatus "TRCM ECU: a116 BDY epbm status";
CM_ SG_ 1298 TRCM_a116_BDY_restraintStatus "TRCM ECU: a116 BDY restraint status";
CM_ SG_ 1298 TRCM_a116_BDY_switchStatus "TRCM ECU: a116 BDY switch status";
CM_ SG_ 1298 TRCM_a117_BDY_epbmStatus "TRCM ECU: a117 BDY epbm status";
CM_ SG_ 1298 TRCM_a117_BDY_restraintStatus "TRCM ECU: a117 BDY restraint status";
CM_ SG_ 1298 TRCM_a117_VEH_prndStatus "TRCM ECU: a117 VEH prnd status";
CM_ SG_ 1298 TRCM_a117_PARTY_epbmStatus "TRCM ECU: a117 PARTY epbm status";
CM_ SG_ 1298 TRCM_a117_VEH_vehNm "TRCM ECU: a117 VEH veh nm";
CM_ SG_ 1298 TRCM_a117_VEH_hvacBlowerFdb "TRCM ECU: a117 VEH hvac blower fdb";
CM_ SG_ 1298 TRCM_a117_VEH_LVPowerState "TRCM ECU: a117 VEH LV power state";
CM_ SG_ 1298 TRCM_a117_VEH_restraintStatus "TRCM ECU: a117 VEH restraint status";
CM_ SG_ 1298 TRCM_a117_VEH_lightStatus "TRCM ECU: a117 VEH light status";
CM_ SG_ 1298 TRCM_a117_VEH_seatStatus "TRCM ECU: a117 VEH seat status";
CM_ SG_ 1298 TRCM_a117_BDY_falconSwitchStatus "TRCM ECU: a117 BDY falcon switch status";
CM_ SG_ 1298 TRCM_a117_VEH_doorStatus "TRCM ECU: a117 VEH door status";
CM_ SG_ 1298 TRCM_a117_VEH_doorStatus2 "TRCM ECU: a117 VEH door status2";
CM_ SG_ 1298 TRCM_a117_VEH_windowStatus "TRCM ECU: a117 VEH window status";
CM_ SG_ 1298 TRCM_a117_VEH_switchStatus "TRCM ECU: a117 VEH switch status";
CM_ SG_ 1298 TRCM_a117_VEH_intrusionSensorSta "TRCM ECU: a117 VEH intrusion sensor status";
CM_ SG_ 1298 TRCM_a117_VEH_liftgateStatus "TRCM ECU: a117 VEH liftgate status";
CM_ SG_ 1298 TRCM_a117_VEH_seatStatus2 "TRCM ECU: a117 VEH seat status2";
CM_ SG_ 1298 TRCM_a117_PARTY_restraintStatus "TRCM ECU: a117 PARTY restraint status";
CM_ SG_ 1298 TRCM_a117_VEH_thermalStatus "TRCM ECU: a117 VEH thermal status";
CM_ SG_ 1298 TRCM_a117_PARTY_doorStatus "TRCM ECU: a117 PARTY door status";
CM_ SG_ 1298 TRCM_a117_VEH_status "TRCM ECU: a117 VEH status";
CM_ SG_ 1298 TRCM_a117_PARTY_prndStatus "TRCM ECU: a117 PARTY prnd status";
CM_ SG_ 1298 TRCM_a117_PARTY_lightingSecondar "TRCM ECU: a117 PARTY lighting secondary";
CM_ SG_ 1298 TRCM_a118_VEH_vehNm "TRCM ECU: a118 VEH veh nm";
CM_ SG_ 1298 TRCM_a118_VEH_lighting "TRCM ECU: a118 VEH lighting";
CM_ SG_ 1298 TRCM_a118_VEH_sensors "TRCM ECU: a118 VEH sensors";
CM_ SG_ 1298 TRCM_a118_VEH_status "TRCM ECU: a118 VEH status";
CM_ SG_ 1298 TRCM_a118_VEH_okToUseHighPwr "TRCM ECU: a118 VEH ok to use high pwr";
CM_ SG_ 1298 TRCM_a118_VEH_LVPowerState "TRCM ECU: a118 VEH LV power state";
CM_ SG_ 1298 TRCM_a118_VEH_coolant "TRCM ECU: a118 VEH coolant";
CM_ SG_ 1298 TRCM_a118_VEH_vehicleStatus "TRCM ECU: a118 VEH vehicle status";
CM_ SG_ 1298 TRCM_a118_VEH_12VBatteryStatus "TRCM ECU: a118 VEH 12 v battery status";
CM_ SG_ 1298 TRCM_a118_VEH_systemStatus "TRCM ECU: a118 VEH system status";
CM_ SG_ 1298 TRCM_a118_PARTY_LVPowerState "TRCM ECU: a118 PARTY LV power state";
CM_ SG_ 1298 TRCM_a118_PARTY_outputPowerStatu "TRCM ECU: a118 PARTY output power status";
CM_ SG_ 1298 TRCM_a118_PARTY_vehicleTime "TRCM ECU: a118 PARTY vehicle time";
CM_ SG_ 1298 TRCM_a118_VEH_thermalCommand "TRCM ECU: a118 VEH thermal command";
CM_ SG_ 1298 TRCM_a118_CH_LVPowerState "TRCM ECU: a118 CH LV power state";
CM_ SG_ 1298 TRCM_a118_PARTY_sensors "TRCM ECU: a118 PARTY sensors";
CM_ SG_ 1298 TRCM_a118_CH_sensors "TRCM ECU: a118 CH sensors";
CM_ SG_ 1298 TRCM_a118_VEH_interNodeResistanc "TRCM ECU: a118 VEH inter node resistance";
CM_ SG_ 1298 TRCM_a118_CH_lighting "TRCM ECU: a118 CH lighting";
CM_ SG_ 1298 TRCM_a118_VEH_lightStatus "TRCM ECU: a118 VEH light status";
CM_ SG_ 1298 TRCM_a118_PARTY_vehNm "TRCM ECU: a118 PARTY veh nm";
CM_ SG_ 1298 TRCM_a118_CH_12VBatteryStatus "TRCM ECU: a118 CH 12 v battery status";
CM_ SG_ 1298 TRCM_a118_CH_LVBMS_statusHigh "TRCM ECU: a118 CH LVBMS status high";
CM_ SG_ 1298 TRCM_a118_CH_alertMatrix "TRCM ECU: a118 CH alert matrix";
CM_ SG_ 1298 TRCM_a118_BDY_outputPowerStatus "TRCM ECU: a118 BDY output power status";
CM_ SG_ 1298 TRCM_a118_BDY_vehicleTime "TRCM ECU: a118 BDY vehicle time";
CM_ SG_ 1298 TRCM_a118_PARTY_AP_vehicleState1 "TRCM ECU: a118 PARTY AP vehicle state1 hz muxed";
CM_ SG_ 1298 TRCM_a118_BDY_AP_vehicleState1Hz "TRCM ECU: a118 BDY AP vehicle state1 hz muxed";
CM_ SG_ 1298 TRCM_a118_PARTY_VCFRONT_cameraCl "TRCM ECU: a118 PARTY VCFRONT camera cleaning status";
CM_ SG_ 1298 TRCM_a119_VEH_steerAngle "TRCM ECU: a119 VEH steer angle";
CM_ SG_ 1298 TRCM_a119_VEH_leftStalk "TRCM ECU: a119 VEH left stalk";
CM_ SG_ 1298 TRCM_a119_VEH_rightStalk "TRCM ECU: a119 VEH right stalk";
CM_ SG_ 1298 TRCM_a119_PARTY_rightStalk "TRCM ECU: a119 PARTY right stalk";
CM_ SG_ 1298 TRCM_a119_CH_steerAngle "TRCM ECU: a119 CH steer angle";
CM_ SG_ 1298 TRCM_a119_PARTY_steerAngle "TRCM ECU: a119 PARTY steer angle";
CM_ SG_ 1298 TRCM_a120_PARTY_chassisCntl "TRCM ECU: a120 PARTY chassis cntl";
CM_ SG_ 1298 TRCM_a120_VEH_systemStatus "TRCM ECU: a120 VEH system status";
CM_ SG_ 1298 TRCM_a120_CH_chassisCntl "TRCM ECU: a120 CH chassis cntl";
CM_ SG_ 1298 TRCM_a120_PARTY_systemStatus "TRCM ECU: a120 PARTY system status";
CM_ SG_ 1298 TRCM_a120_PARTY_torque "TRCM ECU: a120 PARTY torque";
CM_ SG_ 1298 TRCM_a120_VEH_torque "TRCM ECU: a120 VEH torque";
CM_ SG_ 1298 TRCM_a120_PARTY_locStatus "TRCM ECU: a120 PARTY loc status";
CM_ SG_ 1298 TRCM_a120_PARTY_speed "TRCM ECU: a120 PARTY speed";
CM_ SG_ 1298 TRCM_a120_VEH_speed "TRCM ECU: a120 VEH speed";
CM_ SG_ 1298 TRCM_a120_PARTY_status "TRCM ECU: a120 PARTY status";
CM_ SG_ 1298 TRCM_a120_PT_speed "TRCM ECU: a120 PT speed";
CM_ SG_ 1298 TRCM_a120_PT_systemStatus "TRCM ECU: a120 PT system status";
CM_ SG_ 1298 TRCM_a120_PARTY_vehicleEstimates "TRCM ECU: a120 PARTY vehicle estimates";
CM_ SG_ 1298 TRCM_a120_VEH_aggregatedAxleSpee "TRCM ECU: a120 VEH aggregated axle speed";
CM_ SG_ 1298 TRCM_a120_PARTY_aggregatedAxleSp "TRCM ECU: a120 PARTY aggregated axle speed";
CM_ SG_ 1298 TRCM_a120_VEH_systemPower "TRCM ECU: a120 VEH system power";
CM_ SG_ 1298 TRCM_a120_PARTY_autonomyHealth "TRCM ECU: a120 PARTY autonomy health";
CM_ SG_ 1298 TRCM_a120_VEH_autonomyHealth "TRCM ECU: a120 VEH autonomy health";
CM_ SG_ 1298 TRCM_a120_PT_systemPower "TRCM ECU: a120 PT system power";
CM_ SG_ 1298 TRCM_a120_PARTY_stalklessInterfa "TRCM ECU: a120 PARTY stalkless interfaces";
CM_ SG_ 1298 TRCM_a120_CH_speed "TRCM ECU: a120 CH speed";
CM_ SG_ 1298 TRCM_a120_VEH_estimatedBrakeTemp "TRCM ECU: a120 VEH estimated brake temp";
CM_ SG_ 1298 TRCM_a120_PARTY_prndControl "TRCM ECU: a120 PARTY prnd control";
CM_ SG_ 1298 TRCM_a120_PARTY_locStatus2 "TRCM ECU: a120 PARTY loc status2";
CM_ SG_ 1298 TRCM_a120_VEH_chassisCntl "TRCM ECU: a120 VEH chassis cntl";
CM_ SG_ 1298 TRCM_a120_CH_locStatus2 "TRCM ECU: a120 CH loc status2";
CM_ SG_ 1298 TRCM_a120_VEH_locStatus "TRCM ECU: a120 VEH loc status";
CM_ SG_ 1298 TRCM_a120_VEH_locStatus2 "TRCM ECU: a120 VEH loc status2";
CM_ SG_ 1298 TRCM_a120_VEH_prndControl "TRCM ECU: a120 VEH prnd control";
CM_ SG_ 1298 TRCM_a120_VEH_vehicleEstimates "TRCM ECU: a120 VEH vehicle estimates";
CM_ SG_ 1298 TRCM_a120_PARTY_motorStatus "TRCM ECU: a120 PARTY motor status";
CM_ SG_ 1298 TRCM_a120_VEH_motorStatus "TRCM ECU: a120 VEH motor status";
CM_ SG_ 1298 TRCM_a120_BDY_speed "TRCM ECU: a120 BDY speed";
CM_ SG_ 1298 TRCM_a332_groundLossError "TRCM ECU: a332 ground loss error";
CM_ SG_ 1298 TRCM_a332_overcurrentError "TRCM ECU: a332 overcurrent error";
CM_ SG_ 1298 TRCM_a332_overvoltageError "TRCM ECU: a332 overvoltage error";
CM_ SG_ 1298 TRCM_a332_currentMonitorTimer "TRCM ECU: a332 current monitor timer";
CM_ SG_ 1298 TRCM_a333_groundLossError "TRCM ECU: a333 ground loss error";
CM_ SG_ 1298 TRCM_a333_overcurrentError "TRCM ECU: a333 overcurrent error";
CM_ SG_ 1298 TRCM_a333_overvoltageError "TRCM ECU: a333 overvoltage error";
CM_ SG_ 1298 TRCM_a333_currentMonitorTimer "TRCM ECU: a333 current monitor timer";
CM_ SG_ 1298 TRCM_a334_groundLossError "TRCM ECU: a334 ground loss error";
CM_ SG_ 1298 TRCM_a334_overcurrentError "TRCM ECU: a334 overcurrent error";
CM_ SG_ 1298 TRCM_a334_overvoltageError "TRCM ECU: a334 overvoltage error";
CM_ SG_ 1298 TRCM_a334_currentMonitorTimer "TRCM ECU: a334 current monitor timer";
CM_ SG_ 1298 TRCM_a335_groundLossError "TRCM ECU: a335 ground loss error";
CM_ SG_ 1298 TRCM_a335_overcurrentError "TRCM ECU: a335 overcurrent error";
CM_ SG_ 1298 TRCM_a335_overvoltageError "TRCM ECU: a335 overvoltage error";
CM_ SG_ 1298 TRCM_a335_currentMonitorTimer "TRCM ECU: a335 current monitor timer";
CM_ SG_ 1298 TRCM_a336_groundLossError "TRCM ECU: a336 ground loss error";
CM_ SG_ 1298 TRCM_a336_overcurrentError "TRCM ECU: a336 overcurrent error";
CM_ SG_ 1298 TRCM_a336_overvoltageError "TRCM ECU: a336 overvoltage error";
CM_ SG_ 1298 TRCM_a336_currentMonitorTimer "TRCM ECU: a336 current monitor timer";
CM_ SG_ 1298 TRCM_a337_groundLossError "TRCM ECU: a337 ground loss error";
CM_ SG_ 1298 TRCM_a337_overcurrentError "TRCM ECU: a337 overcurrent error";
CM_ SG_ 1298 TRCM_a337_overvoltageError "TRCM ECU: a337 overvoltage error";
CM_ SG_ 1298 TRCM_a337_currentMonitorTimer "TRCM ECU: a337 current monitor timer";
CM_ SG_ 1298 TRCM_a338_groundLossError "TRCM ECU: a338 ground loss error";
CM_ SG_ 1298 TRCM_a338_overcurrentError "TRCM ECU: a338 overcurrent error";
CM_ SG_ 1298 TRCM_a338_overvoltageError "TRCM ECU: a338 overvoltage error";
CM_ SG_ 1298 TRCM_a338_currentMonitorTimer "TRCM ECU: a338 current monitor timer";
CM_ SG_ 1298 TRCM_a340_groundLossError "TRCM ECU: a340 ground loss error";
CM_ SG_ 1298 TRCM_a340_overcurrentError "TRCM ECU: a340 overcurrent error";
CM_ SG_ 1298 TRCM_a340_overvoltageError "TRCM ECU: a340 overvoltage error";
CM_ SG_ 1298 TRCM_a340_currentMonitorTimer "TRCM ECU: a340 current monitor timer";
CM_ SG_ 1298 TRCM_a341_groundLossError "TRCM ECU: a341 ground loss error";
CM_ SG_ 1298 TRCM_a341_overcurrentError "TRCM ECU: a341 overcurrent error";
CM_ SG_ 1298 TRCM_a341_overvoltageError "TRCM ECU: a341 overvoltage error";
CM_ SG_ 1298 TRCM_a341_currentMonitorTimer "TRCM ECU: a341 current monitor timer";
CM_ SG_ 1298 TRCM_a342_groundLossError "TRCM ECU: a342 ground loss error";
CM_ SG_ 1298 TRCM_a342_overcurrentError "TRCM ECU: a342 overcurrent error";
CM_ SG_ 1298 TRCM_a342_overvoltageError "TRCM ECU: a342 overvoltage error";
CM_ SG_ 1298 TRCM_a342_currentMonitorTimer "TRCM ECU: a342 current monitor timer";
CM_ SG_ 1298 TRCM_a343_groundLossError "TRCM ECU: a343 ground loss error";
CM_ SG_ 1298 TRCM_a343_overcurrentError "TRCM ECU: a343 overcurrent error";
CM_ SG_ 1298 TRCM_a343_overvoltageError "TRCM ECU: a343 overvoltage error";
CM_ SG_ 1298 TRCM_a343_currentMonitorTimer "TRCM ECU: a343 current monitor timer";
CM_ SG_ 1298 TRCM_a344_groundLossError "TRCM ECU: a344 ground loss error";
CM_ SG_ 1298 TRCM_a344_overcurrentError "TRCM ECU: a344 overcurrent error";
CM_ SG_ 1298 TRCM_a344_overvoltageError "TRCM ECU: a344 overvoltage error";
CM_ SG_ 1298 TRCM_a344_currentMonitorTimer "TRCM ECU: a344 current monitor timer";
CM_ SG_ 1298 TRCM_a345_groundLossError "TRCM ECU: a345 ground loss error";
CM_ SG_ 1298 TRCM_a345_overcurrentError "TRCM ECU: a345 overcurrent error";
CM_ SG_ 1298 TRCM_a345_overvoltageError "TRCM ECU: a345 overvoltage error";
CM_ SG_ 1298 TRCM_a345_currentMonitorTimer "TRCM ECU: a345 current monitor timer";
CM_ SG_ 1298 TRCM_a346_groundLossError "TRCM ECU: a346 ground loss error";
CM_ SG_ 1298 TRCM_a346_overcurrentError "TRCM ECU: a346 overcurrent error";
CM_ SG_ 1298 TRCM_a346_overvoltageError "TRCM ECU: a346 overvoltage error";
CM_ SG_ 1298 TRCM_a346_currentMonitorTimer "TRCM ECU: a346 current monitor timer";
CM_ SG_ 1298 TRCM_a347_groundLossError "TRCM ECU: a347 ground loss error";
CM_ SG_ 1298 TRCM_a347_overcurrentError "TRCM ECU: a347 overcurrent error";
CM_ SG_ 1298 TRCM_a347_overvoltageError "TRCM ECU: a347 overvoltage error";
CM_ SG_ 1298 TRCM_a347_currentMonitorTimer "TRCM ECU: a347 current monitor timer";
CM_ SG_ 1298 TRCM_a348_groundLossError "TRCM ECU: a348 ground loss error";
CM_ SG_ 1298 TRCM_a348_overcurrentError "TRCM ECU: a348 overcurrent error";
CM_ SG_ 1298 TRCM_a348_overvoltageError "TRCM ECU: a348 overvoltage error";
CM_ SG_ 1298 TRCM_a348_currentMonitorTimer "TRCM ECU: a348 current monitor timer";
CM_ SG_ 1298 TRCM_a349_groundLossError "TRCM ECU: a349 ground loss error";
CM_ SG_ 1298 TRCM_a349_overcurrentError "TRCM ECU: a349 overcurrent error";
CM_ SG_ 1298 TRCM_a349_overvoltageError "TRCM ECU: a349 overvoltage error";
CM_ SG_ 1298 TRCM_a349_currentMonitorTimer "TRCM ECU: a349 current monitor timer";
CM_ SG_ 1298 TRCM_a350_groundLossError "TRCM ECU: a350 ground loss error";
CM_ SG_ 1298 TRCM_a350_overcurrentError "TRCM ECU: a350 overcurrent error";
CM_ SG_ 1298 TRCM_a350_overvoltageError "TRCM ECU: a350 overvoltage error";
CM_ SG_ 1298 TRCM_a350_currentMonitorTimer "TRCM ECU: a350 current monitor timer";
CM_ SG_ 1298 TRCM_a351_groundLossError "TRCM ECU: a351 ground loss error";
CM_ SG_ 1298 TRCM_a351_overcurrentError "TRCM ECU: a351 overcurrent error";
CM_ SG_ 1298 TRCM_a351_overvoltageError "TRCM ECU: a351 overvoltage error";
CM_ SG_ 1298 TRCM_a351_currentMonitorTimer "TRCM ECU: a351 current monitor timer";
CM_ SG_ 1298 TRCM_a352_groundLossError "TRCM ECU: a352 ground loss error";
CM_ SG_ 1298 TRCM_a352_overcurrentError "TRCM ECU: a352 overcurrent error";
CM_ SG_ 1298 TRCM_a352_overvoltageError "TRCM ECU: a352 overvoltage error";
CM_ SG_ 1298 TRCM_a352_currentMonitorTimer "TRCM ECU: a352 current monitor timer";
CM_ SG_ 1298 TRCM_a353_groundLossError "TRCM ECU: a353 ground loss error";
CM_ SG_ 1298 TRCM_a353_overcurrentError "TRCM ECU: a353 overcurrent error";
CM_ SG_ 1298 TRCM_a353_overvoltageError "TRCM ECU: a353 overvoltage error";
CM_ SG_ 1298 TRCM_a353_currentMonitorTimer "TRCM ECU: a353 current monitor timer";
CM_ SG_ 1298 TRCM_a354_groundLossError "TRCM ECU: a354 ground loss error";
CM_ SG_ 1298 TRCM_a354_overcurrentError "TRCM ECU: a354 overcurrent error";
CM_ SG_ 1298 TRCM_a354_overvoltageError "TRCM ECU: a354 overvoltage error";
CM_ SG_ 1298 TRCM_a354_currentMonitorTimer "TRCM ECU: a354 current monitor timer";
CM_ SG_ 1298 TRCM_a355_groundLossError "TRCM ECU: a355 ground loss error";
CM_ SG_ 1298 TRCM_a355_overcurrentError "TRCM ECU: a355 overcurrent error";
CM_ SG_ 1298 TRCM_a355_overvoltageError "TRCM ECU: a355 overvoltage error";
CM_ SG_ 1298 TRCM_a355_currentMonitorTimer "TRCM ECU: a355 current monitor timer";
CM_ SG_ 1298 TRCM_a400_deploymentLoopNumber "TRCM ECU: a400 deployment loop number";
CM_ SG_ 1298 TRCM_a400_resistance "TRCM ECU: a400 resistance";
CM_ SG_ 1298 TRCM_a400_shortToGround "TRCM ECU: a400 short to ground";
CM_ SG_ 1298 TRCM_a400_shortToBattery "TRCM ECU: a400 short to battery";
CM_ SG_ 1298 TRCM_a400_shortToSelf "TRCM ECU: a400 short to self";
CM_ SG_ 1298 TRCM_a400_openCircuit "TRCM ECU: a400 open circuit";
CM_ SG_ 1298 TRCM_a400_crossCoupled "TRCM ECU: a400 cross coupled";
CM_ SG_ 1298 TRCM_a400_resistanceOutOfSpec "TRCM ECU: a400 resistance out of spec";
CM_ SG_ 1298 TRCM_a401_deploymentLoopNumber "TRCM ECU: a401 deployment loop number";
CM_ SG_ 1298 TRCM_a401_resistance "TRCM ECU: a401 resistance";
CM_ SG_ 1298 TRCM_a401_shortToGround "TRCM ECU: a401 short to ground";
CM_ SG_ 1298 TRCM_a401_shortToBattery "TRCM ECU: a401 short to battery";
CM_ SG_ 1298 TRCM_a401_shortToSelf "TRCM ECU: a401 short to self";
CM_ SG_ 1298 TRCM_a401_openCircuit "TRCM ECU: a401 open circuit";
CM_ SG_ 1298 TRCM_a401_crossCoupled "TRCM ECU: a401 cross coupled";
CM_ SG_ 1298 TRCM_a401_resistanceOutOfSpec "TRCM ECU: a401 resistance out of spec";
CM_ SG_ 1298 TRCM_a402_deploymentLoopNumber "TRCM ECU: a402 deployment loop number";
CM_ SG_ 1298 TRCM_a402_resistance "TRCM ECU: a402 resistance";
CM_ SG_ 1298 TRCM_a402_shortToGround "TRCM ECU: a402 short to ground";
CM_ SG_ 1298 TRCM_a402_shortToBattery "TRCM ECU: a402 short to battery";
CM_ SG_ 1298 TRCM_a402_shortToSelf "TRCM ECU: a402 short to self";
CM_ SG_ 1298 TRCM_a402_openCircuit "TRCM ECU: a402 open circuit";
CM_ SG_ 1298 TRCM_a402_crossCoupled "TRCM ECU: a402 cross coupled";
CM_ SG_ 1298 TRCM_a402_resistanceOutOfSpec "TRCM ECU: a402 resistance out of spec";
CM_ SG_ 1298 TRCM_a403_deploymentLoopNumber "TRCM ECU: a403 deployment loop number";
CM_ SG_ 1298 TRCM_a403_resistance "TRCM ECU: a403 resistance";
CM_ SG_ 1298 TRCM_a403_shortToGround "TRCM ECU: a403 short to ground";
CM_ SG_ 1298 TRCM_a403_shortToBattery "TRCM ECU: a403 short to battery";
CM_ SG_ 1298 TRCM_a403_shortToSelf "TRCM ECU: a403 short to self";
CM_ SG_ 1298 TRCM_a403_openCircuit "TRCM ECU: a403 open circuit";
CM_ SG_ 1298 TRCM_a403_crossCoupled "TRCM ECU: a403 cross coupled";
CM_ SG_ 1298 TRCM_a403_resistanceOutOfSpec "TRCM ECU: a403 resistance out of spec";
CM_ SG_ 1298 TRCM_a404_deploymentLoopNumber "TRCM ECU: a404 deployment loop number";
CM_ SG_ 1298 TRCM_a404_resistance "TRCM ECU: a404 resistance";
CM_ SG_ 1298 TRCM_a404_shortToGround "TRCM ECU: a404 short to ground";
CM_ SG_ 1298 TRCM_a404_shortToBattery "TRCM ECU: a404 short to battery";
CM_ SG_ 1298 TRCM_a404_shortToSelf "TRCM ECU: a404 short to self";
CM_ SG_ 1298 TRCM_a404_openCircuit "TRCM ECU: a404 open circuit";
CM_ SG_ 1298 TRCM_a404_crossCoupled "TRCM ECU: a404 cross coupled";
CM_ SG_ 1298 TRCM_a404_resistanceOutOfSpec "TRCM ECU: a404 resistance out of spec";
CM_ SG_ 1298 TRCM_a405_deploymentLoopNumber "TRCM ECU: a405 deployment loop number";
CM_ SG_ 1298 TRCM_a405_resistance "TRCM ECU: a405 resistance";
CM_ SG_ 1298 TRCM_a405_shortToGround "TRCM ECU: a405 short to ground";
CM_ SG_ 1298 TRCM_a405_shortToBattery "TRCM ECU: a405 short to battery";
CM_ SG_ 1298 TRCM_a405_shortToSelf "TRCM ECU: a405 short to self";
CM_ SG_ 1298 TRCM_a405_openCircuit "TRCM ECU: a405 open circuit";
CM_ SG_ 1298 TRCM_a405_crossCoupled "TRCM ECU: a405 cross coupled";
CM_ SG_ 1298 TRCM_a405_resistanceOutOfSpec "TRCM ECU: a405 resistance out of spec";
CM_ SG_ 1298 TRCM_a406_deploymentLoopNumber "TRCM ECU: a406 deployment loop number";
CM_ SG_ 1298 TRCM_a406_resistance "TRCM ECU: a406 resistance";
CM_ SG_ 1298 TRCM_a406_shortToGround "TRCM ECU: a406 short to ground";
CM_ SG_ 1298 TRCM_a406_shortToBattery "TRCM ECU: a406 short to battery";
CM_ SG_ 1298 TRCM_a406_shortToSelf "TRCM ECU: a406 short to self";
CM_ SG_ 1298 TRCM_a406_openCircuit "TRCM ECU: a406 open circuit";
CM_ SG_ 1298 TRCM_a406_crossCoupled "TRCM ECU: a406 cross coupled";
CM_ SG_ 1298 TRCM_a406_resistanceOutOfSpec "TRCM ECU: a406 resistance out of spec";
CM_ SG_ 1298 TRCM_a408_deploymentLoopNumber "TRCM ECU: a408 deployment loop number";
CM_ SG_ 1298 TRCM_a408_resistance "TRCM ECU: a408 resistance";
CM_ SG_ 1298 TRCM_a408_shortToGround "TRCM ECU: a408 short to ground";
CM_ SG_ 1298 TRCM_a408_shortToBattery "TRCM ECU: a408 short to battery";
CM_ SG_ 1298 TRCM_a408_shortToSelf "TRCM ECU: a408 short to self";
CM_ SG_ 1298 TRCM_a408_openCircuit "TRCM ECU: a408 open circuit";
CM_ SG_ 1298 TRCM_a408_crossCoupled "TRCM ECU: a408 cross coupled";
CM_ SG_ 1298 TRCM_a408_resistanceOutOfSpec "TRCM ECU: a408 resistance out of spec";
CM_ SG_ 1298 TRCM_a409_deploymentLoopNumber "TRCM ECU: a409 deployment loop number";
CM_ SG_ 1298 TRCM_a409_resistance "TRCM ECU: a409 resistance";
CM_ SG_ 1298 TRCM_a409_shortToGround "TRCM ECU: a409 short to ground";
CM_ SG_ 1298 TRCM_a409_shortToBattery "TRCM ECU: a409 short to battery";
CM_ SG_ 1298 TRCM_a409_shortToSelf "TRCM ECU: a409 short to self";
CM_ SG_ 1298 TRCM_a409_openCircuit "TRCM ECU: a409 open circuit";
CM_ SG_ 1298 TRCM_a409_crossCoupled "TRCM ECU: a409 cross coupled";
CM_ SG_ 1298 TRCM_a409_resistanceOutOfSpec "TRCM ECU: a409 resistance out of spec";
CM_ SG_ 1298 TRCM_a410_deploymentLoopNumber "TRCM ECU: a410 deployment loop number";
CM_ SG_ 1298 TRCM_a410_resistance "TRCM ECU: a410 resistance";
CM_ SG_ 1298 TRCM_a410_shortToGround "TRCM ECU: a410 short to ground";
CM_ SG_ 1298 TRCM_a410_shortToBattery "TRCM ECU: a410 short to battery";
CM_ SG_ 1298 TRCM_a410_shortToSelf "TRCM ECU: a410 short to self";
CM_ SG_ 1298 TRCM_a410_openCircuit "TRCM ECU: a410 open circuit";
CM_ SG_ 1298 TRCM_a410_crossCoupled "TRCM ECU: a410 cross coupled";
CM_ SG_ 1298 TRCM_a410_resistanceOutOfSpec "TRCM ECU: a410 resistance out of spec";
CM_ SG_ 1298 TRCM_a411_deploymentLoopNumber "TRCM ECU: a411 deployment loop number";
CM_ SG_ 1298 TRCM_a411_resistance "TRCM ECU: a411 resistance";
CM_ SG_ 1298 TRCM_a411_shortToGround "TRCM ECU: a411 short to ground";
CM_ SG_ 1298 TRCM_a411_shortToBattery "TRCM ECU: a411 short to battery";
CM_ SG_ 1298 TRCM_a411_shortToSelf "TRCM ECU: a411 short to self";
CM_ SG_ 1298 TRCM_a411_openCircuit "TRCM ECU: a411 open circuit";
CM_ SG_ 1298 TRCM_a411_crossCoupled "TRCM ECU: a411 cross coupled";
CM_ SG_ 1298 TRCM_a411_resistanceOutOfSpec "TRCM ECU: a411 resistance out of spec";
CM_ SG_ 1298 TRCM_a412_deploymentLoopNumber "TRCM ECU: a412 deployment loop number";
CM_ SG_ 1298 TRCM_a412_resistance "TRCM ECU: a412 resistance";
CM_ SG_ 1298 TRCM_a412_shortToGround "TRCM ECU: a412 short to ground";
CM_ SG_ 1298 TRCM_a412_shortToBattery "TRCM ECU: a412 short to battery";
CM_ SG_ 1298 TRCM_a412_shortToSelf "TRCM ECU: a412 short to self";
CM_ SG_ 1298 TRCM_a412_openCircuit "TRCM ECU: a412 open circuit";
CM_ SG_ 1298 TRCM_a412_crossCoupled "TRCM ECU: a412 cross coupled";
CM_ SG_ 1298 TRCM_a412_resistanceOutOfSpec "TRCM ECU: a412 resistance out of spec";
CM_ SG_ 1298 TRCM_a413_deploymentLoopNumber "TRCM ECU: a413 deployment loop number";
CM_ SG_ 1298 TRCM_a413_resistance "TRCM ECU: a413 resistance";
CM_ SG_ 1298 TRCM_a413_shortToGround "TRCM ECU: a413 short to ground";
CM_ SG_ 1298 TRCM_a413_shortToBattery "TRCM ECU: a413 short to battery";
CM_ SG_ 1298 TRCM_a413_shortToSelf "TRCM ECU: a413 short to self";
CM_ SG_ 1298 TRCM_a413_openCircuit "TRCM ECU: a413 open circuit";
CM_ SG_ 1298 TRCM_a413_crossCoupled "TRCM ECU: a413 cross coupled";
CM_ SG_ 1298 TRCM_a413_resistanceOutOfSpec "TRCM ECU: a413 resistance out of spec";
CM_ SG_ 1298 TRCM_a414_deploymentLoopNumber "TRCM ECU: a414 deployment loop number";
CM_ SG_ 1298 TRCM_a414_resistance "TRCM ECU: a414 resistance";
CM_ SG_ 1298 TRCM_a414_shortToGround "TRCM ECU: a414 short to ground";
CM_ SG_ 1298 TRCM_a414_shortToBattery "TRCM ECU: a414 short to battery";
CM_ SG_ 1298 TRCM_a414_shortToSelf "TRCM ECU: a414 short to self";
CM_ SG_ 1298 TRCM_a414_openCircuit "TRCM ECU: a414 open circuit";
CM_ SG_ 1298 TRCM_a414_crossCoupled "TRCM ECU: a414 cross coupled";
CM_ SG_ 1298 TRCM_a414_resistanceOutOfSpec "TRCM ECU: a414 resistance out of spec";
CM_ SG_ 1298 TRCM_a415_deploymentLoopNumber "TRCM ECU: a415 deployment loop number";
CM_ SG_ 1298 TRCM_a415_resistance "TRCM ECU: a415 resistance";
CM_ SG_ 1298 TRCM_a415_shortToGround "TRCM ECU: a415 short to ground";
CM_ SG_ 1298 TRCM_a415_shortToBattery "TRCM ECU: a415 short to battery";
CM_ SG_ 1298 TRCM_a415_shortToSelf "TRCM ECU: a415 short to self";
CM_ SG_ 1298 TRCM_a415_openCircuit "TRCM ECU: a415 open circuit";
CM_ SG_ 1298 TRCM_a415_crossCoupled "TRCM ECU: a415 cross coupled";
CM_ SG_ 1298 TRCM_a415_resistanceOutOfSpec "TRCM ECU: a415 resistance out of spec";
CM_ SG_ 1298 TRCM_a416_deploymentLoopNumber "TRCM ECU: a416 deployment loop number";
CM_ SG_ 1298 TRCM_a416_resistance "TRCM ECU: a416 resistance";
CM_ SG_ 1298 TRCM_a416_shortToGround "TRCM ECU: a416 short to ground";
CM_ SG_ 1298 TRCM_a416_shortToBattery "TRCM ECU: a416 short to battery";
CM_ SG_ 1298 TRCM_a416_shortToSelf "TRCM ECU: a416 short to self";
CM_ SG_ 1298 TRCM_a416_openCircuit "TRCM ECU: a416 open circuit";
CM_ SG_ 1298 TRCM_a416_crossCoupled "TRCM ECU: a416 cross coupled";
CM_ SG_ 1298 TRCM_a416_resistanceOutOfSpec "TRCM ECU: a416 resistance out of spec";
CM_ SG_ 1298 TRCM_a417_deploymentLoopNumber "TRCM ECU: a417 deployment loop number";
CM_ SG_ 1298 TRCM_a417_resistance "TRCM ECU: a417 resistance";
CM_ SG_ 1298 TRCM_a417_shortToGround "TRCM ECU: a417 short to ground";
CM_ SG_ 1298 TRCM_a417_shortToBattery "TRCM ECU: a417 short to battery";
CM_ SG_ 1298 TRCM_a417_shortToSelf "TRCM ECU: a417 short to self";
CM_ SG_ 1298 TRCM_a417_openCircuit "TRCM ECU: a417 open circuit";
CM_ SG_ 1298 TRCM_a417_crossCoupled "TRCM ECU: a417 cross coupled";
CM_ SG_ 1298 TRCM_a417_resistanceOutOfSpec "TRCM ECU: a417 resistance out of spec";
CM_ SG_ 1298 TRCM_a418_deploymentLoopNumber "TRCM ECU: a418 deployment loop number";
CM_ SG_ 1298 TRCM_a418_resistance "TRCM ECU: a418 resistance";
CM_ SG_ 1298 TRCM_a418_shortToGround "TRCM ECU: a418 short to ground";
CM_ SG_ 1298 TRCM_a418_shortToBattery "TRCM ECU: a418 short to battery";
CM_ SG_ 1298 TRCM_a418_shortToSelf "TRCM ECU: a418 short to self";
CM_ SG_ 1298 TRCM_a418_openCircuit "TRCM ECU: a418 open circuit";
CM_ SG_ 1298 TRCM_a418_crossCoupled "TRCM ECU: a418 cross coupled";
CM_ SG_ 1298 TRCM_a418_resistanceOutOfSpec "TRCM ECU: a418 resistance out of spec";
CM_ SG_ 1298 TRCM_a419_deploymentLoopNumber "TRCM ECU: a419 deployment loop number";
CM_ SG_ 1298 TRCM_a419_resistance "TRCM ECU: a419 resistance";
CM_ SG_ 1298 TRCM_a419_shortToGround "TRCM ECU: a419 short to ground";
CM_ SG_ 1298 TRCM_a419_shortToBattery "TRCM ECU: a419 short to battery";
CM_ SG_ 1298 TRCM_a419_shortToSelf "TRCM ECU: a419 short to self";
CM_ SG_ 1298 TRCM_a419_openCircuit "TRCM ECU: a419 open circuit";
CM_ SG_ 1298 TRCM_a419_crossCoupled "TRCM ECU: a419 cross coupled";
CM_ SG_ 1298 TRCM_a419_resistanceOutOfSpec "TRCM ECU: a419 resistance out of spec";
CM_ SG_ 1298 TRCM_a420_deploymentLoopNumber "TRCM ECU: a420 deployment loop number";
CM_ SG_ 1298 TRCM_a420_resistance "TRCM ECU: a420 resistance";
CM_ SG_ 1298 TRCM_a420_shortToGround "TRCM ECU: a420 short to ground";
CM_ SG_ 1298 TRCM_a420_shortToBattery "TRCM ECU: a420 short to battery";
CM_ SG_ 1298 TRCM_a420_shortToSelf "TRCM ECU: a420 short to self";
CM_ SG_ 1298 TRCM_a420_openCircuit "TRCM ECU: a420 open circuit";
CM_ SG_ 1298 TRCM_a420_crossCoupled "TRCM ECU: a420 cross coupled";
CM_ SG_ 1298 TRCM_a420_resistanceOutOfSpec "TRCM ECU: a420 resistance out of spec";
CM_ SG_ 1298 TRCM_a421_deploymentLoopNumber "TRCM ECU: a421 deployment loop number";
CM_ SG_ 1298 TRCM_a421_resistance "TRCM ECU: a421 resistance";
CM_ SG_ 1298 TRCM_a421_shortToGround "TRCM ECU: a421 short to ground";
CM_ SG_ 1298 TRCM_a421_shortToBattery "TRCM ECU: a421 short to battery";
CM_ SG_ 1298 TRCM_a421_shortToSelf "TRCM ECU: a421 short to self";
CM_ SG_ 1298 TRCM_a421_openCircuit "TRCM ECU: a421 open circuit";
CM_ SG_ 1298 TRCM_a421_crossCoupled "TRCM ECU: a421 cross coupled";
CM_ SG_ 1298 TRCM_a421_resistanceOutOfSpec "TRCM ECU: a421 resistance out of spec";
CM_ SG_ 1298 TRCM_a422_deploymentLoopNumber "TRCM ECU: a422 deployment loop number";
CM_ SG_ 1298 TRCM_a422_resistance "TRCM ECU: a422 resistance";
CM_ SG_ 1298 TRCM_a422_shortToGround "TRCM ECU: a422 short to ground";
CM_ SG_ 1298 TRCM_a422_shortToBattery "TRCM ECU: a422 short to battery";
CM_ SG_ 1298 TRCM_a422_shortToSelf "TRCM ECU: a422 short to self";
CM_ SG_ 1298 TRCM_a422_openCircuit "TRCM ECU: a422 open circuit";
CM_ SG_ 1298 TRCM_a422_crossCoupled "TRCM ECU: a422 cross coupled";
CM_ SG_ 1298 TRCM_a422_resistanceOutOfSpec "TRCM ECU: a422 resistance out of spec";
CM_ SG_ 1298 TRCM_a423_deploymentLoopNumber "TRCM ECU: a423 deployment loop number";
CM_ SG_ 1298 TRCM_a423_resistance "TRCM ECU: a423 resistance";
CM_ SG_ 1298 TRCM_a423_shortToGround "TRCM ECU: a423 short to ground";
CM_ SG_ 1298 TRCM_a423_shortToBattery "TRCM ECU: a423 short to battery";
CM_ SG_ 1298 TRCM_a423_shortToSelf "TRCM ECU: a423 short to self";
CM_ SG_ 1298 TRCM_a423_openCircuit "TRCM ECU: a423 open circuit";
CM_ SG_ 1298 TRCM_a423_crossCoupled "TRCM ECU: a423 cross coupled";
CM_ SG_ 1298 TRCM_a423_resistanceOutOfSpec "TRCM ECU: a423 resistance out of spec";
BA_DEF_ BO_ "GenMsgCycleTime" INT 0 3600000;
BA_DEF_ BO_ "GenMsgSendType" ENUM "Cyclic","NotUsed","NotUsed","NotUsed","NotUsed","NotUsed","NotUsed","IfActive","NoMsgSendType","NotUsed";
BA_DEF_ BO_ "VFrameFormat" ENUM "StandardCAN","ExtendedCAN","reserved","J1939PG","reserved","reserved","reserved","reserved","reserved","reserved","reserved","reserved","reserved","reserved","StandardCAN_FD","ExtendedCAN_FD";
BA_DEF_ BO_ "CANFD_BRS" ENUM "0","1";
BA_DEF_ SG_ "SystemSignalLongSymbol" STRING;
BA_DEF_ SG_ "Confidence" ENUM "layout-only","plausible","validated";
BA_DEF_DEF_ "GenMsgCycleTime" 0;
BA_DEF_DEF_ "GenMsgSendType" "NoMsgSendType";
BA_DEF_DEF_ "VFrameFormat" "StandardCAN";
BA_DEF_DEF_ "CANFD_BRS" "1";
BA_DEF_DEF_ "SystemSignalLongSymbol" "";
BA_DEF_DEF_ "Confidence" "layout-only";
BA_ "SystemSignalLongSymbol" SG_ 852 TAS_a066_undefinedInstructionAbo "TAS_a066_undefinedInstructionAbort";
BA_ "SystemSignalLongSymbol" SG_ 852 TAS_a150_accelAvgImplausible_FL_ "TAS_a150_accelAvgImplausible_FL_X";
BA_ "SystemSignalLongSymbol" SG_ 852 TAS_a151_accelAvgImplausible_FL_ "TAS_a151_accelAvgImplausible_FL_Y";
BA_ "SystemSignalLongSymbol" SG_ 852 TAS_a152_accelAvgImplausible_FL_ "TAS_a152_accelAvgImplausible_FL_Z";
BA_ "SystemSignalLongSymbol" SG_ 852 TAS_a153_accelAvgImplausible_FR_ "TAS_a153_accelAvgImplausible_FR_X";
BA_ "SystemSignalLongSymbol" SG_ 852 TAS_a154_accelAvgImplausible_FR_ "TAS_a154_accelAvgImplausible_FR_Y";
BA_ "SystemSignalLongSymbol" SG_ 852 TAS_a155_accelAvgImplausible_FR_ "TAS_a155_accelAvgImplausible_FR_Z";
BA_ "SystemSignalLongSymbol" SG_ 852 TAS_a156_accelAvgImplausible_RL_ "TAS_a156_accelAvgImplausible_RL_X";
BA_ "SystemSignalLongSymbol" SG_ 852 TAS_a157_accelAvgImplausible_RL_ "TAS_a157_accelAvgImplausible_RL_Y";
BA_ "SystemSignalLongSymbol" SG_ 852 TAS_a158_accelAvgImplausible_RL_ "TAS_a158_accelAvgImplausible_RL_Z";
BA_ "SystemSignalLongSymbol" SG_ 852 TAS_a159_accelAvgImplausible_RR_ "TAS_a159_accelAvgImplausible_RR_X";
BA_ "SystemSignalLongSymbol" SG_ 852 TAS_a160_accelAvgImplausible_RR_ "TAS_a160_accelAvgImplausible_RR_Y";
BA_ "SystemSignalLongSymbol" SG_ 852 TAS_a161_accelAvgImplausible_RR_ "TAS_a161_accelAvgImplausible_RR_Z";
BA_ "SystemSignalLongSymbol" SG_ 852 TAS_a192_rideHeightObserverDiver "TAS_a192_rideHeightObserverDivergence";
BA_ "SystemSignalLongSymbol" SG_ 852 TAS_a197_invalidAdaptiveModeRequ "TAS_a197_invalidAdaptiveModeRequested";
BA_ "SystemSignalLongSymbol" SG_ 852 TAS_a198_a2bFrontAxleExtendedDis "TAS_a198_a2bFrontAxleExtendedDiscoveryTime";
BA_ "SystemSignalLongSymbol" SG_ 852 TAS_a199_a2bRearAxleExtendedDisc "TAS_a199_a2bRearAxleExtendedDiscoveryTime";
BA_ "SystemSignalLongSymbol" SG_ 852 TAS_a343_damperValveControlCompF "TAS_a343_damperValveControlCompFL";
BA_ "SystemSignalLongSymbol" SG_ 852 TAS_a344_damperValveControlRbndF "TAS_a344_damperValveControlRbndFL";
BA_ "SystemSignalLongSymbol" SG_ 852 TAS_a345_damperValveControlCompF "TAS_a345_damperValveControlCompFR";
BA_ "SystemSignalLongSymbol" SG_ 852 TAS_a346_damperValveControlRbndF "TAS_a346_damperValveControlRbndFR";
BA_ "SystemSignalLongSymbol" SG_ 852 TAS_a347_damperValveControlCompR "TAS_a347_damperValveControlCompRL";
BA_ "SystemSignalLongSymbol" SG_ 852 TAS_a348_damperValveControlRbndR "TAS_a348_damperValveControlRbndRL";
BA_ "SystemSignalLongSymbol" SG_ 852 TAS_a349_damperValveControlCompR "TAS_a349_damperValveControlCompRR";
BA_ "SystemSignalLongSymbol" SG_ 852 TAS_a350_damperValveControlRbndR "TAS_a350_damperValveControlRbndRR";
BA_ "Confidence" SG_ 523 TAS_rawHeightFL 1;
BA_ "Confidence" SG_ 523 TAS_staticHeightEstimateFL 1;
BA_ "Confidence" SG_ 523 TAS_componentPressureFL 1;
BA_ "Confidence" SG_ 523 TAS_rawHeightFR 1;
BA_ "Confidence" SG_ 523 TAS_staticHeightEstimateFR 1;
BA_ "Confidence" SG_ 523 TAS_componentPressureFR 1;
BA_ "Confidence" SG_ 523 TAS_rawHeightRL 1;
BA_ "Confidence" SG_ 523 TAS_staticHeightEstimateRL 1;
BA_ "Confidence" SG_ 523 TAS_componentPressureRL 1;
BA_ "Confidence" SG_ 523 TAS_rawHeightRR 1;
BA_ "Confidence" SG_ 523 TAS_staticHeightEstimateRR 1;
BA_ "Confidence" SG_ 523 TAS_componentPressureRR 1;
BA_ "Confidence" SG_ 1398 TAS_endstopState 1;
BA_ "Confidence" SG_ 1398 TAS_continuousControlState 1;
BA_ "Confidence" SG_ 1398 TAS_activeTireTune 1;
BA_ "Confidence" SG_ 1398 TAS_roughnessRaiseReason 1;
BA_ "Confidence" SG_ 1398 TAS_frontMetricDrivesRear 1;
BA_ "Confidence" SG_ 1398 TAS_roadCondition 1;
BA_ "Confidence" SG_ 1398 TAS_bellyProtect 1;
BA_ "Confidence" SG_ 1398 TAS_frontMetricDrivesFront 1;
BA_ "Confidence" SG_ 1398 TAS_speedBumpAxleFront 1;
BA_ "Confidence" SG_ 1398 TAS_speedBumpAxleRear 1;
BA_ "Confidence" SG_ 1398 TAS_holeProtectFL 1;
BA_ "Confidence" SG_ 1398 TAS_holeProtectFR 1;
BA_ "Confidence" SG_ 1398 TAS_holeProtectRL 1;
BA_ "Confidence" SG_ 1398 TAS_holeProtectRR 1;
BA_ "Confidence" SG_ 1398 TAS_stepProtectFL 1;
BA_ "Confidence" SG_ 1398 TAS_stepProtectFR 1;
BA_ "Confidence" SG_ 1398 TAS_stepProtectRL 1;
BA_ "Confidence" SG_ 1398 TAS_stepProtectRR 1;
BA_ "Confidence" SG_ 1398 TAS_FDUTorqueCorruptionScale 1;
BA_ "Confidence" SG_ 1398 TAS_sprungMassEstimate 1;
BA_ "Confidence" SG_ 1357 TAS_infoBuildType 1;
BA_ "Confidence" SG_ 525 TAS_levelingState 1;
BA_ "Confidence" SG_ 525 TAS_levelingItem 1;
BA_ "Confidence" SG_ 525 TAS_pressureGallery 1;
BA_ "Confidence" SG_ 525 TAS_pressureReservoir 1;
BA_ "Confidence" SG_ 525 TAS_runMode 1;
BA_ "Confidence" SG_ 525 TAS_filterMode 1;
BA_ "Confidence" SG_ 525 TAS_compressorRun 1;
BA_ "Confidence" SG_ 525 TAS_twistDetected 1;
BA_ "Confidence" SG_ 525 TAS_leanDetected 1;
BA_ "Confidence" SG_ 525 TAS_limpHomeMode 1;
BA_ "Confidence" SG_ 525 TAS_targetLevel 1;
BA_ "Confidence" SG_ 525 TAS_currentLevel 1;
BA_ "Confidence" SG_ 525 TAS_jackMode 1;
BA_ "Confidence" SG_ 409 TAS_adaptiveActivityFL_C 1;
BA_ "Confidence" SG_ 409 TAS_adaptiveActivityFL_R 1;
BA_ "Confidence" SG_ 409 TAS_adaptiveActivityFR_C 1;
BA_ "Confidence" SG_ 409 TAS_adaptiveActivityFR_R 1;
BA_ "Confidence" SG_ 409 TAS_adaptiveActivityRL_C 1;
BA_ "Confidence" SG_ 409 TAS_adaptiveActivityRL_R 1;
BA_ "Confidence" SG_ 409 TAS_adaptiveActivityRR_C 1;
BA_ "Confidence" SG_ 409 TAS_adaptiveActivityRR_R 1;
BA_ "Confidence" SG_ 409 TAS_uiHeightFL 1;
BA_ "Confidence" SG_ 409 TAS_uiHeightFR 1;
BA_ "Confidence" SG_ 409 TAS_uiHeightRL 1;
BA_ "Confidence" SG_ 409 TAS_uiHeightRR 1;
BA_ "Confidence" SG_ 410 TAS_bodyAccelFL 1;
BA_ "Confidence" SG_ 410 TAS_bodyAccelFR 1;
BA_ "Confidence" SG_ 410 TAS_bodyAccelRL 1;
BA_ "Confidence" SG_ 410 TAS_bodyAccelRR 1;
BA_ "Confidence" SG_ 538 TAS_adaptiveRideModeOverride 1;
BA_ "Confidence" SG_ 538 TAS_launchModeState 1;
BA_ "Confidence" SG_ 538 TAS_restrictLevelingShowroom 1;
BA_ "Confidence" SG_ 1415 TCU2_tc10Version 1;
BA_ "Confidence" SG_ 1412 TCU2_cpuTemp 1;
BA_ "Confidence" SG_ 1412 TCU2_cpuUsage 1;
BA_ "Confidence" SG_ 1412 TCU2_mdmCoreTemperature 1;
BA_ "Confidence" SG_ 1412 TCU2_availableMemory 1;
BA_ "Confidence" SG_ 1412 TCU2_pwm 1;
BA_ "Confidence" SG_ 1412 TCU2_pwmcap 1;
BA_ "Confidence" SG_ 1412 TCU2_totalResumes 1;
BA_ "Confidence" SG_ 1412 TCU2_mdmUplinkQueueSize 1;
BA_ "Confidence" SG_ 1412 TCU2_mdmRSRP 1;
BA_ "Confidence" SG_ 1412 TCU2_mdmSINR 1;
BA_ "Confidence" SG_ 1412 TCU2_mdmUplinkAllowedRate 1;
BA_ "Confidence" SG_ 1412 TCU2_mdmUplinkAvgRate 1;
BA_ "Confidence" SG_ 1412 TCU2_mdmIMSStatus 1;
BA_ "Confidence" SG_ 1412 TCU2_mdmBusyActive 1;
BA_ "Confidence" SG_ 1412 TCU2_modemUptime 1;
BA_ "Confidence" SG_ 1412 TCU2_mdmDataRat 1;
BA_ "Confidence" SG_ 1412 TCU2_mdmDataCallStatus 1;
BA_ "Confidence" SG_ 1412 TCU2_mdmNSAAvailable 1;
BA_ "Confidence" SG_ 1412 TCU2_mdmTxKiloBytes 1;
BA_ "Confidence" SG_ 1412 TCU2_mdmDataCallTermReason 1;
BA_ "Confidence" SG_ 1412 TCU2_mdmDataCallTermCode 1;
BA_ "Confidence" SG_ 1412 TCU2_cellularSMState 1;
BA_ "Confidence" SG_ 1412 TCU2_tcuSMState 1;
BA_ "Confidence" SG_ 1412 TCU2_checkInternetFailCount 1;
BA_ "Confidence" SG_ 1412 TCU2_mdmBand 1;
BA_ "Confidence" SG_ 1412 TCU2_wakeSource 1;
BA_ "Confidence" SG_ 1159 TCU_tc10Version 1;
BA_ "Confidence" SG_ 1155 TCU_cpuTemp 1;
BA_ "Confidence" SG_ 1155 TCU_cpuUsage 1;
BA_ "Confidence" SG_ 1155 TCU_mdmCoreTemperature 1;
BA_ "Confidence" SG_ 1155 TCU_availableMemory 1;
BA_ "Confidence" SG_ 1155 TCU_pwm 1;
BA_ "Confidence" SG_ 1155 TCU_pwmcap 1;
BA_ "Confidence" SG_ 1155 TCU_totalResumes 1;
BA_ "Confidence" SG_ 1155 TCU_mdmUplinkQueueSize 1;
BA_ "Confidence" SG_ 1155 TCU_mdmRSRP 1;
BA_ "Confidence" SG_ 1155 TCU_mdmSINR 1;
BA_ "Confidence" SG_ 1155 TCU_mdmUplinkAllowedRate 1;
BA_ "Confidence" SG_ 1155 TCU_mdmUplinkAvgRate 1;
BA_ "Confidence" SG_ 1155 TCU_mdmIMSStatus 1;
BA_ "Confidence" SG_ 1155 TCU_mdmBusyActive 1;
BA_ "Confidence" SG_ 1155 TCU_modemUptime 1;
BA_ "Confidence" SG_ 1155 TCU_mdmDataRat 1;
BA_ "Confidence" SG_ 1155 TCU_mdmDataCallStatus 1;
BA_ "Confidence" SG_ 1155 TCU_mdmNSAAvailable 1;
BA_ "Confidence" SG_ 1155 TCU_mdmTxKiloBytes 1;
BA_ "Confidence" SG_ 1155 TCU_mdmDataCallTermReason 1;
BA_ "Confidence" SG_ 1155 TCU_mdmDataCallTermCode 1;
BA_ "Confidence" SG_ 1155 TCU_cellularSMState 1;
BA_ "Confidence" SG_ 1155 TCU_tcuSMState 1;
BA_ "Confidence" SG_ 1155 TCU_checkInternetFailCount 1;
BA_ "Confidence" SG_ 1155 TCU_mdmBand 1;
BA_ "Confidence" SG_ 1155 TCU_wakeSource 1;
BA_ "Confidence" SG_ 879 TPMS_learningStatus 1;
BA_ "Confidence" SG_ 879 TPMS_localisationStatus 1;
BA_ "Confidence" SG_ 879 TPMS_sensorNoResponseFL 1;
BA_ "Confidence" SG_ 879 TPMS_sensorNoResponseFR 1;
BA_ "Confidence" SG_ 879 TPMS_sensorNoResponseRL 1;
BA_ "Confidence" SG_ 879 TPMS_sensorNoResponseRR 1;
BA_ "Confidence" SG_ 879 TPMS_sensorBatteryLowFL 1;
BA_ "Confidence" SG_ 879 TPMS_sensorBatteryLowFR 1;
BA_ "Confidence" SG_ 879 TPMS_sensorBatteryLowRL 1;
BA_ "Confidence" SG_ 879 TPMS_sensorBatteryLowRR 1;
BA_ "Confidence" SG_ 879 TPMS_sensorDefectiveFL 1;
BA_ "Confidence" SG_ 879 TPMS_sensorDefectiveFR 1;
BA_ "Confidence" SG_ 879 TPMS_sensorDefectiveRL 1;
BA_ "Confidence" SG_ 879 TPMS_sensorDefectiveRR 1;
BA_ "Confidence" SG_ 879 TPMS_eolNotCompleted 1;
BA_ "Confidence" SG_ 879 TPMS_rcpFront 1;
BA_ "Confidence" SG_ 879 TPMS_rcpRear 1;
BA_ "Confidence" SG_ 802 TPMS_pressureFL 1;
BA_ "Confidence" SG_ 802 TPMS_temperatureFL 1;
BA_ "Confidence" SG_ 802 TPMS_pressureFR 1;
BA_ "Confidence" SG_ 802 TPMS_temperatureFR 1;
BA_ "Confidence" SG_ 802 TPMS_pressureRL 1;
BA_ "Confidence" SG_ 802 TPMS_temperatureRL 1;
BA_ "Confidence" SG_ 802 TPMS_pressureRR 1;
BA_ "Confidence" SG_ 802 TPMS_temperatureRR 1;
BA_ "SystemSignalLongSymbol" SG_ 1298 TRCM_a035_eventFrontRightSeatbel "TRCM_a035_eventFrontRightSeatbelt";
BA_ "SystemSignalLongSymbol" SG_ 1298 TRCM_a036_eventFrontRightSeatbel "TRCM_a036_eventFrontRightSeatbelt";
BA_ "SystemSignalLongSymbol" SG_ 1298 TRCM_a037_eventFrontRightSeatbel "TRCM_a037_eventFrontRightSeatbelt";
BA_ "SystemSignalLongSymbol" SG_ 1298 TRCM_a081_eventFrontRightSeatbel "TRCM_a081_eventFrontRightSeatbelt";
BA_ "SystemSignalLongSymbol" SG_ 1298 TRCM_a101_LIPC_externalWatchdogH "TRCM_a101_LIPC_externalWatchdogHeartBeat";
BA_ "SystemSignalLongSymbol" SG_ 1298 TRCM_a115_UI_corianderVehicleCon "TRCM_a115_UI_corianderVehicleControl";
BA_ "SystemSignalLongSymbol" SG_ 1298 TRCM_a117_VEH_intrusionSensorSta "TRCM_a117_VEH_intrusionSensorStatus";
BA_ "SystemSignalLongSymbol" SG_ 1298 TRCM_a117_PARTY_lightingSecondar "TRCM_a117_PARTY_lightingSecondary";
BA_ "SystemSignalLongSymbol" SG_ 1298 TRCM_a118_PARTY_outputPowerStatu "TRCM_a118_PARTY_outputPowerStatus";
BA_ "SystemSignalLongSymbol" SG_ 1298 TRCM_a118_VEH_interNodeResistanc "TRCM_a118_VEH_interNodeResistance";
BA_ "SystemSignalLongSymbol" SG_ 1298 TRCM_a118_PARTY_AP_vehicleState1 "TRCM_a118_PARTY_AP_vehicleState1HzMuxed";
BA_ "SystemSignalLongSymbol" SG_ 1298 TRCM_a118_BDY_AP_vehicleState1Hz "TRCM_a118_BDY_AP_vehicleState1HzMuxed";
BA_ "SystemSignalLongSymbol" SG_ 1298 TRCM_a118_PARTY_VCFRONT_cameraCl "TRCM_a118_PARTY_VCFRONT_cameraCleaningStatus";
BA_ "SystemSignalLongSymbol" SG_ 1298 TRCM_a120_VEH_aggregatedAxleSpee "TRCM_a120_VEH_aggregatedAxleSpeed";
BA_ "SystemSignalLongSymbol" SG_ 1298 TRCM_a120_PARTY_aggregatedAxleSp "TRCM_a120_PARTY_aggregatedAxleSpeed";
BA_ "SystemSignalLongSymbol" SG_ 1298 TRCM_a120_PARTY_stalklessInterfa "TRCM_a120_PARTY_stalklessInterfaces";
VAL_ 1398 TAS_endstopState 1 "TAS_DAMPING_STATE_ACTIVE" 0 "TAS_DAMPING_STATE_STANDBY" ;
VAL_ 1398 TAS_continuousControlState 1 "TAS_DAMPING_STATE_ACTIVE" 0 "TAS_DAMPING_STATE_STANDBY" ;
VAL_ 1398 TAS_activeTireTune 1 "TAS_TIRE_TUNE_MICHELIN_SUMMER_21" 0 "TAS_TIRE_TUNE_DEFAULT" ;
VAL_ 1398 TAS_roughnessRaiseReason 2 "TAS_ROUGHNESS_RAISE_REASON_LOOKAHEAD" 1 "TAS_ROUGHNESS_RAISE_REASON_LEGACY" 0 "TAS_ROUGHNESS_RAISE_REASON_NONE" ;
VAL_ 1398 TAS_frontMetricDrivesRear 3 "TAS_ACTION_ACTIVE" 2 "TAS_ACTION_ARMED" 1 "TAS_ACTION_STANDBY" 0 "TAS_ACTION_DISABLED" ;
VAL_ 1398 TAS_bellyProtect 3 "TAS_ACTION_ACTIVE" 2 "TAS_ACTION_ARMED" 1 "TAS_ACTION_STANDBY" 0 "TAS_ACTION_DISABLED" ;
VAL_ 1398 TAS_frontMetricDrivesFront 3 "TAS_ACTION_ACTIVE" 2 "TAS_ACTION_ARMED" 1 "TAS_ACTION_STANDBY" 0 "TAS_ACTION_DISABLED" ;
VAL_ 1398 TAS_speedBumpAxleFront 4 "TAS_ACTION_CANCELED" 3 "TAS_ACTION_ACTIVE" 2 "TAS_ACTION_ARMED" 1 "TAS_ACTION_STANDBY" 0 "TAS_ACTION_DISABLED" ;
VAL_ 1398 TAS_speedBumpAxleRear 4 "TAS_ACTION_CANCELED" 3 "TAS_ACTION_ACTIVE" 2 "TAS_ACTION_ARMED" 1 "TAS_ACTION_STANDBY" 0 "TAS_ACTION_DISABLED" ;
VAL_ 1398 TAS_holeProtectFL 3 "TAS_ACTION_ACTIVE" 2 "TAS_ACTION_ARMED" 1 "TAS_ACTION_STANDBY" 0 "TAS_ACTION_DISABLED" ;
VAL_ 1398 TAS_holeProtectFR 3 "TAS_ACTION_ACTIVE" 2 "TAS_ACTION_ARMED" 1 "TAS_ACTION_STANDBY" 0 "TAS_ACTION_DISABLED" ;
VAL_ 1398 TAS_holeProtectRL 3 "TAS_ACTION_ACTIVE" 2 "TAS_ACTION_ARMED" 1 "TAS_ACTION_STANDBY" 0 "TAS_ACTION_DISABLED" ;
VAL_ 1398 TAS_holeProtectRR 3 "TAS_ACTION_ACTIVE" 2 "TAS_ACTION_ARMED" 1 "TAS_ACTION_STANDBY" 0 "TAS_ACTION_DISABLED" ;
VAL_ 1398 TAS_stepProtectFL 3 "TAS_ACTION_ACTIVE" 2 "TAS_ACTION_ARMED" 1 "TAS_ACTION_STANDBY" 0 "TAS_ACTION_DISABLED" ;
VAL_ 1398 TAS_stepProtectFR 3 "TAS_ACTION_ACTIVE" 2 "TAS_ACTION_ARMED" 1 "TAS_ACTION_STANDBY" 0 "TAS_ACTION_DISABLED" ;
VAL_ 1398 TAS_stepProtectRL 3 "TAS_ACTION_ACTIVE" 2 "TAS_ACTION_ARMED" 1 "TAS_ACTION_STANDBY" 0 "TAS_ACTION_DISABLED" ;
VAL_ 1398 TAS_stepProtectRR 3 "TAS_ACTION_ACTIVE" 2 "TAS_ACTION_ARMED" 1 "TAS_ACTION_STANDBY" 0 "TAS_ACTION_DISABLED" ;
VAL_ 1357 TAS_infoBuildType 4 "INFO_MFG_BUILD" 3 "INFO_TRACEABLE_CI_BUILD" 2 "INFO_LOCAL_BUILD" 1 "INFO_PLATFORM_BUILD" 0 "INFO_UNKNOWN_BUILD" ;
VAL_ 525 TAS_levelingState 15 "LEVELING_STATE_CROSSLINK" 14 "LEVELING_STATE_QUIET_EXHAUST" 13 "LEVELING_STATE_EXHAUST_RESERVOIR" 12 "LEVELING_STATE_LOWER_SPRING_WITH_COMPRESSOR" 11 "LEVELING_STATE_LOWER_SPRING" 10 "LEVELING_STATE_FILL_SPRING_RESERVOIR_FROM_COMPRESSOR" 9 "LEVELING_STATE_FILL_SPRING_FROM_RESERVOIR" 8 "LEVELING_STATE_FILL_SPRING_FROM_BOOST" 7 "LEVELING_STATE_FILL_SPRING_FROM_COMPRESSOR" 6 "LEVELING_STATE_FILL_RESERVOIR_FROM_COMPRESSOR" 5 "LEVELING_STATE_COMPRESSOR_PREFILL_GALLERY" 4 "LEVELING_STATE_COMPRESSOR_RAMPUP" 3 "LEVELING_STATE_EXHAUST_GALLERY" 2 "LEVELING_STATE_MEASURE_SPRING_PRESSURE" 1 "LEVELING_STATE_READ_P_RESERVOIR" 0 "LEVELING_STATE_IDLE" ;
VAL_ 525 TAS_levelingItem 7 "TAS_LEVELING_ITEM_ALL" 6 "TAS_LEVELING_ITEM_REAR_AXLE" 5 "TAS_LEVELING_ITEM_FRONT_AXLE" 4 "TAS_LEVELING_ITEM_RR" 3 "TAS_LEVELING_ITEM_RL" 2 "TAS_LEVELING_ITEM_FR" 1 "TAS_LEVELING_ITEM_FL" 0 "TAS_LEVELING_ITEM_NONE" ;
VAL_ 525 TAS_runMode 7 "RUN_MODE_DYNO" 6 "RUN_MODE_LOW_POWER" 5 "RUN_MODE_NORMAL" 4 "RUN_MODE_DAN" 3 "RUN_MODE_ASSEMBLY" 2 "RUN_MODE_SERVICE" 1 "RUN_MODE_SYSTEM_CHECK" 0 "RUN_MODE_INIT" ;
VAL_ 525 TAS_filterMode 7 "MODE_STOPPING" 6 "MODE_DRIVE" 5 "MODE_LOADING" 4 "MODE_READY" 3 "MODE_TEST" 2 "MODE_CALIBRATE" 1 "MODE_INIT" 0 "MODE_NONE" ;
VAL_ 525 TAS_limpHomeMode 4 "LIMP_HOME_MODE_40" 3 "LIMP_HOME_MODE_30" 2 "LIMP_HOME_MODE_20" 1 "LIMP_HOME_MODE_10" 0 "LIMP_HOME_MODE_0" ;
VAL_ 525 TAS_targetLevel 4 "TAS_VERY_LOW" 3 "TAS_LOW" 2 "TAS_STANDARD" 1 "TAS_HIGH" 0 "TAS_VERY_HIGH" ;
VAL_ 525 TAS_currentLevel 4 "TAS_VERY_LOW" 3 "TAS_LOW" 2 "TAS_STANDARD" 1 "TAS_HIGH" 0 "TAS_VERY_HIGH" ;
VAL_ 538 TAS_adaptiveRideModeOverride 3 "TAS_ADAPTIVE_RIDE_MODE_SNA" 2 "TAS_ADAPTIVE_RIDE_MODE_SPORT" 1 "TAS_ADAPTIVE_RIDE_MODE_AUTO" 0 "TAS_ADAPTIVE_RIDE_MODE_COMFORT" ;
VAL_ 538 TAS_launchModeState 4 "TAS_LAUNCH_MODE_STATE_RAISE_SUSPENSION" 3 "TAS_LAUNCH_MODE_STATE_READY" 2 "TAS_LAUNCH_MODE_STATE_LOWER_SUSPENSION" 1 "TAS_LAUNCH_MODE_STATE_IDLE" 0 "TAS_LAUNCH_MODE_STATE_BLOCKED" ;
VAL_ 1415 TCU2_tc10Version 2 "TCU_tc10Version_FINAL_1_0" 1 "TCU_tc10Version_DRAFT" ;
VAL_ 1412 TCU2_mdmDataRat 6 "RAT_NR5G_UNKNOWN" 5 "RAT_NR5G_SA" 4 "RAT_NR5G_NSA" 3 "RAT_LTE" 2 "RAT_WCDMA" 1 "RAT_GSM" 0 "RAT_UNKNOWN" ;
VAL_ 1412 TCU2_mdmDataCallStatus 4 "DISCONNECTED" 3 "DISCONNECTING" 2 "CONNECTED" 1 "CONNECTING" 0 "UNKNOWN" ;
VAL_ 1412 TCU2_mdmNSAAvailable 2 "NSA_NOT_AVAILABLE" 1 "NSA_AVAILABLE" 0 "NSA_UNKNOWN" ;
VAL_ 1412 TCU2_cellularSMState 7 "RECOVERING" 6 "LINK_CONNECTED" 5 "CHECKING_INTERNET" 4 "DATA_CONNECTED" 3 "IN_SERVICE" 2 "OUT_OF_SERVICE" 1 "WAITING_COMPONENT" 0 "UNKNOWN" ;
VAL_ 1412 TCU2_tcuSMState 7 "UPDATING" 6 "RESUMING" 5 "SUSPENDED" 4 "PREPARING_SLEEP" 3 "POWER_CYCLING" 2 "IN_OPERATION" 1 "SEARCHING_COMPONENT" 0 "UNKNOWN" ;
VAL_ 1412 TCU2_wakeSource 3 "ETHERNET" 2 "WOIP" 1 "SMS" 0 "NONE" ;
VAL_ 1159 TCU_tc10Version 2 "TCU_tc10Version_FINAL_1_0" 1 "TCU_tc10Version_DRAFT" ;
VAL_ 1155 TCU_mdmDataRat 6 "RAT_NR5G_UNKNOWN" 5 "RAT_NR5G_SA" 4 "RAT_NR5G_NSA" 3 "RAT_LTE" 2 "RAT_WCDMA" 1 "RAT_GSM" 0 "RAT_UNKNOWN" ;
VAL_ 1155 TCU_mdmDataCallStatus 4 "DISCONNECTED" 3 "DISCONNECTING" 2 "CONNECTED" 1 "CONNECTING" 0 "UNKNOWN" ;
VAL_ 1155 TCU_mdmNSAAvailable 2 "NSA_NOT_AVAILABLE" 1 "NSA_AVAILABLE" 0 "NSA_UNKNOWN" ;
VAL_ 1155 TCU_cellularSMState 7 "RECOVERING" 6 "LINK_CONNECTED" 5 "CHECKING_INTERNET" 4 "DATA_CONNECTED" 3 "IN_SERVICE" 2 "OUT_OF_SERVICE" 1 "WAITING_COMPONENT" 0 "UNKNOWN" ;
VAL_ 1155 TCU_tcuSMState 7 "UPDATING" 6 "RESUMING" 5 "SUSPENDED" 4 "PREPARING_SLEEP" 3 "POWER_CYCLING" 2 "IN_OPERATION" 1 "SEARCHING_COMPONENT" 0 "UNKNOWN" ;
VAL_ 1155 TCU_wakeSource 3 "ETHERNET" 2 "WOIP" 1 "SMS" 0 "NONE" ;
VAL_ 879 TPMS_learningStatus 3 "PASSED" 2 "STOPPED" 1 "ONGOING" 0 "FAILED" ;
VAL_ 879 TPMS_localisationStatus 3 "PASSED" 2 "STOPPED" 1 "ONGOING" 0 "FAILED" ;
